VERSION ""

NS_ :

BS_:

BU_: Vector__XXX

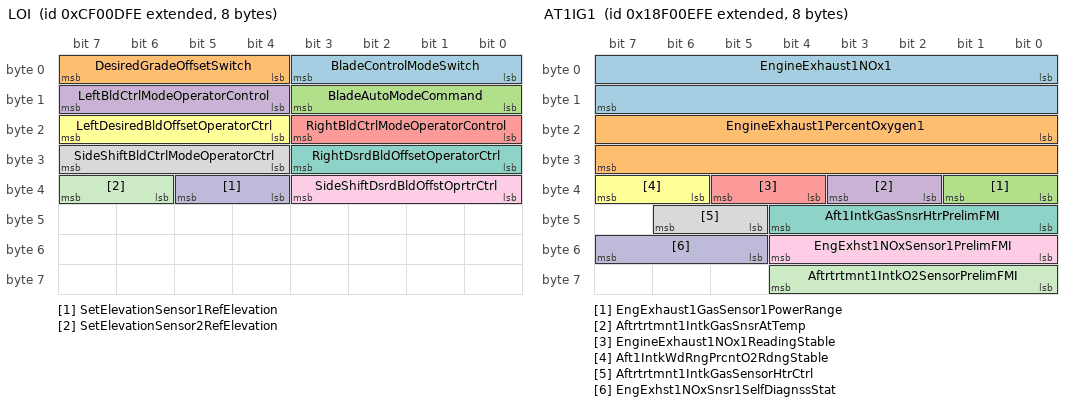
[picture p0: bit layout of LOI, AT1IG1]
BO_ 2364542462 LOI: 8 Vector__XXX
SG_ BladeControlModeSwitch : 0|4@1+ (1,0) [0|15] "" Vector__XXX
SG_ DesiredGradeOffsetSwitch : 4|4@1+ (1,0) [0|15] "" Vector__XXX
SG_ BladeAutoModeCommand : 8|4@1+ (1,0) [0|15] "" Vector__XXX
SG_ LeftBldCtrlModeOperatorControl : 12|4@1+ (1,0) [0|15] "" Vector__XXX
SG_ RightBldCtrlModeOperatorControl : 16|4@1+ (1,0) [0|15] "" Vector__XXX
SG_ LeftDesiredBldOffsetOperatorCtrl : 20|4@1+ (1,0) [0|15] "" Vector__XXX
SG_ RightDsrdBldOffsetOperatorCtrl : 24|4@1+ (1,0) [0|15] "" Vector__XXX
SG_ SideShiftBldCtrlModeOperatorCtrl : 28|4@1+ (1,0) [0|15] "" Vector__XXX
SG_ SideShiftDsrdBldOffstOprtrCtrl : 32|4@1+ (1,0) [0|15] "" Vector__XXX
SG_ SetElevationSensor1RefElevation : 36|2@1+ (1,0) [0|3] "" Vector__XXX
SG_ SetElevationSensor2RefElevation : 38|2@1+ (1,0) [0|3] "" Vector__XXX

BO_ 2565869310 AT1IG1: 8 Vector__XXX
SG_ EngineExhaust1NOx1 : 0|16@1+ (0.05,-200) [-200|3012.75] "ppm" Vector__XXX
SG_ EngineExhaust1PercentOxygen1 : 16|16@1+ (0.000514,-12) [-12|21.02707] "%" Vector__XXX
SG_ EngExhaust1GasSensor1PowerRange : 32|2@1+ (1,0) [0|3] "" Vector__XXX
SG_ Aftrtrtmnt1IntkGasSnsrAtTemp : 34|2@1+ (1,0) [0|3] "" Vector__XXX
SG_ EngineExhaust1NOx1ReadingStable : 36|2@1+ (1,0) [0|3] "" Vector__XXX
SG_ Aft1IntkWdRngPrcntO2RdngStable : 38|2@1+ (1,0) [0|3] "" Vector__XXX
SG_ Aft1IntkGasSnsrHtrPrelimFMI : 40|5@1+ (1,0) [0|31] "" Vector__XXX
SG_ Aftrtrtmnt1IntkGasSensorHtrCtrl : 45|2@1+ (1,0) [0|3] "" Vector__XXX
SG_ EngExhst1NOxSensor1PrelimFMI : 48|5@1+ (1,0) [0|31] "" Vector__XXX
SG_ EngExhst1NOxSnsr1SelfDiagnssStat : 53|3@1+ (1,0) [0|7] "" Vector__XXX
SG_ Aftrtrtmnt1IntkO2SensorPrelimFMI : 56|5@1+ (1,0) [0|31] "" Vector__XXX

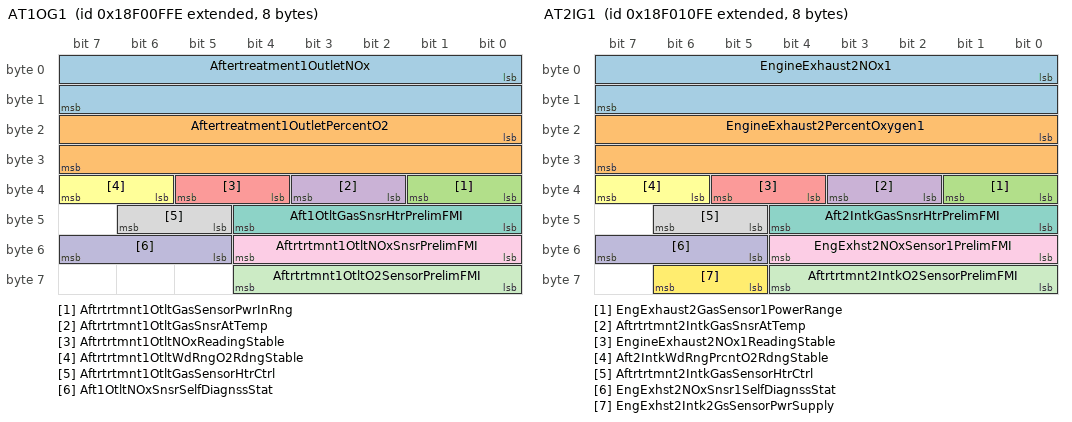
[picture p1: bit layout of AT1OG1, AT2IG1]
BO_ 2565869566 AT1OG1: 8 Vector__XXX
SG_ Aftertreatment1OutletNOx : 0|16@1+ (0.05,-200) [-200|3012.75] "ppm" Vector__XXX
SG_ Aftertreatment1OutletPercentO2 : 16|16@1+ (0.000514,-12) [-12|21.02707] "%" Vector__XXX
SG_ Aftrtrtmnt1OtltGasSensorPwrInRng : 32|2@1+ (1,0) [0|3] "" Vector__XXX
SG_ Aftrtrtmnt1OtltGasSnsrAtTemp : 34|2@1+ (1,0) [0|3] "" Vector__XXX
SG_ Aftrtrtmnt1OtltNOxReadingStable : 36|2@1+ (1,0) [0|3] "" Vector__XXX
SG_ Aftrtrtmnt1OtltWdRngO2RdngStable : 38|2@1+ (1,0) [0|3] "" Vector__XXX
SG_ Aft1OtltGasSnsrHtrPrelimFMI : 40|5@1+ (1,0) [0|31] "" Vector__XXX
SG_ Aftrtrtmnt1OtltGasSensorHtrCtrl : 45|2@1+ (1,0) [0|3] "" Vector__XXX
SG_ Aftrtrtmnt1OtltNOxSnsrPrelimFMI : 48|5@1+ (1,0) [0|31] "" Vector__XXX
SG_ Aft1OtltNOxSnsrSelfDiagnssStat : 53|3@1+ (1,0) [0|7] "" Vector__XXX
SG_ Aftrtrtmnt1OtltO2SensorPrelimFMI : 56|5@1+ (1,0) [0|31] "" Vector__XXX

BO_ 2565869822 AT2IG1: 8 Vector__XXX
SG_ EngineExhaust2NOx1 : 0|16@1+ (0.05,-200) [-200|3012.75] "ppm" Vector__XXX
SG_ EngineExhaust2PercentOxygen1 : 16|16@1+ (0.000514,-12) [-12|21.02707] "%" Vector__XXX
SG_ EngExhaust2GasSensor1PowerRange : 32|2@1+ (1,0) [0|3] "" Vector__XXX
SG_ Aftrtrtmnt2IntkGasSnsrAtTemp : 34|2@1+ (1,0) [0|3] "" Vector__XXX
SG_ EngineExhaust2NOx1ReadingStable : 36|2@1+ (1,0) [0|3] "" Vector__XXX
SG_ Aft2IntkWdRngPrcntO2RdngStable : 38|2@1+ (1,0) [0|3] "" Vector__XXX
SG_ Aft2IntkGasSnsrHtrPrelimFMI : 40|5@1+ (1,0) [0|31] "" Vector__XXX
SG_ Aftrtrtmnt2IntkGasSensorHtrCtrl : 45|2@1+ (1,0) [0|3] "" Vector__XXX
SG_ EngExhst2NOxSensor1PrelimFMI : 48|5@1+ (1,0) [0|31] "" Vector__XXX
SG_ EngExhst2NOxSnsr1SelfDiagnssStat : 53|3@1+ (1,0) [0|7] "" Vector__XXX
SG_ Aftrtrtmnt2IntkO2SensorPrelimFMI : 56|5@1+ (1,0) [0|31] "" Vector__XXX
SG_ EngExhst2Intk2GsSensorPwrSupply : 61|2@1+ (1,0) [0|3] "" Vector__XXX

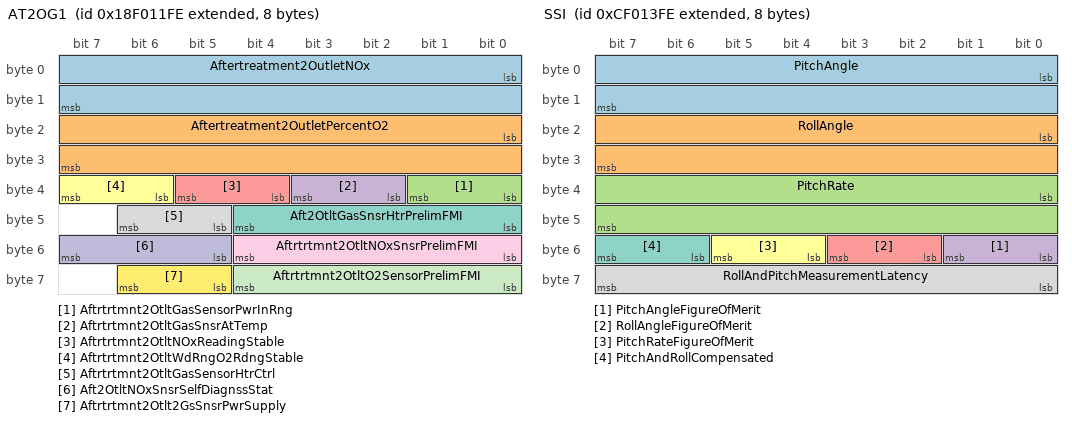
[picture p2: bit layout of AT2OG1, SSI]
BO_ 2565870078 AT2OG1: 8 Vector__XXX
SG_ Aftertreatment2OutletNOx : 0|16@1+ (0.05,-200) [-200|3012.75] "ppm" Vector__XXX
SG_ Aftertreatment2OutletPercentO2 : 16|16@1+ (0.000514,-12) [-12|21.02707] "%" Vector__XXX
SG_ Aftrtrtmnt2OtltGasSensorPwrInRng : 32|2@1+ (1,0) [0|3] "" Vector__XXX
SG_ Aftrtrtmnt2OtltGasSnsrAtTemp : 34|2@1+ (1,0) [0|3] "" Vector__XXX
SG_ Aftrtrtmnt2OtltNOxReadingStable : 36|2@1+ (1,0) [0|3] "" Vector__XXX
SG_ Aftrtrtmnt2OtltWdRngO2RdngStable : 38|2@1+ (1,0) [0|3] "" Vector__XXX
SG_ Aft2OtltGasSnsrHtrPrelimFMI : 40|5@1+ (1,0) [0|31] "" Vector__XXX
SG_ Aftrtrtmnt2OtltGasSensorHtrCtrl : 45|2@1+ (1,0) [0|3] "" Vector__XXX
SG_ Aftrtrtmnt2OtltNOxSnsrPrelimFMI : 48|5@1+ (1,0) [0|31] "" Vector__XXX
SG_ Aft2OtltNOxSnsrSelfDiagnssStat : 53|3@1+ (1,0) [0|7] "" Vector__XXX
SG_ Aftrtrtmnt2OtltO2SensorPrelimFMI : 56|5@1+ (1,0) [0|31] "" Vector__XXX
SG_ Aftrtrtmnt2Otlt2GsSnsrPwrSupply : 61|2@1+ (1,0) [0|3] "" Vector__XXX

BO_ 2565870334 FWSS1: 8 Vector__XXX
SG_ FifthWheelVerticalForce : 0|16@1+ (5,0) [0|321275] "N" Vector__XXX
SG_ FifthWheelDrawbarForce : 16|16@1+ (10,-320000) [-320000|322550] "N" Vector__XXX
SG_ FifthWheelRollMoment : 32|16@1+ (10,-320000) [-320000|322550] "N" Vector__XXX
SG_ FifthWheelRollWarningIndicator : 48|2@1+ (1,0) [0|3] "" Vector__XXX

BO_ 2364543998 SSI: 8 Vector__XXX
SG_ PitchAngle : 0|16@1+ (0.002,-64) [-64|64.51] "deg" Vector__XXX
SG_ RollAngle : 16|16@1+ (0.002,-64) [-64|64.51] "deg" Vector__XXX
SG_ PitchRate : 32|16@1+ (0.002,-64) [-64|64.51] "deg/s" Vector__XXX
SG_ PitchAngleFigureOfMerit : 48|2@1+ (1,0) [0|3] "" Vector__XXX
SG_ RollAngleFigureOfMerit : 50|2@1+ (1,0) [0|3] "" Vector__XXX
SG_ PitchRateFigureOfMerit : 52|2@1+ (1,0) [0|3] "" Vector__XXX
SG_ PitchAndRollCompensated : 54|2@1+ (1,0) [0|3] "" Vector__XXX
SG_ RollAndPitchMeasurementLatency : 56|8@1+ (0.5,0) [0|125] "ms" Vector__XXX

BO_ 2364544254 BI: 8 Vector__XXX
SG_ RelativeBladeHeight : 0|16@1+ (0.1,-3200) [-3200|3225.5] "mm" Vector__XXX
SG_ BladeRotationAngle : 16|16@1+ (0.0078125,-200) [-200|301.99] "deg" Vector__XXX
SG_ RelBldHghtAndBldRotAglMeasureLat : 32|8@1+ (0.5,0) [0|125] "ms" Vector__XXX
SG_ RelativeBladeHeightFigureOfMerit : 40|2@1+ (1,0) [0|3] "" Vector__XXX
SG_ BladeRotationAngleFigureOfMerit : 42|2@1+ (1,0) [0|3] "" Vector__XXX

BO_ 2364544510 RGTACRP: 8 Vector__XXX
SG_ RequestedGenTotalACReActvPower : 0|32@1+ (1,-2000000000) [-2000000000|2211081215] "VA" Vector__XXX
SG_ RequestedGenOverallPowerFactor : 32|16@1+ (6.103515625E-005,-1) [-1|2.921814] "" Vector__XXX
SG_ RqedGenOverallPwrFactorLagging : 48|2@1+ (1,0) [0|3] "" Vector__XXX

BO_ 2364544766 CCS: 8 Vector__XXX
SG_ EngineCylinder1CombustionStatus : 0|2@1+ (1,0) [0|3] "" Vector__XXX
SG_ EngineCylinder2CombustionStatus : 2|2@1+ (1,0) [0|3] "" Vector__XXX
SG_ EngineCylinder3CombustionStatus : 4|2@1+ (1,0) [0|3] "" Vector__XXX
SG_ EngineCylinder4CombustionStatus : 6|2@1+ (1,0) [0|3] "" Vector__XXX
SG_ EngineCylinder5CombustionStatus : 8|2@1+ (1,0) [0|3] "" Vector__XXX
SG_ EngineCylinder6CombustionStatus : 10|2@1+ (1,0) [0|3] "" Vector__XXX
SG_ EngineCylinder7CombustionStatus : 12|2@1+ (1,0) [0|3] "" Vector__XXX
SG_ EngineCylinder8CombustionStatus : 14|2@1+ (1,0) [0|3] "" Vector__XXX
SG_ EngineCylinder9CombustionStatus : 16|2@1+ (1,0) [0|3] "" Vector__XXX
SG_ EngineCylinder10CombustionStatus : 18|2@1+ (1,0) [0|3] "" Vector__XXX
SG_ EngineCylinder11CombustionStatus : 20|2@1+ (1,0) [0|3] "" Vector__XXX
SG_ EngineCylinder12CombustionStatus : 22|2@1+ (1,0) [0|3] "" Vector__XXX
SG_ EngineCylinder13CombustionStatus : 24|2@1+ (1,0) [0|3] "" Vector__XXX
SG_ EngineCylinder14CombustionStatus : 26|2@1+ (1,0) [0|3] "" Vector__XXX
SG_ EngineCylinder15CombustionStatus : 28|2@1+ (1,0) [0|3] "" Vector__XXX
SG_ EngineCylinder16CombustionStatus : 30|2@1+ (1,0) [0|3] "" Vector__XXX
SG_ EngineCylinder17CombustionStatus : 32|2@1+ (1,0) [0|3] "" Vector__XXX
SG_ EngineCylinder18CombustionStatus : 34|2@1+ (1,0) [0|3] "" Vector__XXX
SG_ EngineCylinder19CombustionStatus : 36|2@1+ (1,0) [0|3] "" Vector__XXX
SG_ EngineCylinder20CombustionStatus : 38|2@1+ (1,0) [0|3] "" Vector__XXX
SG_ EngineCylinder21CombustionStatus : 40|2@1+ (1,0) [0|3] "" Vector__XXX
SG_ EngineCylinder22CombustionStatus : 42|2@1+ (1,0) [0|3] "" Vector__XXX
SG_ EngineCylinder23CombustionStatus : 44|2@1+ (1,0) [0|3] "" Vector__XXX
SG_ EngineCylinder24CombustionStatus : 46|2@1+ (1,0) [0|3] "" Vector__XXX

BO_ 2364545022 KL1: 8 Vector__XXX
SG_ EngineCylinder1KnockLevel : 0|8@1+ (1,0) [0|250] "%" Vector__XXX
SG_ EngineCylinder2KnockLevel : 8|8@1+ (1,0) [0|250] "%" Vector__XXX
SG_ EngineCylinder3KnockLevel : 16|8@1+ (1,0) [0|250] "%" Vector__XXX
SG_ EngineCylinder4KnockLevel : 24|8@1+ (1,0) [0|250] "%" Vector__XXX
SG_ EngineCylinder5KnockLevel : 32|8@1+ (1,0) [0|250] "%" Vector__XXX
SG_ EngineCylinder6KnockLevel : 40|8@1+ (1,0) [0|250] "%" Vector__XXX
SG_ EngineCylinder7KnockLevel : 48|8@1+ (1,0) [0|250] "%" Vector__XXX
SG_ EngineCylinder8KnockLevel : 56|8@1+ (1,0) [0|250] "%" Vector__XXX

BO_ 2364545278 KL2: 8 Vector__XXX
SG_ EngineCylinder9KnockLevel : 0|8@1+ (1,0) [0|250] "%" Vector__XXX
SG_ EngineCylinder10KnockLevel : 8|8@1+ (1,0) [0|250] "%" Vector__XXX
SG_ EngineCylinder11KnockLevel : 16|8@1+ (1,0) [0|250] "%" Vector__XXX
SG_ EngineCylinder12KnockLevel : 24|8@1+ (1,0) [0|250] "%" Vector__XXX
SG_ EngineCylinder13KnockLevel : 32|8@1+ (1,0) [0|250] "%" Vector__XXX
SG_ EngineCylinder14KnockLevel : 40|8@1+ (1,0) [0|250] "%" Vector__XXX
SG_ EngineCylinder15KnockLevel : 48|8@1+ (1,0) [0|250] "%" Vector__XXX
SG_ EngineCylinder16KnockLevel : 56|8@1+ (1,0) [0|250] "%" Vector__XXX

BO_ 2364545534 KL3: 8 Vector__XXX
SG_ EngineCylinder17KnockLevel : 0|8@1+ (1,0) [0|250] "%" Vector__XXX
SG_ EngineCylinder18KnockLevel : 8|8@1+ (1,0) [0|250] "%" Vector__XXX
SG_ EngineCylinder19KnockLevel : 16|8@1+ (1,0) [0|250] "%" Vector__XXX
SG_ EngineCylinder20KnockLevel : 24|8@1+ (1,0) [0|250] "%" Vector__XXX
SG_ EngineCylinder21KnockLevel : 32|8@1+ (1,0) [0|250] "%" Vector__XXX
SG_ EngineCylinder22KnockLevel : 40|8@1+ (1,0) [0|250] "%" Vector__XXX
SG_ EngineCylinder23KnockLevel : 48|8@1+ (1,0) [0|250] "%" Vector__XXX
SG_ EngineCylinder24KnockLevel : 56|8@1+ (1,0) [0|250] "%" Vector__XXX

BO_ 2431654654 TFAC: 8 Vector__XXX
SG_ EngineThrottleActr1ControlCmd : 0|16@1+ (0.0025,0) [0|160.6375] "%" Vector__XXX
SG_ EngineThrottleActr2ControlCmd : 16|16@1+ (0.0025,0) [0|160.6375] "%" Vector__XXX
SG_ EngineFuelActr1ControlCommand : 32|16@1+ (0.0025,0) [0|160.6375] "%" Vector__XXX
SG_ EngineFuelActr2ControlCommand : 48|16@1+ (0.0025,0) [0|160.6375] "%" Vector__XXX

BO_ 2364546302 RGAAC: 8 Vector__XXX
SG_ RqedGenAvrgLineLineACRMSVoltage : 0|32@1+ (0.0078125,0) [0|32899071] "V" Vector__XXX

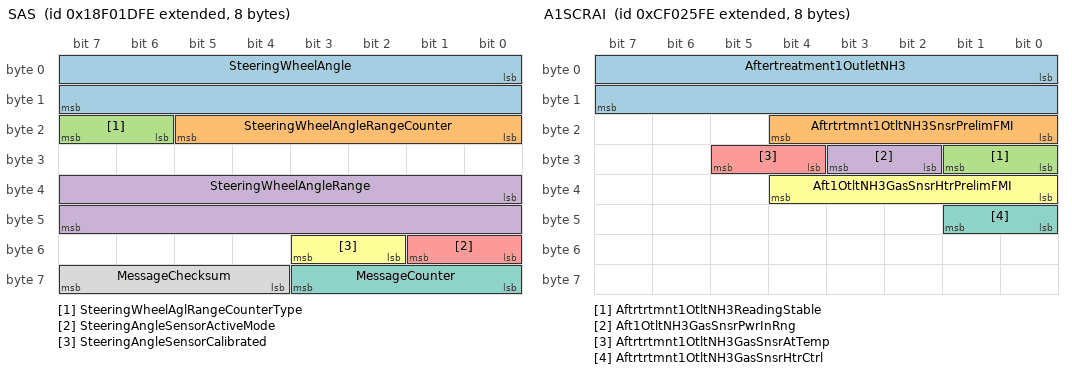
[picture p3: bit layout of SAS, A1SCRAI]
BO_ 2565873150 SAS: 8 Vector__XXX
SG_ SteeringWheelAngle : 0|16@1+ (0.0009765625,-31.374) [-31.374|31.374] "rad" Vector__XXX
SG_ SteeringWheelAngleRangeCounter : 16|6@1+ (1,-32) [-32|29] "" Vector__XXX
SG_ SteeringWheelAglRangeCounterType : 22|2@1+ (1,0) [0|3] "" Vector__XXX
SG_ SteeringWheelAngleRange : 32|16@1+ (0.0009765625,-31.374) [-31.374|31.374] "rad" Vector__XXX
SG_ SteeringAngleSensorActiveMode : 48|2@1+ (1,0) [0|3] "" Vector__XXX
SG_ SteeringAngleSensorCalibrated : 50|2@1+ (1,0) [0|3] "" Vector__XXX
SG_ MessageCounter : 56|4@1+ (1,0) [0|15] "" Vector__XXX
SG_ MessageChecksum : 60|4@1+ (1,0) [0|15] "" Vector__XXX

BO_ 2364546814 GC2: 8 Vector__XXX
SG_ GeneratorGoverningBias : 0|16@1+ (0.004,-125) [-125|132.02] "%" Vector__XXX
SG_ EngineSelfInducedDerateInhibit : 16|2@1+ (1,0) [0|3] "" Vector__XXX
SG_ EngineLoadSetpointRequest : 24|16@1+ (0.5,0) [0|32127.5] "kW" Vector__XXX

BO_ 2565874174 ESSI1: 8 Vector__XXX
SG_ EngineSpeed1 : 0|16@1+ (0.5,0) [0|32127.5] "rpm" Vector__XXX
SG_ EngineSpeed2 : 16|16@1+ (0.5,0) [0|32127.5] "rpm" Vector__XXX
SG_ EngineSpeed3 : 32|16@1+ (0.5,0) [0|32127.5] "rpm" Vector__XXX
SG_ EngSpeedSnsr3TimingPatternStatus : 50|2@1+ (1,0) [0|3] "" Vector__XXX
SG_ EngSpeedSnsr2TimingPatternStatus : 52|2@1+ (1,0) [0|3] "" Vector__XXX
SG_ EngSpeedSnsr1TimingPatternStatus : 54|2@1+ (1,0) [0|3] "" Vector__XXX

BO_ 2565874430 MSS: 8 Vector__XXX
SG_ MachineSelectedSpeed : 0|16@1+ (0.001,0) [0|64.255] "m/s" Vector__XXX
SG_ MachineSelectedDistance : 16|32@1+ (0.001,0) [0|4211081.215] "m" Vector__XXX
SG_ MachineSelectedDirection : 56|2@1+ (1,0) [0|3] "" Vector__XXX
SG_ MachineSelectedSpeedSource : 58|3@1+ (1,0) [0|7] "" Vector__XXX
SG_ PersistentLimitStatus : 61|3@1+ (1,0) [0|7] "" Vector__XXX

BO_ 2364548094 A1SCRDSI1: 8 Vector__XXX
SG_ Aft1DslExhstFldActlDsngQty : 0|16@1+ (0.3,0) [0|19276.5] "g/h" Vector__XXX
SG_ Aftertreatment1SCRSystemState : 16|4@1+ (1,0) [0|15] "" Vector__XXX
SG_ Aftertreatment1SCRSystem2State : 20|4@1+ (1,0) [0|15] "" Vector__XXX
SG_ Aft1DslExhstFldActlQtyOfIntgrtr : 24|16@1+ (0.1,0) [0|6425.5] "g" Vector__XXX
SG_ Aft1DslExhstFldDoserAbsPress : 40|8@1+ (8,0) [0|2000] "kPa" Vector__XXX
SG_ Aft1DslExhstFldActlDsngQtyHiRng : 48|16@1+ (0.05,0) [0|3212.75] "g/m" Vector__XXX

BO_ 2364548350 A1SCRDSR1: 8 Vector__XXX
SG_ Aft1DslExhstFldDsngRqedQty : 0|16@1+ (0.3,0) [0|19276.5] "g/h" Vector__XXX
SG_ Aftrtrtmnt1SCRSystemRqedState : 16|4@1+ (1,0) [0|15] "" Vector__XXX
SG_ Aft1DslExhstFldHydrStffnssCkPmSt : 20|2@1+ (1,0) [0|3] "" Vector__XXX
SG_ Aft1DslExhstFldDsngTtInjectPmSt : 22|2@1+ (1,0) [0|3] "" Vector__XXX
SG_ Aft1DslExhstFldRqedQtyOfIntgrtr : 24|16@1+ (0.1,0) [0|6425.5] "g" Vector__XXX
SG_ Aft1DslExhstFldDsngRqedQtyHiRng : 40|16@1+ (0.05,0) [0|3212.75] "g/m" Vector__XXX

BO_ 2364548606 A1SCRAI: 8 Vector__XXX
SG_ Aftertreatment1OutletNH3 : 0|16@1+ (0.05,-200) [-200|3012.75] "ppm" Vector__XXX
SG_ Aftrtrtmnt1OtltNH3SnsrPrelimFMI : 16|5@1+ (1,0) [0|31] "" Vector__XXX
SG_ Aftrtrtmnt1OtltNH3ReadingStable : 24|2@1+ (1,0) [0|3] "" Vector__XXX
SG_ Aft1OtltNH3GasSnsrPwrInRng : 26|2@1+ (1,0) [0|3] "" Vector__XXX
SG_ Aftrtrtmnt1OtltNH3GasSnsrAtTemp : 28|2@1+ (1,0) [0|3] "" Vector__XXX
SG_ Aft1OtltNH3GasSnsrHtrPrelimFMI : 32|5@1+ (1,0) [0|31] "" Vector__XXX
SG_ Aftrtrtmnt1OtltNH3GasSnsrHtrCtrl : 40|2@1+ (1,0) [0|3] "" Vector__XXX

BO_ 2364548862 A2SCRDSI1: 8 Vector__XXX
SG_ Aft2DslExhstFldActlDsngQty : 0|16@1+ (0.3,0) [0|19276.5] "g/h" Vector__XXX
SG_ Aftertreatment2SCRSystemState : 16|4@1+ (1,0) [0|15] "" Vector__XXX
SG_ Aftertreatment2SCRSystem2State : 20|4@1+ (1,0) [0|15] "" Vector__XXX
SG_ Aft2DslExhstFldActlQtyOfIntgrtr : 24|16@1+ (0.1,0) [0|6425.5] "g" Vector__XXX
SG_ Aft2DslExhstFldDsngAbsPress : 40|8@1+ (8,0) [0|2000] "kPa" Vector__XXX
SG_ Aft2DslExhstFldActlDsngQtyHiRng : 48|16@1+ (0.05,0) [0|3212.75] "g/m" Vector__XXX

BO_ 2364549118 A2SCRDSR1: 8 Vector__XXX
SG_ Aft2DslExhstFldDsngRqedQty : 0|16@1+ (0.3,0) [0|19276.5] "g/h" Vector__XXX
SG_ Aftrtrtmnt2SCRSystemRqedState : 16|4@1+ (1,0) [0|15] "" Vector__XXX
SG_ Aft2DslExhstFldHydrStffnssCkPmSt : 20|2@1+ (1,0) [0|3] "" Vector__XXX
SG_ Aft2DslExhstFldDsngTtInjectPmSt : 22|2@1+ (1,0) [0|3] "" Vector__XXX
SG_ Aft2DslExhstFldRqedQtyOfIntgrtr : 24|16@1+ (0.1,0) [0|6425.5] "g" Vector__XXX
SG_ Aft2DslExhstFldDsngRqedQtyHiRng : 40|16@1+ (0.05,0) [0|3212.75] "g/m" Vector__XXX
SG_ Aftrtrtmnt2DslExhstFldPumpHtrCmd : 56|8@1+ (0.4,0) [0|100] "%" Vector__XXX

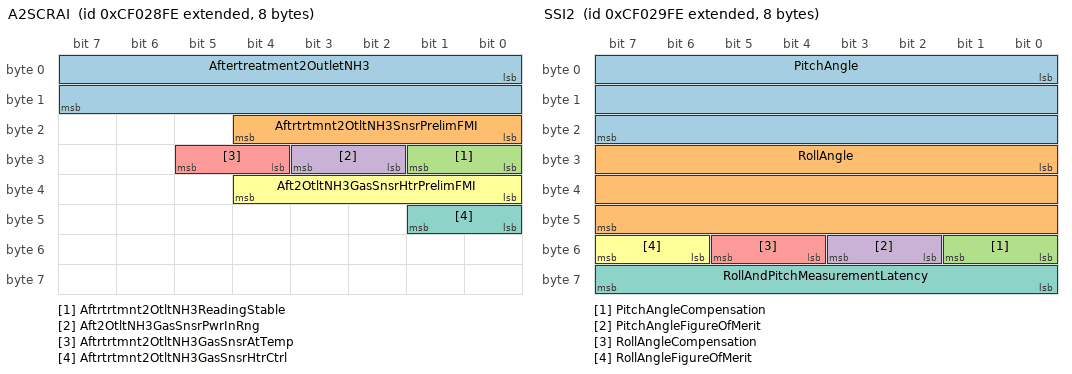
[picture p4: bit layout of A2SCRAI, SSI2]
BO_ 2364549374 A2SCRAI: 8 Vector__XXX
SG_ Aftertreatment2OutletNH3 : 0|16@1+ (0.05,-200) [-200|3012.75] "ppm" Vector__XXX
SG_ Aftrtrtmnt2OtltNH3SnsrPrelimFMI : 16|5@1+ (1,0) [0|31] "" Vector__XXX
SG_ Aftrtrtmnt2OtltNH3ReadingStable : 24|2@1+ (1,0) [0|3] "" Vector__XXX
SG_ Aft2OtltNH3GasSnsrPwrInRng : 26|2@1+ (1,0) [0|3] "" Vector__XXX
SG_ Aftrtrtmnt2OtltNH3GasSnsrAtTemp : 28|2@1+ (1,0) [0|3] "" Vector__XXX
SG_ Aft2OtltNH3GasSnsrHtrPrelimFMI : 32|5@1+ (1,0) [0|31] "" Vector__XXX
SG_ Aftrtrtmnt2OtltNH3GasSnsrHtrCtrl : 40|2@1+ (1,0) [0|3] "" Vector__XXX

BO_ 2364549630 SSI2: 8 Vector__XXX
SG_ PitchAngle : 0|24@1+ (3.0517578125E-005,-250) [-250|252] "deg" Vector__XXX
SG_ RollAngle : 24|24@1+ (3.0517578125E-005,-250) [-250|252] "deg" Vector__XXX
SG_ PitchAngleCompensation : 48|2@1+ (1,0) [0|3] "" Vector__XXX
SG_ PitchAngleFigureOfMerit : 50|2@1+ (1,0) [0|3] "" Vector__XXX
SG_ RollAngleCompensation : 52|2@1+ (1,0) [0|3] "" Vector__XXX
SG_ RollAngleFigureOfMerit : 54|2@1+ (1,0) [0|3] "" Vector__XXX
SG_ RollAndPitchMeasurementLatency : 56|8@1+ (0.5,0) [0|125] "ms" Vector__XXX

BO_ 2364549886 ARI: 8 Vector__XXX
SG_ PitchRate : 0|16@1+ (0.0078125,-250) [-250|250.992] "deg/s" Vector__XXX
SG_ RollRate : 16|16@1+ (0.0078125,-250) [-250|250.992] "deg/s" Vector__XXX
SG_ YawRate : 32|16@1+ (0.0078125,-250) [-250|250.992] "deg/s" Vector__XXX
SG_ PitchRateFigureOfMerit : 48|2@1+ (1,0) [0|3] "" Vector__XXX
SG_ RollRateFigureOfMerit : 50|2@1+ (1,0) [0|3] "" Vector__XXX
SG_ YawRateFigureOfMerit : 52|2@1+ (1,0) [0|3] "" Vector__XXX
SG_ AngularRateMeasurementLatency : 56|8@1+ (0.5,0) [0|125] "ms" Vector__XXX

BO_ 2163223550 CN: 8 Vector__XXX
SG_ CrashType : 0|5@1+ (1,0) [0|31] "" Vector__XXX
SG_ CrashCounter : 56|4@1+ (1,0) [0|15] "" Vector__XXX
SG_ CrashChecksum : 60|4@1+ (1,0) [0|15] "" Vector__XXX

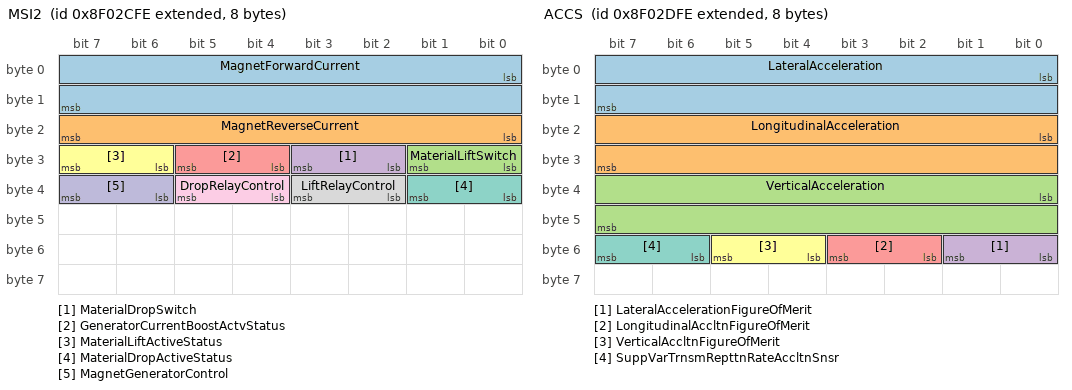
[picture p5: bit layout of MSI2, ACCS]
BO_ 2297441534 MSI2: 8 Vector__XXX
SG_ MagnetForwardCurrent : 0|16@1+ (1,0) [0|64255] "A" Vector__XXX
SG_ MagnetReverseCurrent : 16|8@1+ (1,0) [0|250] "A" Vector__XXX
SG_ MaterialLiftSwitch : 24|2@1+ (1,0) [0|3] "" Vector__XXX
SG_ MaterialDropSwitch : 26|2@1+ (1,0) [0|3] "" Vector__XXX
SG_ GeneratorCurrentBoostActvStatus : 28|2@1+ (1,0) [0|3] "" Vector__XXX
SG_ MaterialLiftActiveStatus : 30|2@1+ (1,0) [0|3] "" Vector__XXX
SG_ MaterialDropActiveStatus : 32|2@1+ (1,0) [0|3] "" Vector__XXX
SG_ LiftRelayControl : 34|2@1+ (1,0) [0|3] "" Vector__XXX
SG_ DropRelayControl : 36|2@1+ (1,0) [0|3] "" Vector__XXX
SG_ MagnetGeneratorControl : 38|2@1+ (1,0) [0|3] "" Vector__XXX

BO_ 2297441790 ACCS: 8 Vector__XXX
SG_ LateralAcceleration : 0|16@1+ (0.01,-320) [-320|322.55] "m/s^2" Vector__XXX
SG_ LongitudinalAcceleration : 16|16@1+ (0.01,-320) [-320|322.55] "m/s^2" Vector__XXX
SG_ VerticalAcceleration : 32|16@1+ (0.01,-320) [-320|322.55] "m/s^2" Vector__XXX
SG_ LateralAccelerationFigureOfMerit : 48|2@1+ (1,0) [0|3] "" Vector__XXX
SG_ LongitudinalAccltnFigureOfMerit : 50|2@1+ (1,0) [0|3] "" Vector__XXX
SG_ VerticalAccltnFigureOfMerit : 52|2@1+ (1,0) [0|3] "" Vector__XXX
SG_ SuppVarTrnsmRepttnRateAccltnSnsr : 54|2@1+ (1,0) [0|3] "" Vector__XXX

BO_ 2565877502 ETCC: 8 Vector__XXX
SG_ EngTurbochargerWastegateActr1Cmd : 0|16@1+ (0.0025,0) [0|160.6375] "%" Vector__XXX
SG_ EngTurbochargerWastegateActr2Cmd : 16|16@1+ (0.0025,0) [0|160.6375] "%" Vector__XXX
SG_ EngExhstPressureRegulatorCtrlCmd : 32|16@1+ (0.0025,0) [0|160.6375] "%" Vector__XXX
SG_ EngTurboCmprssorBlowoffActr1Cmd : 48|16@1+ (0.0025,0) [0|160.6375] "%" Vector__XXX

BO_ 2364551166 AEBS1: 8 Vector__XXX
SG_ AdvEmergencyBrakingSystemState : 0|4@1+ (1,0) [0|15] "" Vector__XXX
SG_ CollisionWarningLevel : 4|4@1+ (1,0) [0|15] "" Vector__XXX
SG_ RelvntObjDetctAdvEmrgncyBrkngSys : 8|3@1+ (1,0) [0|7] "" Vector__XXX
SG_ BendOffProbabilityOfRelevantObj : 11|3@1+ (1,0) [0|7] "" Vector__XXX
SG_ TimeToCollsnWithRelevantObject : 16|8@1+ (0.05,0) [0|12.5] "s" Vector__XXX
SG_ RoadDepartrAdvEmrgBrkngSysStat : 24|4@1+ (1,0) [0|15] "" Vector__XXX

BO_ 2364551422 WS: 8 Vector__XXX
SG_ WirelessRollingMessageCounter : 0|16@1+ (1,0) [0|64255] "" Vector__XXX
SG_ TransmitterCommandState : 20|4@1+ (1,0) [0|15] "" Vector__XXX
SG_ TransmitterID1 : 24|24@1+ (1,0) [0|16449635] "" Vector__XXX
SG_ WirelessSignalStrength1 : 48|8@1+ (0.5,-125) [-125|0] "dBm" Vector__XXX

BO_ 2230333950 WAND: 8 Vector__XXX
SG_ WandAngle : 0|16@1+ (0.002,-64) [-64|64.51] "deg" Vector__XXX
SG_ WandSensorFigureOfMerit : 16|2@1+ (1,0) [0|3] "" Vector__XXX

BO_ 2230334206 LDISP: 8 Vector__XXX
SG_ MeasuredLinearDisplacement : 0|16@1+ (0.1,0) [0|6425.5] "mm" Vector__XXX
SG_ LnrDisplacmntSnsrSnsrFigOfMerit : 16|2@1+ (1,0) [0|3] "" Vector__XXX

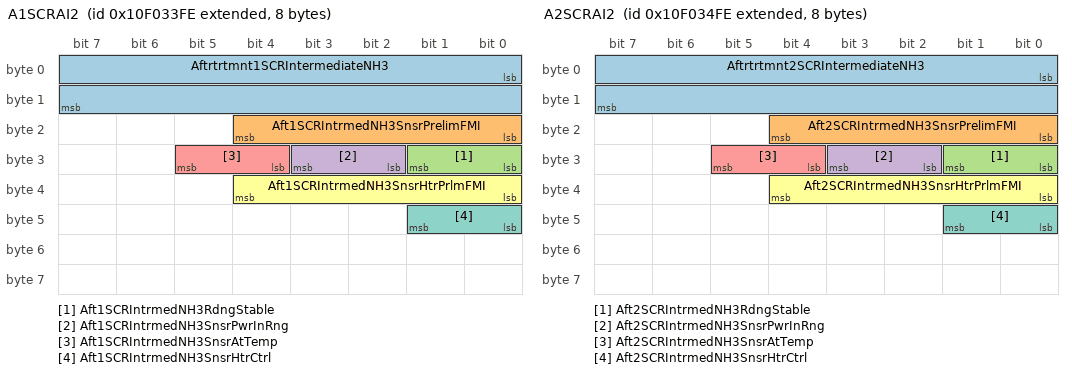
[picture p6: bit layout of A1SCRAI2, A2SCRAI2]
BO_ 2431661054 A1SCRAI2: 8 Vector__XXX
SG_ Aftrtrtmnt1SCRIntermediateNH3 : 0|16@1+ (0.1,-200) [-200|6225.5] "ppm" Vector__XXX
SG_ Aft1SCRIntrmedNH3SnsrPrelimFMI : 16|5@1+ (1,0) [0|31] "" Vector__XXX
SG_ Aft1SCRIntrmedNH3RdngStable : 24|2@1+ (1,0) [0|3] "" Vector__XXX
SG_ Aft1SCRIntrmedNH3SnsrPwrInRng : 26|2@1+ (1,0) [0|3] "" Vector__XXX
SG_ Aft1SCRIntrmedNH3SnsrAtTemp : 28|2@1+ (1,0) [0|3] "" Vector__XXX
SG_ Aft1SCRIntrmedNH3SnsrHtrPrlmFMI : 32|5@1+ (1,0) [0|31] "" Vector__XXX
SG_ Aft1SCRIntrmedNH3SnsrHtrCtrl : 40|2@1+ (1,0) [0|3] "" Vector__XXX

BO_ 2431661310 A2SCRAI2: 8 Vector__XXX
SG_ Aftrtrtmnt2SCRIntermediateNH3 : 0|16@1+ (0.1,-200) [-200|6225.5] "ppm" Vector__XXX
SG_ Aft2SCRIntrmedNH3SnsrPrelimFMI : 16|5@1+ (1,0) [0|31] "" Vector__XXX
SG_ Aft2SCRIntrmedNH3RdngStable : 24|2@1+ (1,0) [0|3] "" Vector__XXX
SG_ Aft2SCRIntrmedNH3SnsrPwrInRng : 26|2@1+ (1,0) [0|3] "" Vector__XXX
SG_ Aft2SCRIntrmedNH3SnsrAtTemp : 28|2@1+ (1,0) [0|3] "" Vector__XXX
SG_ Aft2SCRIntrmedNH3SnsrHtrPrlmFMI : 32|5@1+ (1,0) [0|31] "" Vector__XXX
SG_ Aft2SCRIntrmedNH3SnsrHtrCtrl : 40|2@1+ (1,0) [0|3] "" Vector__XXX

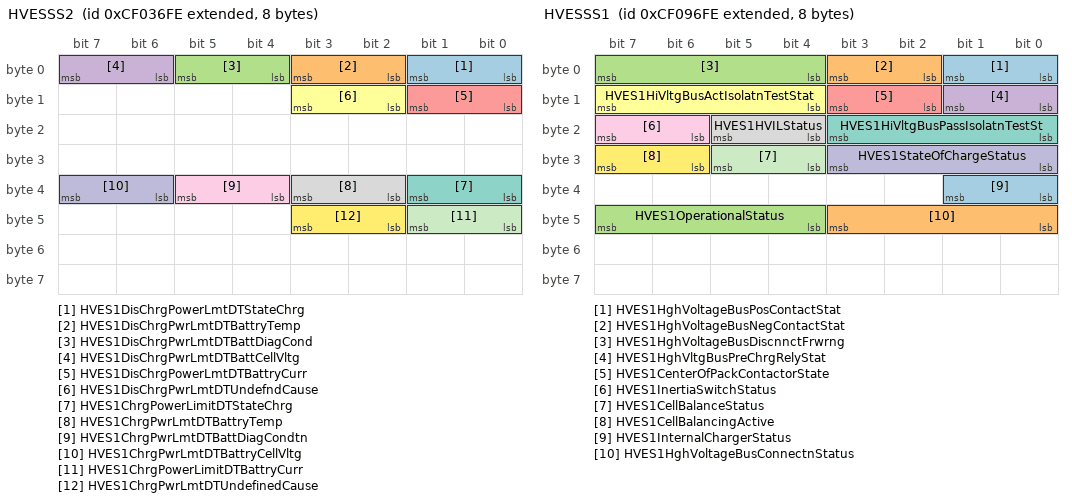
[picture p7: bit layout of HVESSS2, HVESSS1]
BO_ 2364552958 HVESSS2: 8 Vector__XXX
SG_ HVES1DisChrgPowerLmtDTStateChrg : 0|2@1+ (1,0) [0|3] "" Vector__XXX
SG_ HVES1DisChrgPwrLmtDTBattryTemp : 2|2@1+ (1,0) [0|3] "" Vector__XXX
SG_ HVES1DisChrgPwrLmtDTBattDiagCond : 4|2@1+ (1,0) [0|3] "" Vector__XXX
SG_ HVES1DisChrgPwrLmtDTBattCellVltg : 6|2@1+ (1,0) [0|3] "" Vector__XXX
SG_ HVES1DisChrgPowerLmtDTBattryCurr : 8|2@1+ (1,0) [0|3] "" Vector__XXX
SG_ HVES1DisChrgPwrLmtDTUndefndCause : 10|2@1+ (1,0) [0|3] "" Vector__XXX
SG_ HVES1ChrgPowerLimitDTStateChrg : 32|2@1+ (1,0) [0|3] "" Vector__XXX
SG_ HVES1ChrgPwrLmtDTBattryTemp : 34|2@1+ (1,0) [0|3] "" Vector__XXX
SG_ HVES1ChrgPwrLmtDTBattDiagCondtn : 36|2@1+ (1,0) [0|3] "" Vector__XXX
SG_ HVES1ChrgPwrLmtDTBattryCellVltg : 38|2@1+ (1,0) [0|3] "" Vector__XXX
SG_ HVES1ChrgPowerLimitDTBattryCurr : 40|2@1+ (1,0) [0|3] "" Vector__XXX
SG_ HVES1ChrgPwrLmtDTUndefinedCause : 42|2@1+ (1,0) [0|3] "" Vector__XXX

BO_ 2364553214 ETBA1: 8 Vector__XXX
SG_ EngTurboCmprBlowoffActr1PrlmFMI : 0|5@1+ (1,0) [0|31] "" Vector__XXX
SG_ EngTurboCmprBlowoffActr1TempStat : 5|3@1+ (1,0) [0|7] "" Vector__XXX
SG_ EngTurboCmprssorBlowoffActr1Temp : 8|8@1+ (1,-40) [-40|210] "deg C" Vector__XXX
SG_ EngTurboCmprBlowoffActr1DsrdPos : 16|8@1+ (0.4,0) [0|100] "%" Vector__XXX
SG_ EngTurboCmprssorBlowoffActr1Pos : 24|8@1+ (0.4,0) [0|100] "%" Vector__XXX
SG_ EngTurboCmprBlowoffActr1OpStat : 32|4@1+ (1,0) [0|15] "" Vector__XXX

BO_ 2364553470 ETFR: 8 Vector__XXX
SG_ EngGsSubstitutionFuelPrcntageCmd : 0|8@1+ (0.5,0) [0|125] "%" Vector__XXX
SG_ EngineCylinderGasMassFlowRateCmd : 8|16@1+ (6.103515625E-005,0) [0|3.921813965] "kg/s" Vector__XXX
SG_ EngineCylDieselMassFlowRateCmd : 24|16@1+ (6.103515625E-005,0) [0|3.921813965] "kg/s" Vector__XXX
SG_ EngineCylinderTorque : 40|16@1+ (1,0) [0|64255] "Nm" Vector__XXX
SG_ EngineDualFuelModeCommand : 56|2@1+ (1,0) [0|3] "" Vector__XXX

BO_ 2364553726 EASI: 8 Vector__XXX
SG_ EngineDesiredAirFuelRatio : 0|16@1+ (0.001,0) [0|64.255] "" Vector__XXX
SG_ EngineTotalIntakeMassAirFlowRate : 16|16@1+ (0.0009765625,0) [0|62.74902344] "kg/s" Vector__XXX
SG_ EngFuelSys2TtlIntkMassAirFlwRate : 32|16@1+ (0.0009765625,0) [0|62.74902344] "kg/s" Vector__XXX

BO_ 2364553982 ECCI1: 8 Vector__XXX
SG_ EngineCylinder1HeatRelease : 0|16@1+ (0.0001220703125,-1) [-1|6.84362793] "kJ/l" Vector__XXX
SG_ EngineCylinder1PeakPressure : 16|16@1+ (0.0009765625,0) [0|62.74902344] "MPa" Vector__XXX
SG_ EngineCyl1SynchronousKnockLevel : 32|8@1+ (1,0) [0|250] "%" Vector__XXX
SG_ EngCyl1PressureSensorPrelimFMI : 40|5@1+ (1,0) [0|31] "" Vector__XXX
SG_ EngineCyl1LowFrequencyKnockLevel : 48|8@1+ (1,0) [0|250] "%" Vector__XXX
SG_ EngCyl1MaxPressureIncreaseRate : 56|8@1+ (16,0) [0|4000] "kPa/deg crank an" Vector__XXX

BO_ 2364554238 ECCI2: 8 Vector__XXX
SG_ EngineCylinder2HeatRelease : 0|16@1+ (0.0001220703125,-1) [-1|6.84362793] "kJ/l" Vector__XXX
SG_ EngineCylinder2PeakPressure : 16|16@1+ (0.0009765625,0) [0|62.74902344] "MPa" Vector__XXX
SG_ EngineCyl2SynchronousKnockLevel : 32|8@1+ (1,0) [0|250] "%" Vector__XXX
SG_ EngCyl2PressureSensorPrelimFMI : 40|5@1+ (1,0) [0|31] "" Vector__XXX
SG_ EngineCyl2LowFrequencyKnockLevel : 48|8@1+ (1,0) [0|250] "%" Vector__XXX
SG_ EngCyl2MaxPressureIncreaseRate : 56|8@1+ (16,0) [0|4000] "kPa/deg crank an" Vector__XXX

BO_ 2364554494 ECCI3: 8 Vector__XXX
SG_ EngineCylinder3HeatRelease : 0|16@1+ (0.0001220703125,-1) [-1|6.84362793] "kJ/l" Vector__XXX
SG_ EngineCylinder3PeakPressure : 16|16@1+ (0.0009765625,0) [0|62.74902344] "MPa" Vector__XXX
SG_ EngineCyl3SynchronousKnockLevel : 32|8@1+ (1,0) [0|250] "%" Vector__XXX
SG_ EngCyl3PressureSensorPrelimFMI : 40|5@1+ (1,0) [0|31] "" Vector__XXX
SG_ EngineCyl3LowFrequencyKnockLevel : 48|8@1+ (1,0) [0|250] "%" Vector__XXX
SG_ EngCyl3MaxPressureIncreaseRate : 56|8@1+ (16,0) [0|4000] "kPa/deg crank an" Vector__XXX

BO_ 2364554750 ECCI4: 8 Vector__XXX
SG_ EngineCylinder4HeatRelease : 0|16@1+ (0.0001220703125,-1) [-1|6.84362793] "kJ/l" Vector__XXX
SG_ EngineCylinder4PeakPressure : 16|16@1+ (0.0009765625,0) [0|62.74902344] "MPa" Vector__XXX
SG_ EngineCyl4SynchronousKnockLevel : 32|8@1+ (1,0) [0|250] "%" Vector__XXX
SG_ EngCyl4PressureSensorPrelimFMI : 40|5@1+ (1,0) [0|31] "" Vector__XXX
SG_ EngineCyl4LowFrequencyKnockLevel : 48|8@1+ (1,0) [0|250] "%" Vector__XXX
SG_ EngCyl4MaxPressureIncreaseRate : 56|8@1+ (16,0) [0|4000] "kPa/deg crank an" Vector__XXX

BO_ 2364555006 ECCI5: 8 Vector__XXX
SG_ EngineCylinder5HeatRelease : 0|16@1+ (0.0001220703125,-1) [-1|6.84362793] "kJ/l" Vector__XXX
SG_ EngineCylinder5PeakPressure : 16|16@1+ (0.0009765625,0) [0|62.74902344] "MPa" Vector__XXX
SG_ EngineCyl5SynchronousKnockLevel : 32|8@1+ (1,0) [0|250] "%" Vector__XXX
SG_ EngCyl5PressureSensorPrelimFMI : 40|5@1+ (1,0) [0|31] "" Vector__XXX
SG_ EngineCyl5LowFrequencyKnockLevel : 48|8@1+ (1,0) [0|250] "%" Vector__XXX
SG_ EngCyl5MaxPressureIncreaseRate : 56|8@1+ (16,0) [0|4000] "kPa/deg crank an" Vector__XXX

BO_ 2364555262 ECCI6: 8 Vector__XXX
SG_ EngineCylinder6HeatRelease : 0|16@1+ (0.0001220703125,-1) [-1|6.84362793] "kJ/l" Vector__XXX
SG_ EngineCylinder6PeakPressure : 16|16@1+ (0.0009765625,0) [0|62.74902344] "MPa" Vector__XXX
SG_ EngineCyl6SynchronousKnockLevel : 32|8@1+ (1,0) [0|250] "%" Vector__XXX
SG_ EngCyl6PressureSensorPrelimFMI : 40|5@1+ (1,0) [0|31] "" Vector__XXX
SG_ EngineCyl6LowFrequencyKnockLevel : 48|8@1+ (1,0) [0|250] "%" Vector__XXX
SG_ EngCyl6MaxPressureIncreaseRate : 56|8@1+ (16,0) [0|4000] "kPa/deg crank an" Vector__XXX

BO_ 2364555518 ECCI7: 8 Vector__XXX
SG_ EngineCylinder7HeatRelease : 0|16@1+ (0.0001220703125,-1) [-1|6.84362793] "kJ/l" Vector__XXX
SG_ EngineCylinder7PeakPressure : 16|16@1+ (0.0009765625,0) [0|62.74902344] "MPa" Vector__XXX
SG_ EngineCyl7SynchronousKnockLevel : 32|8@1+ (1,0) [0|250] "%" Vector__XXX
SG_ EngCyl7PressureSensorPrelimFMI : 40|5@1+ (1,0) [0|31] "" Vector__XXX
SG_ EngineCyl7LowFrequencyKnockLevel : 48|8@1+ (1,0) [0|250] "%" Vector__XXX
SG_ EngCyl7MaxPressureIncreaseRate : 56|8@1+ (16,0) [0|4000] "kPa/deg crank an" Vector__XXX

BO_ 2364555774 ECCI8: 8 Vector__XXX
SG_ EngineCylinder8HeatRelease : 0|16@1+ (0.0001220703125,-1) [-1|6.84362793] "kJ/l" Vector__XXX
SG_ EngineCylinder8PeakPressure : 16|16@1+ (0.0009765625,0) [0|62.74902344] "MPa" Vector__XXX
SG_ EngineCyl8SynchronousKnockLevel : 32|8@1+ (1,0) [0|250] "%" Vector__XXX
SG_ EngCyl8PressureSensorPrelimFMI : 40|5@1+ (1,0) [0|31] "" Vector__XXX
SG_ EngineCyl8LowFrequencyKnockLevel : 48|8@1+ (1,0) [0|250] "%" Vector__XXX
SG_ EngCyl8MaxPressureIncreaseRate : 56|8@1+ (16,0) [0|4000] "kPa/deg crank an" Vector__XXX

BO_ 2364556030 ECCI9: 8 Vector__XXX
SG_ EngineCylinder9HeatRelease : 0|16@1+ (0.0001220703125,-1) [-1|6.84362793] "kJ/l" Vector__XXX
SG_ EngineCylinder9PeakPressure : 16|16@1+ (0.0009765625,0) [0|62.74902344] "MPa" Vector__XXX
SG_ EngineCyl9SynchronousKnockLevel : 32|8@1+ (1,0) [0|250] "%" Vector__XXX
SG_ EngCyl9PressureSensorPrelimFMI : 40|5@1+ (1,0) [0|31] "" Vector__XXX
SG_ EngineCyl9LowFrequencyKnockLevel : 48|8@1+ (1,0) [0|250] "%" Vector__XXX
SG_ EngCyl9MaxPressureIncreaseRate : 56|8@1+ (16,0) [0|4000] "kPa/deg crank an" Vector__XXX

BO_ 2364556286 ECCI10: 8 Vector__XXX
SG_ EngineCylinder10HeatRelease : 0|16@1+ (0.0001220703125,-1) [-1|6.84362793] "kJ/l" Vector__XXX
SG_ EngineCylinder10PeakPressure : 16|16@1+ (0.0009765625,0) [0|62.74902344] "MPa" Vector__XXX
SG_ EngineCyl10SynchronousKnockLevel : 32|8@1+ (1,0) [0|250] "%" Vector__XXX
SG_ EngCyl10PressureSensorPrelimFMI : 40|5@1+ (1,0) [0|31] "" Vector__XXX
SG_ EngCyl10LowFrequencyKnockLevel : 48|8@1+ (1,0) [0|250] "%" Vector__XXX
SG_ EngCyl10MaxPressureIncreaseRate : 56|8@1+ (16,0) [0|4000] "kPa/deg crank an" Vector__XXX

BO_ 2364556542 ECCI11: 8 Vector__XXX
SG_ EngineCylinder11HeatRelease : 0|16@1+ (0.0001220703125,-1) [-1|6.84362793] "kJ/l" Vector__XXX
SG_ EngineCylinder11PeakPressure : 16|16@1+ (0.0009765625,0) [0|62.74902344] "MPa" Vector__XXX
SG_ EngineCyl11SynchronousKnockLevel : 32|8@1+ (1,0) [0|250] "%" Vector__XXX
SG_ EngCyl11PressureSensorPrelimFMI : 40|5@1+ (1,0) [0|31] "" Vector__XXX
SG_ EngCyl11LowFrequencyKnockLevel : 48|8@1+ (1,0) [0|250] "%" Vector__XXX
SG_ EngCyl11MaxPressureIncreaseRate : 56|8@1+ (16,0) [0|4000] "kPa/deg crank an" Vector__XXX

BO_ 2364556798 ECCI12: 8 Vector__XXX
SG_ EngineCylinder12HeatRelease : 0|16@1+ (0.0001220703125,-1) [-1|6.84362793] "kJ/l" Vector__XXX
SG_ EngineCylinder12PeakPressure : 16|16@1+ (0.0009765625,0) [0|62.74902344] "MPa" Vector__XXX
SG_ EngineCyl12SynchronousKnockLevel : 32|8@1+ (1,0) [0|250] "%" Vector__XXX
SG_ EngCyl12PressureSensorPrelimFMI : 40|5@1+ (1,0) [0|31] "" Vector__XXX
SG_ EngCyl12LowFrequencyKnockLevel : 48|8@1+ (1,0) [0|250] "%" Vector__XXX
SG_ EngCyl12MaxPressureIncreaseRate : 56|8@1+ (16,0) [0|4000] "kPa/deg crank an" Vector__XXX

BO_ 2364557054 ECCI13: 8 Vector__XXX
SG_ EngineCylinder13HeatRelease : 0|16@1+ (0.0001220703125,-1) [-1|6.84362793] "kJ/l" Vector__XXX
SG_ EngineCylinder13PeakPressure : 16|16@1+ (0.0009765625,0) [0|62.74902344] "MPa" Vector__XXX
SG_ EngineCyl13SynchronousKnockLevel : 32|8@1+ (1,0) [0|250] "%" Vector__XXX
SG_ EngCyl13PressureSensorPrelimFMI : 40|5@1+ (1,0) [0|31] "" Vector__XXX
SG_ EngCyl13LowFrequencyKnockLevel : 48|8@1+ (1,0) [0|250] "%" Vector__XXX
SG_ EngCyl13MaxPressureIncreaseRate : 56|8@1+ (16,0) [0|4000] "kPa/deg crank an" Vector__XXX

BO_ 2364557310 ECCI14: 8 Vector__XXX
SG_ EngineCylinder14HeatRelease : 0|16@1+ (0.0001220703125,-1) [-1|6.84362793] "kJ/l" Vector__XXX
SG_ EngineCylinder14PeakPressure : 16|16@1+ (0.0009765625,0) [0|62.74902344] "MPa" Vector__XXX
SG_ EngineCyl14SynchronousKnockLevel : 32|8@1+ (1,0) [0|250] "%" Vector__XXX
SG_ EngCyl14PressureSensorPrelimFMI : 40|5@1+ (1,0) [0|31] "" Vector__XXX
SG_ EngCyl14LowFrequencyKnockLevel : 48|8@1+ (1,0) [0|250] "%" Vector__XXX
SG_ EngCyl14MaxPressureIncreaseRate : 56|8@1+ (16,0) [0|4000] "kPa/deg crank an" Vector__XXX

BO_ 2364557566 ECCI15: 8 Vector__XXX
SG_ EngineCylinder15HeatRelease : 0|16@1+ (0.0001220703125,-1) [-1|6.84362793] "kJ/l" Vector__XXX
SG_ EngineCylinder15PeakPressure : 16|16@1+ (0.0009765625,0) [0|62.74902344] "MPa" Vector__XXX
SG_ EngineCyl15SynchronousKnockLevel : 32|8@1+ (1,0) [0|250] "%" Vector__XXX
SG_ EngCyl15PressureSensorPrelimFMI : 40|5@1+ (1,0) [0|31] "" Vector__XXX
SG_ EngCyl15LowFrequencyKnockLevel : 48|8@1+ (1,0) [0|250] "%" Vector__XXX
SG_ EngCyl15MaxPressureIncreaseRate : 56|8@1+ (16,0) [0|4000] "kPa/deg crank an" Vector__XXX

BO_ 2364557822 ECCI16: 8 Vector__XXX
SG_ EngineCylinder16HeatRelease : 0|16@1+ (0.0001220703125,-1) [-1|6.84362793] "kJ/l" Vector__XXX
SG_ EngineCylinder16PeakPressure : 16|16@1+ (0.0009765625,0) [0|62.74902344] "MPa" Vector__XXX
SG_ EngineCyl16SynchronousKnockLevel : 32|8@1+ (1,0) [0|250] "%" Vector__XXX
SG_ EngCyl16PressureSensorPrelimFMI : 40|5@1+ (1,0) [0|31] "" Vector__XXX
SG_ EngCyl16LowFrequencyKnockLevel : 48|8@1+ (1,0) [0|250] "%" Vector__XXX
SG_ EngCyl16MaxPressureIncreaseRate : 56|8@1+ (16,0) [0|4000] "kPa/deg crank an" Vector__XXX

BO_ 2364558078 ECCI17: 8 Vector__XXX
SG_ EngineCylinder17HeatRelease : 0|16@1+ (0.0001220703125,-1) [-1|6.84362793] "kJ/l" Vector__XXX
SG_ EngineCylinder17PeakPressure : 16|16@1+ (0.0009765625,0) [0|62.74902344] "MPa" Vector__XXX
SG_ EngineCyl17SynchronousKnockLevel : 32|8@1+ (1,0) [0|250] "%" Vector__XXX
SG_ EngCyl17PressureSensorPrelimFMI : 40|5@1+ (1,0) [0|31] "" Vector__XXX
SG_ EngCyl17LowFrequencyKnockLevel : 48|8@1+ (1,0) [0|250] "%" Vector__XXX
SG_ EngCyl17MaxPressureIncreaseRate : 56|8@1+ (16,0) [0|4000] "kPa/deg crank an" Vector__XXX

BO_ 2364558334 ECCI18: 8 Vector__XXX
SG_ EngineCylinder18HeatRelease : 0|16@1+ (0.0001220703125,-1) [-1|6.84362793] "kJ/l" Vector__XXX
SG_ EngineCylinder18PeakPressure : 16|16@1+ (0.0009765625,0) [0|62.74902344] "MPa" Vector__XXX
SG_ EngineCyl18SynchronousKnockLevel : 32|8@1+ (1,0) [0|250] "%" Vector__XXX
SG_ EngCyl18PressureSensorPrelimFMI : 40|5@1+ (1,0) [0|31] "" Vector__XXX
SG_ EngCyl18LowFrequencyKnockLevel : 48|8@1+ (1,0) [0|250] "%" Vector__XXX
SG_ EngCyl18MaxPressureIncreaseRate : 56|8@1+ (16,0) [0|4000] "kPa/deg crank an" Vector__XXX

BO_ 2364558590 ECCI19: 8 Vector__XXX
SG_ EngineCylinder19HeatRelease : 0|16@1+ (0.0001220703125,-1) [-1|6.84362793] "kJ/l" Vector__XXX
SG_ EngineCylinder19PeakPressure : 16|16@1+ (0.0009765625,0) [0|62.74902344] "MPa" Vector__XXX
SG_ EngineCyl19SynchronousKnockLevel : 32|8@1+ (1,0) [0|250] "%" Vector__XXX
SG_ EngCyl19PressureSensorPrelimFMI : 40|5@1+ (1,0) [0|31] "" Vector__XXX
SG_ EngCyl19LowFrequencyKnockLevel : 48|8@1+ (1,0) [0|250] "%" Vector__XXX
SG_ EngCyl19MaxPressureIncreaseRate : 56|8@1+ (16,0) [0|4000] "kPa/deg crank an" Vector__XXX

BO_ 2364558846 ECCI20: 8 Vector__XXX
SG_ EngineCylinder20HeatRelease : 0|16@1+ (0.0001220703125,-1) [-1|6.84362793] "kJ/l" Vector__XXX
SG_ EngineCylinder20PeakPressure : 16|16@1+ (0.0009765625,0) [0|62.74902344] "MPa" Vector__XXX
SG_ EngineCyl20SynchronousKnockLevel : 32|8@1+ (1,0) [0|250] "%" Vector__XXX
SG_ EngCyl20PressureSensorPrelimFMI : 40|5@1+ (1,0) [0|31] "" Vector__XXX
SG_ EngCyl20LowFrequencyKnockLevel : 48|8@1+ (1,0) [0|250] "%" Vector__XXX
SG_ EngCyl20MaxPressureIncreaseRate : 56|8@1+ (16,0) [0|4000] "kPa/deg crank an" Vector__XXX

BO_ 2498776830 ECCAI1: 8 Vector__XXX
SG_ EngCyl1IndicatedMeanEffectivePrs : 0|16@1+ (0.0001220703125,-1) [-1|6.84362793] "MPa" Vector__XXX
SG_ EngCyl1AvrgStartCombustionTiming : 16|16@1+ (0.0078125,-250) [-250|250.992] "deg" Vector__XXX
SG_ EngCyl1AvrgCntrCombustionTiming : 32|16@1+ (0.0078125,-250) [-250|250.992] "deg" Vector__XXX
SG_ EngineCyl1AvrgCombustionDuration : 48|16@1+ (0.0078125,0) [0|501.99] "deg" Vector__XXX

BO_ 2498777086 ECCAI2: 8 Vector__XXX
SG_ EngCyl2IndicatedMeanEffectivePrs : 0|16@1+ (0.0001220703125,-1) [-1|6.84362793] "MPa" Vector__XXX
SG_ EngCyl2AvrgStartCombustionTiming : 16|16@1+ (0.0078125,-250) [-250|250.992] "deg" Vector__XXX
SG_ EngCyl2AvrgCntrCombustionTiming : 32|16@1+ (0.0078125,-250) [-250|250.992] "deg" Vector__XXX
SG_ EngineCyl2AvrgCombustionDuration : 48|16@1+ (0.0078125,0) [0|501.99] "deg" Vector__XXX

BO_ 2498777342 ECCAI3: 8 Vector__XXX
SG_ EngCyl3IndicatedMeanEffectivePrs : 0|16@1+ (0.0001220703125,-1) [-1|6.84362793] "MPa" Vector__XXX
SG_ EngCyl3AvrgStartCombustionTiming : 16|16@1+ (0.0078125,-250) [-250|250.992] "deg" Vector__XXX
SG_ EngCyl3AvrgCntrCombustionTiming : 32|16@1+ (0.0078125,-250) [-250|250.992] "deg" Vector__XXX
SG_ EngineCyl3AvrgCombustionDuration : 48|16@1+ (0.0078125,0) [0|501.99] "deg" Vector__XXX

BO_ 2498777598 ECCAI4: 8 Vector__XXX
SG_ EngCyl4IndicatedMeanEffectivePrs : 0|16@1+ (0.0001220703125,-1) [-1|6.84362793] "MPa" Vector__XXX
SG_ EngCyl4AvrgStartCombustionTiming : 16|16@1+ (0.0078125,-250) [-250|250.992] "deg" Vector__XXX
SG_ EngCyl4AvrgCntrCombustionTiming : 32|16@1+ (0.0078125,-250) [-250|250.992] "deg" Vector__XXX
SG_ EngineCyl4AvrgCombustionDuration : 48|16@1+ (0.0078125,0) [0|501.99] "deg" Vector__XXX

BO_ 2498777854 ECCAI5: 8 Vector__XXX
SG_ EngCyl5IndicatedMeanEffectivePrs : 0|16@1+ (0.0001220703125,-1) [-1|6.84362793] "MPa" Vector__XXX
SG_ EngCyl5AvrgStartCombustionTiming : 16|16@1+ (0.0078125,-250) [-250|250.992] "deg" Vector__XXX
SG_ EngCyl5AvrgCntrCombustionTiming : 32|16@1+ (0.0078125,-250) [-250|250.992] "deg" Vector__XXX
SG_ EngineCyl5AvrgCombustionDuration : 48|16@1+ (0.0078125,0) [0|501.99] "deg" Vector__XXX

BO_ 2498778110 ECCAI6: 8 Vector__XXX
SG_ EngCyl6IndicatedMeanEffectivePrs : 0|16@1+ (0.0001220703125,-1) [-1|6.84362793] "MPa" Vector__XXX
SG_ EngCyl6AvrgStartCombustionTiming : 16|16@1+ (0.0078125,-250) [-250|250.992] "deg" Vector__XXX
SG_ EngCyl6AvrgCntrCombustionTiming : 32|16@1+ (0.0078125,-250) [-250|250.992] "deg" Vector__XXX
SG_ EngineCyl6AvrgCombustionDuration : 48|16@1+ (0.0078125,0) [0|501.99] "deg" Vector__XXX

BO_ 2498778366 ECCAI7: 8 Vector__XXX
SG_ EngCyl7IndicatedMeanEffectivePrs : 0|16@1+ (0.0001220703125,-1) [-1|6.84362793] "MPa" Vector__XXX
SG_ EngCyl7AvrgStartCombustionTiming : 16|16@1+ (0.0078125,-250) [-250|250.992] "deg" Vector__XXX
SG_ EngCyl7AvrgCntrCombustionTiming : 32|16@1+ (0.0078125,-250) [-250|250.992] "deg" Vector__XXX
SG_ EngineCyl7AvrgCombustionDuration : 48|16@1+ (0.0078125,0) [0|501.99] "deg" Vector__XXX

BO_ 2498778622 ECCAI8: 8 Vector__XXX
SG_ EngCyl8IndicatedMeanEffectivePrs : 0|16@1+ (0.0001220703125,-1) [-1|6.84362793] "MPa" Vector__XXX
SG_ EngCyl8AvrgStartCombustionTiming : 16|16@1+ (0.0078125,-250) [-250|250.992] "deg" Vector__XXX
SG_ EngCyl8AvrgCntrCombustionTiming : 32|16@1+ (0.0078125,-250) [-250|250.992] "deg" Vector__XXX
SG_ EngineCyl8AvrgCombustionDuration : 48|16@1+ (0.0078125,0) [0|501.99] "deg" Vector__XXX

BO_ 2498778878 ECCAI9: 8 Vector__XXX
SG_ EngCyl9IndicatedMeanEffectivePrs : 0|16@1+ (0.0001220703125,-1) [-1|6.84362793] "MPa" Vector__XXX
SG_ EngCyl9AvrgStartCombustionTiming : 16|16@1+ (0.0078125,-250) [-250|250.992] "deg" Vector__XXX
SG_ EngCyl9AvrgCntrCombustionTiming : 32|16@1+ (0.0078125,-250) [-250|250.992] "deg" Vector__XXX
SG_ EngineCyl9AvrgCombustionDuration : 48|16@1+ (0.0078125,0) [0|501.99] "deg" Vector__XXX

BO_ 2498779134 ECCAI10: 8 Vector__XXX
SG_ EngCyl10IndicatedMeanEffectPrs : 0|16@1+ (0.0001220703125,-1) [-1|6.84362793] "MPa" Vector__XXX
SG_ EngCyl10AvrgStrtOfCombustionTmng : 16|16@1+ (0.0078125,-250) [-250|250.992] "deg" Vector__XXX
SG_ EngCyl10AvrgCntrOfCombustionTmng : 32|16@1+ (0.0078125,-250) [-250|250.992] "deg" Vector__XXX
SG_ EngCyl10AvrgCombustionDuration : 48|16@1+ (0.0078125,0) [0|501.99] "deg" Vector__XXX

BO_ 2498779390 ECCAI11: 8 Vector__XXX
SG_ EngCyl11IndicatedMeanEffectPrs : 0|16@1+ (0.0001220703125,-1) [-1|6.84362793] "MPa" Vector__XXX
SG_ EngCyl11AvrgStrtOfCombustionTmng : 16|16@1+ (0.0078125,-250) [-250|250.992] "deg" Vector__XXX
SG_ EngCyl11AvrgCntrOfCombustionTmng : 32|16@1+ (0.0078125,-250) [-250|250.992] "deg" Vector__XXX
SG_ EngCyl11AvrgCombustionDuration : 48|16@1+ (0.0078125,0) [0|501.99] "deg" Vector__XXX

BO_ 2498779646 ECCAI12: 8 Vector__XXX
SG_ EngCyl12IndicatedMeanEffectPrs : 0|16@1+ (0.0001220703125,-1) [-1|6.84362793] "MPa" Vector__XXX
SG_ EngCyl12AvrgStrtOfCombustionTmng : 16|16@1+ (0.0078125,-250) [-250|250.992] "deg" Vector__XXX
SG_ EngCyl12AvrgCntrOfCombustionTmng : 32|16@1+ (0.0078125,-250) [-250|250.992] "deg" Vector__XXX
SG_ EngCyl12AvrgCombustionDuration : 48|16@1+ (0.0078125,0) [0|501.99] "deg" Vector__XXX

BO_ 2498779902 ECCAI13: 8 Vector__XXX
SG_ EngCyl13IndicatedMeanEffectPrs : 0|16@1+ (0.0001220703125,-1) [-1|6.84362793] "MPa" Vector__XXX
SG_ EngCyl13AvrgStrtOfCombustionTmng : 16|16@1+ (0.0078125,-250) [-250|250.992] "deg" Vector__XXX
SG_ EngCyl13AvrgCntrOfCombustionTmng : 32|16@1+ (0.0078125,-250) [-250|250.992] "deg" Vector__XXX
SG_ EngCyl13AvrgCombustionDuration : 48|16@1+ (0.0078125,0) [0|501.99] "deg" Vector__XXX

BO_ 2498780158 ECCAI14: 8 Vector__XXX
SG_ EngCyl14IndicatedMeanEffectPrs : 0|16@1+ (0.0001220703125,-1) [-1|6.84362793] "MPa" Vector__XXX
SG_ EngCyl14AvrgStrtOfCombustionTmng : 16|16@1+ (0.0078125,-250) [-250|250.992] "deg" Vector__XXX
SG_ EngCyl14AvrgCntrOfCombustionTmng : 32|16@1+ (0.0078125,-250) [-250|250.992] "deg" Vector__XXX
SG_ EngCyl14AvrgCombustionDuration : 48|16@1+ (0.0078125,0) [0|501.99] "deg" Vector__XXX

BO_ 2498780414 ECCAI15: 8 Vector__XXX
SG_ EngCyl15IndicatedMeanEffectPrs : 0|16@1+ (0.0001220703125,-1) [-1|6.84362793] "MPa" Vector__XXX
SG_ EngCyl15AvrgStrtOfCombustionTmng : 16|16@1+ (0.0078125,-250) [-250|250.992] "deg" Vector__XXX
SG_ EngCyl15AvrgCntrOfCombustionTmng : 32|16@1+ (0.0078125,-250) [-250|250.992] "deg" Vector__XXX
SG_ EngCyl15AvrgCombustionDuration : 48|16@1+ (0.0078125,0) [0|501.99] "deg" Vector__XXX

BO_ 2498780670 ECCAI16: 8 Vector__XXX
SG_ EngCyl16IndicatedMeanEffectPrs : 0|16@1+ (0.0001220703125,-1) [-1|6.84362793] "MPa" Vector__XXX
SG_ EngCyl16AvrgStrtOfCombustionTmng : 16|16@1+ (0.0078125,-250) [-250|250.992] "deg" Vector__XXX
SG_ EngCyl16AvrgCntrOfCombustionTmng : 32|16@1+ (0.0078125,-250) [-250|250.992] "deg" Vector__XXX
SG_ EngCyl16AvrgCombustionDuration : 48|16@1+ (0.0078125,0) [0|501.99] "deg" Vector__XXX

BO_ 2498780926 ECCAI17: 8 Vector__XXX
SG_ EngCyl17IndicatedMeanEffectPrs : 0|16@1+ (0.0001220703125,-1) [-1|6.84362793] "MPa" Vector__XXX
SG_ EngCyl17AvrgStrtOfCombustionTmng : 16|16@1+ (0.0078125,-250) [-250|250.992] "deg" Vector__XXX
SG_ EngCyl17AvrgCntrOfCombustionTmng : 32|16@1+ (0.0078125,-250) [-250|250.992] "deg" Vector__XXX
SG_ EngCyl17AvrgCombustionDuration : 48|16@1+ (0.0078125,0) [0|501.99] "deg" Vector__XXX

BO_ 2498781182 ECCAI18: 8 Vector__XXX
SG_ EngCyl18IndicatedMeanEffectPrs : 0|16@1+ (0.0001220703125,-1) [-1|6.84362793] "MPa" Vector__XXX
SG_ EngCyl18AvrgStrtOfCombustionTmng : 16|16@1+ (0.0078125,-250) [-250|250.992] "deg" Vector__XXX
SG_ EngCyl18AvrgCntrOfCombustionTmng : 32|16@1+ (0.0078125,-250) [-250|250.992] "deg" Vector__XXX
SG_ EngCyl18AvrgCombustionDuration : 48|16@1+ (0.0078125,0) [0|501.99] "deg" Vector__XXX

BO_ 2498781438 ECCAI19: 8 Vector__XXX
SG_ EngCyl19IndicatedMeanEffectPrs : 0|16@1+ (0.0001220703125,-1) [-1|6.84362793] "MPa" Vector__XXX
SG_ EngCyl19AvrgStrtOfCombustionTmng : 16|16@1+ (0.0078125,-250) [-250|250.992] "deg" Vector__XXX
SG_ EngCyl19AvrgCntrOfCombustionTmng : 32|16@1+ (0.0078125,-250) [-250|250.992] "deg" Vector__XXX
SG_ EngCyl19AvrgCombustionDuration : 48|16@1+ (0.0078125,0) [0|501.99] "deg" Vector__XXX

BO_ 2498781694 ECCAI20: 8 Vector__XXX
SG_ EngCyl20IndicatedMeanEffectPrs : 0|16@1+ (0.0001220703125,-1) [-1|6.84362793] "MPa" Vector__XXX
SG_ EngCyl20AvrgStrtOfCombustionTmng : 16|16@1+ (0.0078125,-250) [-250|250.992] "deg" Vector__XXX
SG_ EngCyl20AvrgCntrOfCombustionTmng : 32|16@1+ (0.0078125,-250) [-250|250.992] "deg" Vector__XXX
SG_ EngCyl20AvrgCombustionDuration : 48|16@1+ (0.0078125,0) [0|501.99] "deg" Vector__XXX

BO_ 2297455358 ETC12: 8 Vector__XXX
SG_ TransmissionHydrostaticLp1Press : 0|16@1+ (1,0) [0|64255] "kPa" Vector__XXX
SG_ TransmissionHydrostaticLp2Press : 16|16@1+ (1,0) [0|64255] "kPa" Vector__XXX
SG_ TrnsmDirectionalOutptShftSpd : 32|16@1+ (1,-32127) [-32127|32128] "rpm" Vector__XXX
SG_ TransmissionIntrmedShaftSpeed : 48|16@1+ (0.125,0) [0|8031.875] "rpm" Vector__XXX

BO_ 2364564478 GFI5: 8 Vector__XXX
SG_ EngGseousFuelVlvNomDurationCmd : 0|16@1+ (2,0) [0|128510] "us" Vector__XXX
SG_ EngGseousFuelVlvNomStrtOfActCmd : 16|16@1+ (0.0078125,-400) [-400|101.99] "deg" Vector__XXX
SG_ EngPreChamberFuelVlvNomDuratnCmd : 32|16@1+ (2,0) [0|128510] "us" Vector__XXX
SG_ EngPreChmbrFuelVlvNomStrtActCmd : 48|16@1+ (0.0078125,-400) [-400|101.99] "deg" Vector__XXX

BO_ 2364564734 EGFVDC1: 8 Vector__XXX
SG_ EngGaseousFuelValve1DurationCmd : 0|16@1+ (2,0) [0|128510] "us" Vector__XXX
SG_ EngGaseousFuelValve2DurationCmd : 16|16@1+ (2,0) [0|128510] "us" Vector__XXX
SG_ EngGaseousFuelValve3DurationCmd : 32|16@1+ (2,0) [0|128510] "us" Vector__XXX
SG_ EngGaseousFuelValve4DurationCmd : 48|16@1+ (2,0) [0|128510] "us" Vector__XXX

BO_ 2364564990 EGFVDC2: 8 Vector__XXX
SG_ EngGaseousFuelValve5DurationCmd : 0|16@1+ (2,0) [0|128510] "us" Vector__XXX
SG_ EngGaseousFuelValve6DurationCmd : 16|16@1+ (2,0) [0|128510] "us" Vector__XXX
SG_ EngGaseousFuelValve7DurationCmd : 32|16@1+ (2,0) [0|128510] "us" Vector__XXX
SG_ EngGaseousFuelValve8DurationCmd : 48|16@1+ (2,0) [0|128510] "us" Vector__XXX

BO_ 2364565246 EGFVDC3: 8 Vector__XXX
SG_ EngGaseousFuelValve9DurationCmd : 0|16@1+ (2,0) [0|128510] "us" Vector__XXX
SG_ EngGaseousFuelValve10DurationCmd : 16|16@1+ (2,0) [0|128510] "us" Vector__XXX
SG_ EngGaseousFuelValve11DurationCmd : 32|16@1+ (2,0) [0|128510] "us" Vector__XXX
SG_ EngGaseousFuelValve12DurationCmd : 48|16@1+ (2,0) [0|128510] "us" Vector__XXX

BO_ 2364565502 EGFVDC4: 8 Vector__XXX
SG_ EngGaseousFuelValve13DurationCmd : 0|16@1+ (2,0) [0|128510] "us" Vector__XXX
SG_ EngGaseousFuelValve14DurationCmd : 16|16@1+ (2,0) [0|128510] "us" Vector__XXX
SG_ EngGaseousFuelValve15DurationCmd : 32|16@1+ (2,0) [0|128510] "us" Vector__XXX
SG_ EngGaseousFuelValve16DurationCmd : 48|16@1+ (2,0) [0|128510] "us" Vector__XXX

BO_ 2364565758 EGFVDC5: 8 Vector__XXX
SG_ EngGaseousFuelValve17DurationCmd : 0|16@1+ (2,0) [0|128510] "us" Vector__XXX
SG_ EngGaseousFuelValve18DurationCmd : 16|16@1+ (2,0) [0|128510] "us" Vector__XXX
SG_ EngGaseousFuelValve19DurationCmd : 32|16@1+ (2,0) [0|128510] "us" Vector__XXX
SG_ EngGaseousFuelValve20DurationCmd : 48|16@1+ (2,0) [0|128510] "us" Vector__XXX

BO_ 2364566014 EGFVSOAC1: 8 Vector__XXX
SG_ EngGaseousFuelVlv1StartOfActCmd : 0|16@1+ (0.0078125,-400) [-400|101.99] "deg" Vector__XXX
SG_ EngGaseousFuelVlv2StartOfActCmd : 16|16@1+ (0.0078125,-400) [-400|101.99] "deg" Vector__XXX
SG_ EngGaseousFuelVlv3StartOfActCmd : 32|16@1+ (0.0078125,-400) [-400|101.99] "deg" Vector__XXX
SG_ EngGaseousFuelVlv4StartOfActCmd : 48|16@1+ (0.0078125,-400) [-400|101.99] "deg" Vector__XXX

BO_ 2364566270 EGFVSOAC2: 8 Vector__XXX
SG_ EngGaseousFuelVlv5StartOfActCmd : 0|16@1+ (0.0078125,-400) [-400|101.99] "deg" Vector__XXX
SG_ EngGaseousFuelVlv6StartOfActCmd : 16|16@1+ (0.0078125,-400) [-400|101.99] "deg" Vector__XXX
SG_ EngGaseousFuelVlv7StartOfActCmd : 32|16@1+ (0.0078125,-400) [-400|101.99] "deg" Vector__XXX
SG_ EngGaseousFuelVlv8StartOfActCmd : 48|16@1+ (0.0078125,-400) [-400|101.99] "deg" Vector__XXX

BO_ 2364566526 EGFVSOAC3: 8 Vector__XXX
SG_ EngGaseousFuelVlv9StartOfActCmd : 0|16@1+ (0.0078125,-400) [-400|101.99] "deg" Vector__XXX
SG_ EngGaseousFuelVlv10StartOfActCmd : 16|16@1+ (0.0078125,-400) [-400|101.99] "deg" Vector__XXX
SG_ EngGaseousFuelVlv11StartOfActCmd : 32|16@1+ (0.0078125,-400) [-400|101.99] "deg" Vector__XXX
SG_ EngGaseousFuelVlv12StartOfActCmd : 48|16@1+ (0.0078125,-400) [-400|101.99] "deg" Vector__XXX

BO_ 2364566782 EGFVSOAC4: 8 Vector__XXX
SG_ EngGaseousFuelVlv13StartOfActCmd : 0|16@1+ (0.0078125,-400) [-400|101.99] "deg" Vector__XXX
SG_ EngGaseousFuelVlv14StartOfActCmd : 16|16@1+ (0.0078125,-400) [-400|101.99] "deg" Vector__XXX
SG_ EngGaseousFuelVlv15StartOfActCmd : 32|16@1+ (0.0078125,-400) [-400|101.99] "deg" Vector__XXX
SG_ EngGaseousFuelVlv16StartOfActCmd : 48|16@1+ (0.0078125,-400) [-400|101.99] "deg" Vector__XXX

BO_ 2364567038 EGFVSOAC5: 8 Vector__XXX
SG_ EngGaseousFuelVlv17StartOfActCmd : 0|16@1+ (0.0078125,-400) [-400|101.99] "deg" Vector__XXX
SG_ EngGaseousFuelVlv18StartOfActCmd : 16|16@1+ (0.0078125,-400) [-400|101.99] "deg" Vector__XXX
SG_ EngGaseousFuelVlv19StartOfActCmd : 32|16@1+ (0.0078125,-400) [-400|101.99] "deg" Vector__XXX
SG_ EngGaseousFuelVlv20StartOfActCmd : 48|16@1+ (0.0078125,-400) [-400|101.99] "deg" Vector__XXX

BO_ 2364567294 FPAC: 8 Vector__XXX
SG_ EngFuelInjectPmp1FuelCtrlVlvCmd : 0|16@1+ (0.0025,0) [0|160.6375] "%" Vector__XXX
SG_ EngFuelInjectPmp2FuelCtrlVlvCmd : 16|16@1+ (0.0025,0) [0|160.6375] "%" Vector__XXX

BO_ 2364575998 HVESSD1: 8 Vector__XXX
SG_ HVES1AvailableDischargePower : 0|16@1+ (0.05,0) [0|3212.75] "kW" Vector__XXX
SG_ HVES1AvailableChargePower : 16|16@1+ (0.05,0) [0|3212.75] "kW" Vector__XXX
SG_ HVES1VoltageLevel : 32|16@1+ (0.05,0) [0|3212.75] "V" Vector__XXX
SG_ HVES1Current : 48|16@1+ (0.05,-1600) [-1600|1612.75] "A" Vector__XXX

BO_ 2364576254 HVESSD2: 8 Vector__XXX
SG_ HVES1FastUpdateStateOfCharge : 0|16@1+ (0.0015625,0) [0|100.3984375] "%" Vector__XXX
SG_ HVES1HighestCellVoltage : 16|16@1+ (0.001,0) [0|64.255] "V" Vector__XXX
SG_ HVES1LowestCellVoltage : 32|16@1+ (0.001,0) [0|64.255] "V" Vector__XXX
SG_ HVES1CellVoltageDiffStatus : 48|4@1+ (1,0) [0|15] "" Vector__XXX

BO_ 2364576510 HVESSD3: 8 Vector__XXX
SG_ HVES1HighestCellTemperature : 0|16@1+ (0.03125,-273) [-273|1734.96875] "deg C" Vector__XXX
SG_ HVES1LowestCellTemperature : 16|16@1+ (0.03125,-273) [-273|1734.96875] "deg C" Vector__XXX
SG_ HVES1AverageCellTemperature : 32|16@1+ (0.03125,-273) [-273|1734.96875] "deg C" Vector__XXX
SG_ HVES1CellTemperatureDiffStatus : 48|2@1+ (1,0) [0|3] "" Vector__XXX

BO_ 2364576766 HVESSD4: 8 Vector__XXX
SG_ HVES1DischargeCapacity : 0|16@1+ (0.01,0) [0|642.55] "Ah" Vector__XXX
SG_ HVES1ChargeCapacity : 16|16@1+ (0.01,0) [0|642.55] "Ah" Vector__XXX
SG_ HVES1CellBalancingCount : 32|16@1+ (1,0) [0|64255] "" Vector__XXX

BO_ 2364577022 HVESSD5: 8 Vector__XXX
SG_ HVES1DischargeCurrentLimit : 0|16@1+ (0.05,-1600) [-1600|1612.75] "A" Vector__XXX
SG_ HVES1ChargeCurrentLimit : 16|16@1+ (0.05,-1600) [-1600|1612.75] "A" Vector__XXX
SG_ HVES1MinimumCellStateOfCharge : 32|16@1+ (0.0015625,0) [0|100.3984375] "%" Vector__XXX
SG_ HVES1MaximumCellStateOfCharge : 48|16@1+ (0.0015625,0) [0|100.3984375] "%" Vector__XXX

BO_ 2364577278 HVESSD6: 8 Vector__XXX
SG_ HVES1BusVoltage : 0|16@1+ (0.05,0) [0|3212.75] "V" Vector__XXX
SG_ HVES1IgnitionVoltage : 16|16@1+ (0.01,0) [0|642.55] "V" Vector__XXX
SG_ HVES1InletCoolantTemperature : 32|8@1+ (1,-40) [-40|210] "deg C" Vector__XXX
SG_ HVES1OutletCoolantTemperature : 40|8@1+ (1,-40) [-40|210] "deg C" Vector__XXX
SG_ HVES1ElectronicsTemperature : 48|8@1+ (1,-40) [-40|210] "deg C" Vector__XXX
SG_ HVES1Temperature : 56|8@1+ (1,-40) [-40|210] "deg C" Vector__XXX

BO_ 2364577534 HVESSS1: 8 Vector__XXX
SG_ HVES1HghVoltageBusPosContactStat : 0|2@1+ (1,0) [0|3] "" Vector__XXX
SG_ HVES1HghVoltageBusNegContactStat : 2|2@1+ (1,0) [0|3] "" Vector__XXX
SG_ HVES1HghVoltageBusDiscnnctFrwrng : 4|4@1+ (1,0) [0|15] "" Vector__XXX
SG_ HVES1HghVltgBusPreChrgRelyStat : 8|2@1+ (1,0) [0|3] "" Vector__XXX
SG_ HVES1CenterOfPackContactorState : 10|2@1+ (1,0) [0|3] "" Vector__XXX
SG_ HVES1HiVltgBusActIsolatnTestStat : 12|4@1+ (1,0) [0|15] "" Vector__XXX
SG_ HVES1HiVltgBusPassIsolatnTestSt : 16|4@1+ (1,0) [0|15] "" Vector__XXX
SG_ HVES1HVILStatus : 20|2@1+ (1,0) [0|3] "" Vector__XXX
SG_ HVES1InertiaSwitchStatus : 22|2@1+ (1,0) [0|3] "" Vector__XXX
SG_ HVES1StateOfChargeStatus : 24|4@1+ (1,0) [0|15] "" Vector__XXX
SG_ HVES1CellBalanceStatus : 28|2@1+ (1,0) [0|3] "" Vector__XXX
SG_ HVES1CellBalancingActive : 30|2@1+ (1,0) [0|3] "" Vector__XXX
SG_ HVES1InternalChargerStatus : 32|2@1+ (1,0) [0|3] "" Vector__XXX
SG_ HVES1HghVoltageBusConnectnStatus : 40|4@1+ (1,0) [0|15] "" Vector__XXX
SG_ HVES1OperationalStatus : 44|4@1+ (1,0) [0|15] "" Vector__XXX

BO_ 2364580094 HVESSD7: 8 Vector__XXX
SG_ HVES1DischargeEnergyCapacity : 0|24@1+ (0.001,0) [0|16449.535] "kWh" Vector__XXX
SG_ HVES1ChargeEnergyCapacity : 24|24@1+ (0.001,0) [0|16449.535] "kWh" Vector__XXX
SG_ HVES1MaximumChargeVoltageLimit : 48|16@1+ (0.05,0) [0|3212.75] "V" Vector__XXX

BO_ 2364590334 DCAC_AI1_S2: 8 Vector__XXX
SG_ DCACAccssryInverter1DCSidePower : 0|16@1+ (0.0625,0) [0|4015.9375] "kW" Vector__XXX
SG_ DCACAccssryInvert1DCSideVoltage : 16|16@1+ (0.05,0) [0|3212.75] "V" Vector__XXX
SG_ DCACAccssryInverter1DCSideCurr : 32|16@1+ (0.0625,0) [0|4015.9375] "A" Vector__XXX
SG_ DCACAccssryInv1DCSdeNgToChGrVltg : 48|16@1+ (0.05,0) [0|3212.75] "V" Vector__XXX

BO_ 2364590590 DCAC_AI1_V: 8 Vector__XXX
SG_ DCACAccssryInvert1IgnitionVltg : 0|16@1+ (0.05,0) [0|3212.75] "V" Vector__XXX
SG_ DCACAccessoryInverter1SLIVoltage : 16|16@1+ (0.05,0) [0|3212.75] "V" Vector__XXX

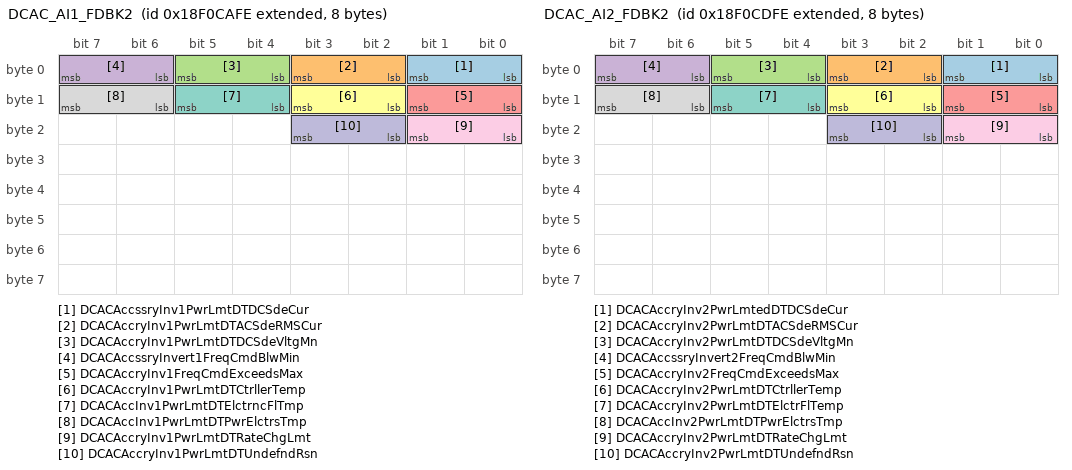
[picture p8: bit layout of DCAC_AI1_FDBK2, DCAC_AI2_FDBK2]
BO_ 2565917438 DCAC_AI1_FDBK2: 8 Vector__XXX
SG_ DCACAccssryInv1PwrLmtDTDCSdeCur : 0|2@1+ (1,0) [0|3] "" Vector__XXX
SG_ DCACAccryInv1PwrLmtDTACSdeRMSCur : 2|2@1+ (1,0) [0|3] "" Vector__XXX
SG_ DCACAccryInv1PwrLmtDTDCSdeVltgMn : 4|2@1+ (1,0) [0|3] "" Vector__XXX
SG_ DCACAccssryInvert1FreqCmdBlwMin : 6|2@1+ (1,0) [0|3] "" Vector__XXX
SG_ DCACAccryInv1FreqCmdExceedsMax : 8|2@1+ (1,0) [0|3] "" Vector__XXX
SG_ DCACAccryInv1PwrLmtDTCtrllerTemp : 10|2@1+ (1,0) [0|3] "" Vector__XXX
SG_ DCACAccInv1PwrLmtDTElctrncFlTmp : 12|2@1+ (1,0) [0|3] "" Vector__XXX
SG_ DCACAccInv1PwrLmtDTPwrElctrsTmp : 14|2@1+ (1,0) [0|3] "" Vector__XXX
SG_ DCACAccryInv1PwrLmtDTRateChgLmt : 16|2@1+ (1,0) [0|3] "" Vector__XXX
SG_ DCACAccryInv1PwrLmtDTUndefndRsn : 18|2@1+ (1,0) [0|3] "" Vector__XXX

BO_ 2364591102 DCAC_AI2_S2: 8 Vector__XXX
SG_ DCACAccssryInverter2DCSidePower : 0|16@1+ (0.0625,0) [0|4015.9375] "kW" Vector__XXX
SG_ DCACAccssryInvert2DCSideVoltage : 16|16@1+ (0.05,0) [0|3212.75] "V" Vector__XXX
SG_ DCACAccssryInverter2DCSideCurr : 32|16@1+ (0.0625,0) [0|4015.9375] "A" Vector__XXX
SG_ DCACAccryInv2DCSdeNegToChGrdVltg : 48|16@1+ (0.05,0) [0|3212.75] "V" Vector__XXX

BO_ 2364591358 DCAC_AI2_V: 8 Vector__XXX
SG_ DCACAccssryInvert2IgnitionVltg : 0|16@1+ (0.05,0) [0|3212.75] "V" Vector__XXX
SG_ DCACAccessoryInverter2SLIVoltage : 16|16@1+ (0.05,0) [0|3212.75] "V" Vector__XXX

BO_ 2565918206 DCAC_AI2_FDBK2: 8 Vector__XXX
SG_ DCACAccryInv2PwrLmtedDTDCSdeCur : 0|2@1+ (1,0) [0|3] "" Vector__XXX
SG_ DCACAccryInv2PwrLmtDTACSdeRMSCur : 2|2@1+ (1,0) [0|3] "" Vector__XXX
SG_ DCACAccryInv2PwrLmtDTDCSdeVltgMn : 4|2@1+ (1,0) [0|3] "" Vector__XXX
SG_ DCACAccssryInvert2FreqCmdBlwMin : 6|2@1+ (1,0) [0|3] "" Vector__XXX
SG_ DCACAccryInv2FreqCmdExceedsMax : 8|2@1+ (1,0) [0|3] "" Vector__XXX
SG_ DCACAccryInv2PwrLmtDTCtrllerTemp : 10|2@1+ (1,0) [0|3] "" Vector__XXX
SG_ DCACAccryInv2PwrLmtDTElctrFlTemp : 12|2@1+ (1,0) [0|3] "" Vector__XXX
SG_ DCACAccInv2PwrLmtDTPwrElctrsTmp : 14|2@1+ (1,0) [0|3] "" Vector__XXX
SG_ DCACAccryInv2PwrLmtDTRateChgLmt : 16|2@1+ (1,0) [0|3] "" Vector__XXX
SG_ DCACAccryInv2PwrLmtDTUndefndRsn : 18|2@1+ (1,0) [0|3] "" Vector__XXX

BO_ 2364592382 ECCR: 8 Vector__XXX
SG_ NoEngCylsToExcludeFrmCombustion : 0|8@1+ (1,0) [0|250] "" Vector__XXX
SG_ EngCyl1ExcludeFrmCombustionRq : 8|2@1+ (1,0) [0|3] "" Vector__XXX
SG_ EngCyl2ExcludeFrmCombustionRq : 10|2@1+ (1,0) [0|3] "" Vector__XXX
SG_ EngCyl3ExcludeFrmCombustionRq : 12|2@1+ (1,0) [0|3] "" Vector__XXX
SG_ EngCyl4ExcludeFrmCombustionRq : 14|2@1+ (1,0) [0|3] "" Vector__XXX
SG_ EngCyl5ExcludeFrmCombustionRq : 16|2@1+ (1,0) [0|3] "" Vector__XXX
SG_ EngCyl6ExcludeFrmCombustionRq : 18|2@1+ (1,0) [0|3] "" Vector__XXX
SG_ EngCyl7ExcludeFrmCombustionRq : 20|2@1+ (1,0) [0|3] "" Vector__XXX
SG_ EngCyl8ExcludeFrmCombustionRq : 22|2@1+ (1,0) [0|3] "" Vector__XXX
SG_ EngCyl9ExcludeFrmCombustionRq : 24|2@1+ (1,0) [0|3] "" Vector__XXX
SG_ EngCyl10ExcludeFrmCombustionRq : 26|2@1+ (1,0) [0|3] "" Vector__XXX
SG_ EngCyl11ExcludeFrmCombustionRq : 28|2@1+ (1,0) [0|3] "" Vector__XXX
SG_ EngCyl12ExcludeFrmCombustionRq : 30|2@1+ (1,0) [0|3] "" Vector__XXX
SG_ EngCyl13ExcludeFrmCombustionRq : 32|2@1+ (1,0) [0|3] "" Vector__XXX
SG_ EngCyl14ExcludeFrmCombustionRq : 34|2@1+ (1,0) [0|3] "" Vector__XXX
SG_ EngCyl15ExcludeFrmCombustionRq : 36|2@1+ (1,0) [0|3] "" Vector__XXX
SG_ EngCyl16ExcludeFrmCombustionRq : 38|2@1+ (1,0) [0|3] "" Vector__XXX
SG_ EngCyl17ExcludeFrmCombustionRq : 40|2@1+ (1,0) [0|3] "" Vector__XXX
SG_ EngCyl18ExcludeFrmCombustionRq : 42|2@1+ (1,0) [0|3] "" Vector__XXX
SG_ EngCyl19ExcludeFrmCombustionRq : 44|2@1+ (1,0) [0|3] "" Vector__XXX
SG_ EngCyl20ExcludeFrmCombustionRq : 46|2@1+ (1,0) [0|3] "" Vector__XXX
SG_ EngCyl21ExcludeFrmCombustionRq : 48|2@1+ (1,0) [0|3] "" Vector__XXX
SG_ EngCyl22ExcludeFrmCombustionRq : 50|2@1+ (1,0) [0|3] "" Vector__XXX
SG_ EngCyl23ExcludeFrmCombustionRq : 52|2@1+ (1,0) [0|3] "" Vector__XXX
SG_ EngCyl24ExcludeFrmCombustionRq : 54|2@1+ (1,0) [0|3] "" Vector__XXX

BO_ 2364592638 ECBA1: 8 Vector__XXX
SG_ EngCylHeadBypssActr1PrelimFMI : 0|5@1+ (1,0) [0|31] "" Vector__XXX
SG_ EngCylHeadBypssActr1TempStat : 5|3@1+ (1,0) [0|7] "" Vector__XXX
SG_ EngCylHeadBypssActr1Temperature : 8|8@1+ (1,-40) [-40|210] "deg C" Vector__XXX
SG_ EngCylHeadBypssActr1DsrdPosition : 16|8@1+ (0.4,0) [0|100] "%" Vector__XXX
SG_ EngineCylHeadBypssActr1Position : 24|8@1+ (0.4,0) [0|100] "%" Vector__XXX
SG_ EngCylHeadBypssActr1OpStatus : 32|4@1+ (1,0) [0|15] "" Vector__XXX

BO_ 2364592894 EEC18: 8 Vector__XXX
SG_ EngineCylinderHeadBypssActr1Cmd : 0|16@1+ (0.0025,0) [0|160.6375] "%" Vector__XXX
SG_ EngineIntakeAirSourceValve : 16|2@1+ (1,0) [0|3] "" Vector__XXX
SG_ EngExhstGsRestrictionValvePos : 32|16@1+ (0.0025,0) [0|160.6375] "%" Vector__XXX

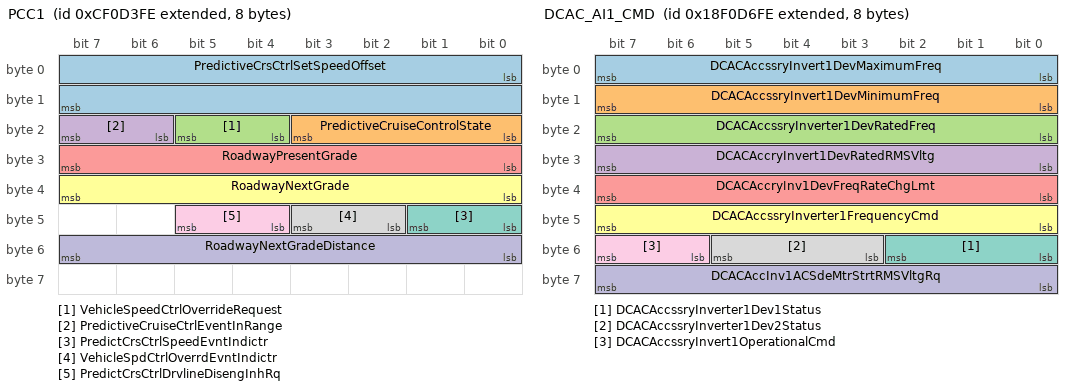
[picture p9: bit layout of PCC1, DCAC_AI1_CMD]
BO_ 2364593150 PCC1: 8 Vector__XXX
SG_ PredictiveCrsCtrlSetSpeedOffset : 0|16@1+ (0.00390625,-125) [-125|125.996] "km/h" Vector__XXX
SG_ PredictiveCruiseControlState : 16|4@1+ (1,0) [0|15] "" Vector__XXX
SG_ VehicleSpeedCtrlOverrideRequest : 20|2@1+ (1,0) [0|3] "" Vector__XXX
SG_ PredictiveCruiseCtrlEventInRange : 22|2@1+ (1,0) [0|3] "" Vector__XXX
SG_ RoadwayPresentGrade : 24|8@1+ (0.125,-16) [-16|15.25] "%" Vector__XXX
SG_ RoadwayNextGrade : 32|8@1+ (0.125,-16) [-16|15.25] "%" Vector__XXX
SG_ PredictCrsCtrlSpeedEvntIndictr : 40|2@1+ (1,0) [0|3] "" Vector__XXX
SG_ VehicleSpdCtrlOverrdEvntIndictr : 42|2@1+ (1,0) [0|3] "" Vector__XXX
SG_ PredictCrsCtrlDrvlineDisengInhRq : 44|2@1+ (1,0) [0|3] "" Vector__XXX
SG_ RoadwayNextGradeDistance : 48|8@1+ (25,0) [0|6250] "m" Vector__XXX

BO_ 2565920510 DCAC_AI1_CMD: 8 Vector__XXX
SG_ DCACAccssryInvert1DevMaximumFreq : 0|8@1+ (1,0) [0|250] "Hz" Vector__XXX
SG_ DCACAccssryInvert1DevMinimumFreq : 8|8@1+ (1,0) [0|250] "Hz" Vector__XXX
SG_ DCACAccssryInverter1DevRatedFreq : 16|8@1+ (1,0) [0|250] "Hz" Vector__XXX
SG_ DCACAccryInvert1DevRatedRMSVltg : 24|8@1+ (2,0) [0|500] "Vrms" Vector__XXX
SG_ DCACAccryInv1DevFreqRateChgLmt : 32|8@1+ (2,0) [0|500] "Hz/s" Vector__XXX
SG_ DCACAccssryInverter1FrequencyCmd : 40|8@1+ (1,0) [0|250] "Hz" Vector__XXX
SG_ DCACAccssryInverter1Dev1Status : 48|3@1+ (1,0) [0|7] "" Vector__XXX
SG_ DCACAccssryInverter1Dev2Status : 51|3@1+ (1,0) [0|7] "" Vector__XXX
SG_ DCACAccssryInvert1OperationalCmd : 54|2@1+ (1,0) [0|3] "" Vector__XXX
SG_ DCACAccInv1ACSdeMtrStrtRMSVltgRq : 56|8@1+ (2,0) [0|500] "Vrms" Vector__XXX

BO_ 2565920766 DCAC_AI1_FDBK: 8 Vector__XXX
SG_ DCACAccessoryInverter1Frequency : 0|8@1+ (1,0) [0|250] "Hz" Vector__XXX
SG_ DCACAccssryInvert1ACSdeRMSVltg : 8|8@1+ (2,0) [0|500] "Vrms" Vector__XXX
SG_ DCACAccssryInverter1ACSidePower : 16|8@1+ (0.1,0) [0|25] "kW" Vector__XXX
SG_ DCACAccssryInvert1ACSideRMSCurr : 24|16@1+ (0.03125,0) [0|2007.96875] "Arms" Vector__XXX
SG_ DCACAccssryInvert1OpalStatus : 48|3@1+ (1,0) [0|7] "" Vector__XXX
SG_ DCACAccssryInvert1LoadshedRq : 51|2@1+ (1,0) [0|3] "" Vector__XXX
SG_ DCACAccessoryInverter1HVILStatus : 53|2@1+ (1,0) [0|3] "" Vector__XXX

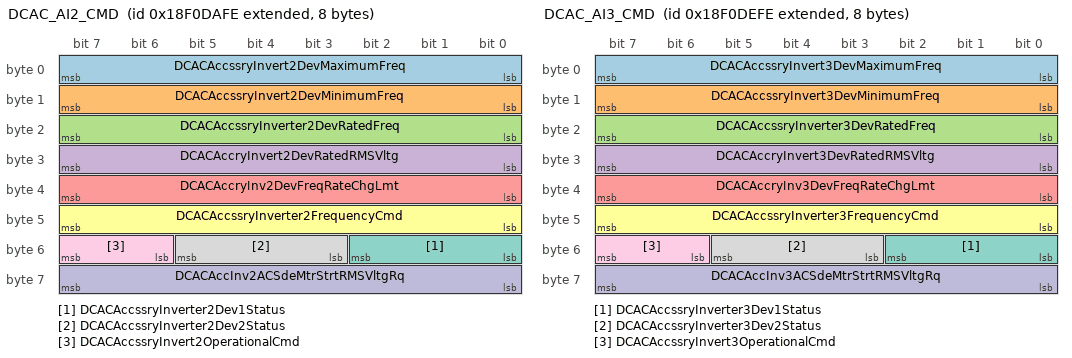
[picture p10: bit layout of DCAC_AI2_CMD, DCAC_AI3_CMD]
BO_ 2565921534 DCAC_AI2_CMD: 8 Vector__XXX
SG_ DCACAccssryInvert2DevMaximumFreq : 0|8@1+ (1,0) [0|250] "Hz" Vector__XXX
SG_ DCACAccssryInvert2DevMinimumFreq : 8|8@1+ (1,0) [0|250] "Hz" Vector__XXX
SG_ DCACAccssryInverter2DevRatedFreq : 16|8@1+ (1,0) [0|250] "Hz" Vector__XXX
SG_ DCACAccryInvert2DevRatedRMSVltg : 24|8@1+ (2,0) [0|500] "Vrms" Vector__XXX
SG_ DCACAccryInv2DevFreqRateChgLmt : 32|8@1+ (2,0) [0|500] "Hz/s" Vector__XXX
SG_ DCACAccssryInverter2FrequencyCmd : 40|8@1+ (1,0) [0|250] "Hz" Vector__XXX
SG_ DCACAccssryInverter2Dev1Status : 48|3@1+ (1,0) [0|7] "" Vector__XXX
SG_ DCACAccssryInverter2Dev2Status : 51|3@1+ (1,0) [0|7] "" Vector__XXX
SG_ DCACAccssryInvert2OperationalCmd : 54|2@1+ (1,0) [0|3] "" Vector__XXX
SG_ DCACAccInv2ACSdeMtrStrtRMSVltgRq : 56|8@1+ (2,0) [0|500] "Vrms" Vector__XXX

BO_ 2565921790 DCAC_AI2_FDBK: 8 Vector__XXX
SG_ DCACAccessoryInverter2Frequency : 0|8@1+ (1,0) [0|250] "Hz" Vector__XXX
SG_ DCACAccssryInvert2ACSdeRMSVltg : 8|8@1+ (2,0) [0|500] "Vrms" Vector__XXX
SG_ DCACAccssryInverter2ACSidePower : 16|8@1+ (0.1,0) [0|25] "kW" Vector__XXX
SG_ DCACAccssryInvert2ACSideRMSCurr : 24|16@1+ (0.03125,0) [0|2007.96875] "Arms" Vector__XXX
SG_ DCACAccssryInvert2OpalStatus : 48|3@1+ (1,0) [0|7] "" Vector__XXX
SG_ DCACAccssryInvert2LoadshedRq : 51|2@1+ (1,0) [0|3] "" Vector__XXX
SG_ DCACAccessoryInverter2HVILStatus : 53|2@1+ (1,0) [0|3] "" Vector__XXX

BO_ 2565922558 DCAC_AI3_CMD: 8 Vector__XXX
SG_ DCACAccssryInvert3DevMaximumFreq : 0|8@1+ (1,0) [0|250] "Hz" Vector__XXX
SG_ DCACAccssryInvert3DevMinimumFreq : 8|8@1+ (1,0) [0|250] "Hz" Vector__XXX
SG_ DCACAccssryInverter3DevRatedFreq : 16|8@1+ (1,0) [0|250] "Hz" Vector__XXX
SG_ DCACAccryInvert3DevRatedRMSVltg : 24|8@1+ (2,0) [0|500] "Vrms" Vector__XXX
SG_ DCACAccryInv3DevFreqRateChgLmt : 32|8@1+ (2,0) [0|500] "Hz/s" Vector__XXX
SG_ DCACAccssryInverter3FrequencyCmd : 40|8@1+ (1,0) [0|250] "Hz" Vector__XXX
SG_ DCACAccssryInverter3Dev1Status : 48|3@1+ (1,0) [0|7] "" Vector__XXX
SG_ DCACAccssryInverter3Dev2Status : 51|3@1+ (1,0) [0|7] "" Vector__XXX
SG_ DCACAccssryInvert3OperationalCmd : 54|2@1+ (1,0) [0|3] "" Vector__XXX
SG_ DCACAccInv3ACSdeMtrStrtRMSVltgRq : 56|8@1+ (2,0) [0|500] "Vrms" Vector__XXX

BO_ 2565922814 DCAC_AI3_FDBK: 8 Vector__XXX
SG_ DCACAccessoryInverter3Frequency : 0|8@1+ (1,0) [0|250] "Hz" Vector__XXX
SG_ DCACAccssryInvert3ACSdeRMSVltg : 8|8@1+ (2,0) [0|500] "Vrms" Vector__XXX
SG_ DCACAccssryInverter3ACSidePower : 16|8@1+ (0.1,0) [0|25] "kW" Vector__XXX
SG_ DCACAccssryInvert3ACSideRMSCurr : 24|16@1+ (0.03125,0) [0|2007.96875] "Arms" Vector__XXX
SG_ DCACAccssryInvert3OpalStatus : 48|3@1+ (1,0) [0|7] "" Vector__XXX
SG_ DCACAccssryInvert3LoadshedRq : 51|2@1+ (1,0) [0|3] "" Vector__XXX
SG_ DCACAccessoryInverter3HVILStatus : 53|2@1+ (1,0) [0|3] "" Vector__XXX

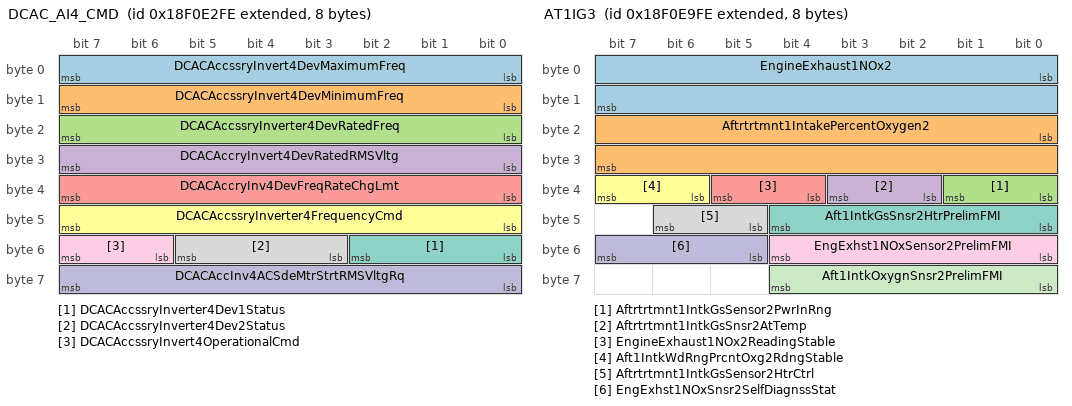
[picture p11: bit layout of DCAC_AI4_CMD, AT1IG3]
BO_ 2565923582 DCAC_AI4_CMD: 8 Vector__XXX
SG_ DCACAccssryInvert4DevMaximumFreq : 0|8@1+ (1,0) [0|250] "Hz" Vector__XXX
SG_ DCACAccssryInvert4DevMinimumFreq : 8|8@1+ (1,0) [0|250] "Hz" Vector__XXX
SG_ DCACAccssryInverter4DevRatedFreq : 16|8@1+ (1,0) [0|250] "Hz" Vector__XXX
SG_ DCACAccryInvert4DevRatedRMSVltg : 24|8@1+ (2,0) [0|500] "Vrms" Vector__XXX
SG_ DCACAccryInv4DevFreqRateChgLmt : 32|8@1+ (2,0) [0|500] "Hz/s" Vector__XXX
SG_ DCACAccssryInverter4FrequencyCmd : 40|8@1+ (1,0) [0|250] "Hz" Vector__XXX
SG_ DCACAccssryInverter4Dev1Status : 48|3@1+ (1,0) [0|7] "" Vector__XXX
SG_ DCACAccssryInverter4Dev2Status : 51|3@1+ (1,0) [0|7] "" Vector__XXX
SG_ DCACAccssryInvert4OperationalCmd : 54|2@1+ (1,0) [0|3] "" Vector__XXX
SG_ DCACAccInv4ACSdeMtrStrtRMSVltgRq : 56|8@1+ (2,0) [0|500] "Vrms" Vector__XXX

BO_ 2565923838 DCAC_AI4_FDBK: 8 Vector__XXX
SG_ DCACAccessoryInverter4Frequency : 0|8@1+ (1,0) [0|250] "Hz" Vector__XXX
SG_ DCACAccssryInvert4ACSdeRMSVltg : 8|8@1+ (2,0) [0|500] "Vrms" Vector__XXX
SG_ DCACAccssryInverter4ACSidePower : 16|8@1+ (0.1,0) [0|25] "kW" Vector__XXX
SG_ DCACAccssryInvert4ACSideRMSCurr : 24|16@1+ (0.03125,0) [0|2007.96875] "Arms" Vector__XXX
SG_ DCACAccssryInvert4OpalStatus : 48|3@1+ (1,0) [0|7] "" Vector__XXX
SG_ DCACAccssryInvert4LoadshedRq : 51|2@1+ (1,0) [0|3] "" Vector__XXX
SG_ DCACAccessoryInverter4HVILStatus : 53|2@1+ (1,0) [0|3] "" Vector__XXX

BO_ 2565924094 HRTBTM: 0 Vector__XXX

BO_ 2364597758 ITO1: 8 Vector__XXX
SG_ EngineCyl1IgnitionTimingOffset : 0|8@1+ (0.1,-12.5) [-12.5|12.5] "deg" Vector__XXX
SG_ EngineCyl2IgnitionTimingOffset : 8|8@1+ (0.1,-12.5) [-12.5|12.5] "deg" Vector__XXX
SG_ EngineCyl3IgnitionTimingOffset : 16|8@1+ (0.1,-12.5) [-12.5|12.5] "deg" Vector__XXX
SG_ EngineCyl4IgnitionTimingOffset : 24|8@1+ (0.1,-12.5) [-12.5|12.5] "deg" Vector__XXX
SG_ EngineCyl5IgnitionTimingOffset : 32|8@1+ (0.1,-12.5) [-12.5|12.5] "deg" Vector__XXX
SG_ EngineCyl6IgnitionTimingOffset : 40|8@1+ (0.1,-12.5) [-12.5|12.5] "deg" Vector__XXX
SG_ EngineCyl7IgnitionTimingOffset : 48|8@1+ (0.1,-12.5) [-12.5|12.5] "deg" Vector__XXX
SG_ EngineCyl8IgnitionTimingOffset : 56|8@1+ (0.1,-12.5) [-12.5|12.5] "deg" Vector__XXX

BO_ 2364598014 ITO2: 8 Vector__XXX
SG_ EngineCyl9IgnitionTimingOffset : 0|8@1+ (0.1,-12.5) [-12.5|12.5] "deg" Vector__XXX
SG_ EngineCyl10IgnitionTimingOffset : 8|8@1+ (0.1,-12.5) [-12.5|12.5] "deg" Vector__XXX
SG_ EngineCyl11IgnitionTimingOffset : 16|8@1+ (0.1,-12.5) [-12.5|12.5] "deg" Vector__XXX
SG_ EngineCyl12IgnitionTimingOffset : 24|8@1+ (0.1,-12.5) [-12.5|12.5] "deg" Vector__XXX
SG_ EngineCyl13IgnitionTimingOffset : 32|8@1+ (0.1,-12.5) [-12.5|12.5] "deg" Vector__XXX
SG_ EngineCyl14IgnitionTimingOffset : 40|8@1+ (0.1,-12.5) [-12.5|12.5] "deg" Vector__XXX
SG_ EngineCyl15IgnitionTimingOffset : 48|8@1+ (0.1,-12.5) [-12.5|12.5] "deg" Vector__XXX
SG_ EngineCyl16IgnitionTimingOffset : 56|8@1+ (0.1,-12.5) [-12.5|12.5] "deg" Vector__XXX

BO_ 2364598270 ITO3: 8 Vector__XXX
SG_ EngineCyl17IgnitionTimingOffset : 0|8@1+ (0.1,-12.5) [-12.5|12.5] "deg" Vector__XXX
SG_ EngineCyl18IgnitionTimingOffset : 8|8@1+ (0.1,-12.5) [-12.5|12.5] "deg" Vector__XXX
SG_ EngineCyl19IgnitionTimingOffset : 16|8@1+ (0.1,-12.5) [-12.5|12.5] "deg" Vector__XXX
SG_ EngineCyl20IgnitionTimingOffset : 24|8@1+ (0.1,-12.5) [-12.5|12.5] "deg" Vector__XXX
SG_ EngineCyl21IgnitionTimingOffset : 32|8@1+ (0.1,-12.5) [-12.5|12.5] "deg" Vector__XXX
SG_ EngineCyl22IgnitionTimingOffset : 40|8@1+ (0.1,-12.5) [-12.5|12.5] "deg" Vector__XXX
SG_ EngineCyl23IgnitionTimingOffset : 48|8@1+ (0.1,-12.5) [-12.5|12.5] "deg" Vector__XXX
SG_ EngineCyl24IgnitionTimingOffset : 56|8@1+ (0.1,-12.5) [-12.5|12.5] "deg" Vector__XXX

BO_ 2364598526 TFAC2: 8 Vector__XXX
SG_ EngineFuelActr3ControlCommand : 32|16@1+ (0.0025,0) [0|160.6375] "%" Vector__XXX
SG_ EngineFuelActr4ControlCommand : 48|16@1+ (0.0025,0) [0|160.6375] "%" Vector__XXX

BO_ 2565925374 AT1IG3: 8 Vector__XXX
SG_ EngineExhaust1NOx2 : 0|16@1+ (0.05,-200) [-200|3012.75] "ppm" Vector__XXX
SG_ Aftrtrtmnt1IntakePercentOxygen2 : 16|16@1+ (0.000514,-12) [-12|21.02707] "%" Vector__XXX
SG_ Aftrtrtmnt1IntkGsSensor2PwrInRng : 32|2@1+ (1,0) [0|3] "" Vector__XXX
SG_ Aftrtrtmnt1IntkGsSnsr2AtTemp : 34|2@1+ (1,0) [0|3] "" Vector__XXX
SG_ EngineExhaust1NOx2ReadingStable : 36|2@1+ (1,0) [0|3] "" Vector__XXX
SG_ Aft1IntkWdRngPrcntOxg2RdngStable : 38|2@1+ (1,0) [0|3] "" Vector__XXX
SG_ Aft1IntkGsSnsr2HtrPrelimFMI : 40|5@1+ (1,0) [0|31] "" Vector__XXX
SG_ Aftrtrtmnt1IntkGsSensor2HtrCtrl : 45|2@1+ (1,0) [0|3] "" Vector__XXX
SG_ EngExhst1NOxSensor2PrelimFMI : 48|5@1+ (1,0) [0|31] "" Vector__XXX
SG_ EngExhst1NOxSnsr2SelfDiagnssStat : 53|3@1+ (1,0) [0|7] "" Vector__XXX
SG_ Aft1IntkOxygnSnsr2PrelimFMI : 56|5@1+ (1,0) [0|31] "" Vector__XXX

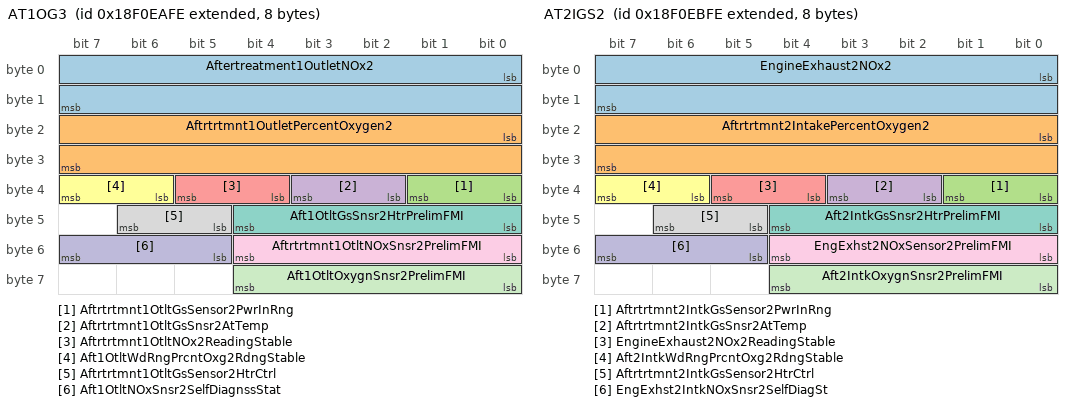
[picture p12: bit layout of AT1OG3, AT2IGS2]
BO_ 2565925630 AT1OG3: 8 Vector__XXX
SG_ Aftertreatment1OutletNOx2 : 0|16@1+ (0.05,-200) [-200|3012.75] "ppm" Vector__XXX
SG_ Aftrtrtmnt1OutletPercentOxygen2 : 16|16@1+ (0.000514,-12) [-12|21.02707] "%" Vector__XXX
SG_ Aftrtrtmnt1OtltGsSensor2PwrInRng : 32|2@1+ (1,0) [0|3] "" Vector__XXX
SG_ Aftrtrtmnt1OtltGsSnsr2AtTemp : 34|2@1+ (1,0) [0|3] "" Vector__XXX
SG_ Aftrtrtmnt1OtltNOx2ReadingStable : 36|2@1+ (1,0) [0|3] "" Vector__XXX
SG_ Aft1OtltWdRngPrcntOxg2RdngStable : 38|2@1+ (1,0) [0|3] "" Vector__XXX
SG_ Aft1OtltGsSnsr2HtrPrelimFMI : 40|5@1+ (1,0) [0|31] "" Vector__XXX
SG_ Aftrtrtmnt1OtltGsSensor2HtrCtrl : 45|2@1+ (1,0) [0|3] "" Vector__XXX
SG_ Aftrtrtmnt1OtltNOxSnsr2PrelimFMI : 48|5@1+ (1,0) [0|31] "" Vector__XXX
SG_ Aft1OtltNOxSnsr2SelfDiagnssStat : 53|3@1+ (1,0) [0|7] "" Vector__XXX
SG_ Aft1OtltOxygnSnsr2PrelimFMI : 56|5@1+ (1,0) [0|31] "" Vector__XXX

BO_ 2565925886 AT2IGS2: 8 Vector__XXX
SG_ EngineExhaust2NOx2 : 0|16@1+ (0.05,-200) [-200|3012.75] "ppm" Vector__XXX
SG_ Aftrtrtmnt2IntakePercentOxygen2 : 16|16@1+ (0.000514,-12) [-12|21.02707] "%" Vector__XXX
SG_ Aftrtrtmnt2IntkGsSensor2PwrInRng : 32|2@1+ (1,0) [0|3] "" Vector__XXX
SG_ Aftrtrtmnt2IntkGsSnsr2AtTemp : 34|2@1+ (1,0) [0|3] "" Vector__XXX
SG_ EngineExhaust2NOx2ReadingStable : 36|2@1+ (1,0) [0|3] "" Vector__XXX
SG_ Aft2IntkWdRngPrcntOxg2RdngStable : 38|2@1+ (1,0) [0|3] "" Vector__XXX
SG_ Aft2IntkGsSnsr2HtrPrelimFMI : 40|5@1+ (1,0) [0|31] "" Vector__XXX
SG_ Aftrtrtmnt2IntkGsSensor2HtrCtrl : 45|2@1+ (1,0) [0|3] "" Vector__XXX
SG_ EngExhst2NOxSensor2PrelimFMI : 48|5@1+ (1,0) [0|31] "" Vector__XXX
SG_ EngExhst2IntkNOxSnsr2SelfDiagSt : 53|3@1+ (1,0) [0|7] "" Vector__XXX
SG_ Aft2IntkOxygnSnsr2PrelimFMI : 56|5@1+ (1,0) [0|31] "" Vector__XXX

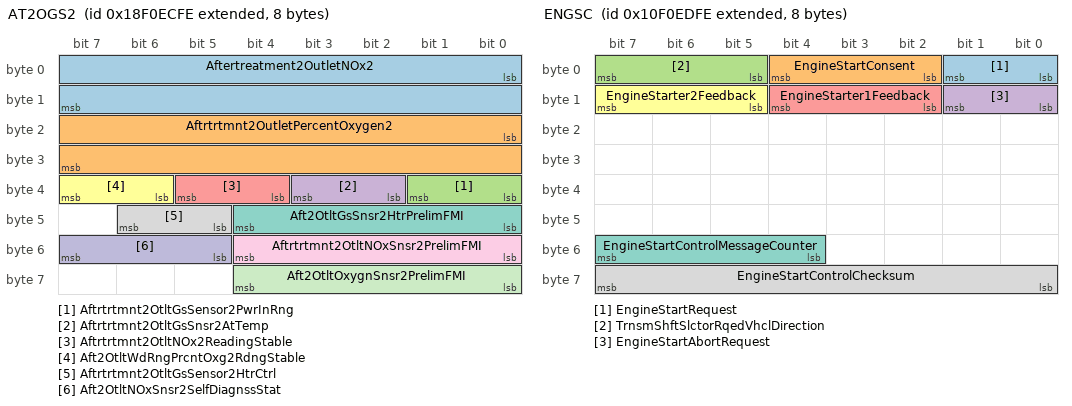
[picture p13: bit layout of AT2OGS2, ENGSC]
BO_ 2565926142 AT2OGS2: 8 Vector__XXX
SG_ Aftertreatment2OutletNOx2 : 0|16@1+ (0.05,-200) [-200|3012.75] "ppm" Vector__XXX
SG_ Aftrtrtmnt2OutletPercentOxygen2 : 16|16@1+ (0.000514,-12) [-12|21.02707] "%" Vector__XXX
SG_ Aftrtrtmnt2OtltGsSensor2PwrInRng : 32|2@1+ (1,0) [0|3] "" Vector__XXX
SG_ Aftrtrtmnt2OtltGsSnsr2AtTemp : 34|2@1+ (1,0) [0|3] "" Vector__XXX
SG_ Aftrtrtmnt2OtltNOx2ReadingStable : 36|2@1+ (1,0) [0|3] "" Vector__XXX
SG_ Aft2OtltWdRngPrcntOxg2RdngStable : 38|2@1+ (1,0) [0|3] "" Vector__XXX
SG_ Aft2OtltGsSnsr2HtrPrelimFMI : 40|5@1+ (1,0) [0|31] "" Vector__XXX
SG_ Aftrtrtmnt2OtltGsSensor2HtrCtrl : 45|2@1+ (1,0) [0|3] "" Vector__XXX
SG_ Aftrtrtmnt2OtltNOxSnsr2PrelimFMI : 48|5@1+ (1,0) [0|31] "" Vector__XXX
SG_ Aft2OtltNOxSnsr2SelfDiagnssStat : 53|3@1+ (1,0) [0|7] "" Vector__XXX
SG_ Aft2OtltOxygnSnsr2PrelimFMI : 56|5@1+ (1,0) [0|31] "" Vector__XXX

BO_ 2431708670 ENGSC: 8 Vector__XXX
SG_ EngineStartRequest : 0|2@1+ (1,0) [0|3] "" Vector__XXX
SG_ EngineStartConsent : 2|3@1+ (1,0) [0|7] "" Vector__XXX
SG_ TrnsmShftSlctorRqedVhclDirection : 5|3@1+ (1,0) [0|7] "" Vector__XXX
SG_ EngineStartAbortRequest : 8|2@1+ (1,0) [0|3] "" Vector__XXX
SG_ EngineStarter1Feedback : 10|3@1+ (1,0) [0|7] "" Vector__XXX
SG_ EngineStarter2Feedback : 13|3@1+ (1,0) [0|7] "" Vector__XXX
SG_ EngineStartControlMessageCounter : 52|4@1+ (1,0) [0|15] "" Vector__XXX
SG_ EngineStartControlChecksum : 56|8@1+ (1,0) [0|255] "" Vector__XXX

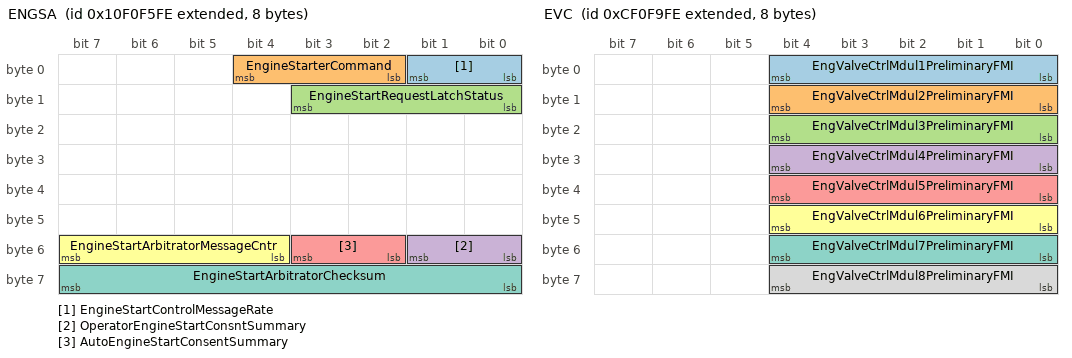
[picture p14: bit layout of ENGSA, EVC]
BO_ 2431710718 ENGSA: 8 Vector__XXX
SG_ EngineStartControlMessageRate : 0|2@1+ (1,0) [0|3] "" Vector__XXX
SG_ EngineStarterCommand : 2|3@1+ (1,0) [0|7] "" Vector__XXX
SG_ EngineStartRequestLatchStatus : 8|4@1+ (1,0) [0|15] "" Vector__XXX
SG_ OperatorEngineStartConsntSummary : 48|2@1+ (1,0) [0|3] "" Vector__XXX
SG_ AutoEngineStartConsentSummary : 50|2@1+ (1,0) [0|3] "" Vector__XXX
SG_ EngineStartArbitratorMessageCntr : 52|4@1+ (1,0) [0|15] "" Vector__XXX
SG_ EngineStartArbitratorChecksum : 56|8@1+ (1,0) [0|255] "" Vector__XXX

BO_ 2364602878 EVC: 8 Vector__XXX
SG_ EngValveCtrlMdul1PreliminaryFMI : 0|5@1+ (1,0) [0|31] "" Vector__XXX
SG_ EngValveCtrlMdul2PreliminaryFMI : 8|5@1+ (1,0) [0|31] "" Vector__XXX
SG_ EngValveCtrlMdul3PreliminaryFMI : 16|5@1+ (1,0) [0|31] "" Vector__XXX
SG_ EngValveCtrlMdul4PreliminaryFMI : 24|5@1+ (1,0) [0|31] "" Vector__XXX
SG_ EngValveCtrlMdul5PreliminaryFMI : 32|5@1+ (1,0) [0|31] "" Vector__XXX
SG_ EngValveCtrlMdul6PreliminaryFMI : 40|5@1+ (1,0) [0|31] "" Vector__XXX
SG_ EngValveCtrlMdul7PreliminaryFMI : 48|5@1+ (1,0) [0|31] "" Vector__XXX
SG_ EngValveCtrlMdul8PreliminaryFMI : 56|5@1+ (1,0) [0|31] "" Vector__XXX

BO_ 2364603134 ETC13: 8 Vector__XXX
SG_ MaxFrwdTransmissionOutptShftSpd : 0|16@1+ (0.125,0) [0|8031.875] "rpm" Vector__XXX
SG_ MaxReverseTrnsmOutptShftSpd : 16|16@1+ (0.125,0) [0|8031.875] "rpm" Vector__XXX
SG_ SrcAddrActvPendingTrnsmRqedGear : 32|8@1+ (1,0) [0|255] "" Vector__XXX

BO_ 2364603390 A1SCRDSR3: 8 Vector__XXX
SG_ Aft1DslExhstFldRqedQtyIntgrtr : 0|16@1+ (0.001,0) [0|64.255] "g" Vector__XXX
SG_ Aft1DslExhstFldDoserVlv1Cmd : 16|16@1+ (0.0025,0) [0|160.6375] "%" Vector__XXX

BO_ 2364603646 A2SCRDSR3: 8 Vector__XXX
SG_ Aft2DslExhstFldRqedQtyIntgrtr : 0|16@1+ (0.001,0) [0|64.255] "g" Vector__XXX

BO_ 2364603902 A1SCRDSI4: 8 Vector__XXX
SG_ Aft1DslExhstFldActlQtyIntgrtr : 0|16@1+ (0.001,0) [0|64.255] "g" Vector__XXX

BO_ 2364604158 A2SCRDSI4: 8 Vector__XXX
SG_ Aft2DslExhstFldActlQtyIntgrtr : 0|16@1+ (0.001,0) [0|64.255] "g" Vector__XXX

BO_ 2364604414 SHRP: 8 Vector__XXX
SG_ FrontHitchRollAngle : 0|16@1+ (0.002,-64) [-64|64.51] "deg" Vector__XXX
SG_ FrontHitchRollLimitState : 21|3@1+ (1,0) [0|7] "" Vector__XXX
SG_ FrontHitchRollExitReasonCode : 24|6@1+ (1,0) [0|63] "" Vector__XXX
SG_ FrontHitchPitchAngle : 32|16@1+ (0.002,-64) [-64|64.51] "deg" Vector__XXX
SG_ FrontHitchPitchLimitState : 53|3@1+ (1,0) [0|7] "" Vector__XXX
SG_ FrontHitchPitchExitReasonCode : 56|6@1+ (1,0) [0|63] "" Vector__XXX

BO_ 2364604670 SHRPC: 8 Vector__XXX
SG_ FrontHitchRollCommand : 0|16@1+ (0.002,-64) [-64|64.51] "deg" Vector__XXX
SG_ FrontHitchRollSensitivityCommand : 16|8@1+ (0.4,0) [0|100] "%" Vector__XXX
SG_ FrontHitchPitchCommand : 24|16@1+ (0.002,-64) [-64|64.51] "deg" Vector__XXX
SG_ FrontHitchPitchSensitivityCmd : 40|8@1+ (0.4,0) [0|100] "%" Vector__XXX

BO_ 2364604926 PHRP: 8 Vector__XXX
SG_ RearHitchRollAngle : 0|16@1+ (0.002,-64) [-64|64.51] "deg" Vector__XXX
SG_ RearHitchRollLimitState : 21|3@1+ (1,0) [0|7] "" Vector__XXX
SG_ RearHitchRollExitReasonCode : 24|6@1+ (1,0) [0|63] "" Vector__XXX
SG_ RearHitchPitchAngle : 32|16@1+ (0.002,-64) [-64|64.51] "deg" Vector__XXX
SG_ RearHitchPitchLimitState : 53|3@1+ (1,0) [0|7] "" Vector__XXX
SG_ RearHitchPitchExitReasonCode : 56|6@1+ (1,0) [0|63] "" Vector__XXX

BO_ 2364605182 PHRPC: 8 Vector__XXX
SG_ RearHitchRollCommand : 0|16@1+ (0.002,-64) [-64|64.51] "deg" Vector__XXX
SG_ RearHitchRollSensitivityCommand : 16|8@1+ (0.4,0) [0|100] "%" Vector__XXX
SG_ RearHitchPitchCommand : 24|16@1+ (0.002,-64) [-64|64.51] "deg" Vector__XXX
SG_ RearHitchPitchSensitivityCommand : 40|8@1+ (0.4,0) [0|100] "%" Vector__XXX

BO_ 2364605438 GTRACE: 8 Vector__XXX
SG_ GeneratorTripKWHoursExport : 0|32@1+ (1,0) [0|4211081215] "kWh" Vector__XXX
SG_ GeneratorTripKVArHoursExport : 32|32@1+ (1,0) [0|4211081215] "kVArh" Vector__XXX

BO_ 2565932286 ESSI2: 8 Vector__XXX
SG_ EngineSpeed4 : 0|16@1+ (0.5,0) [0|32127.5] "rpm" Vector__XXX

BO_ 2364605950 HPD: 8 Vector__XXX
SG_ HydraulicLinePressure : 0|16@1+ (1,0) [0|64255] "kPa" Vector__XXX
SG_ MechanicalMovementAngle : 16|16@1+ (0.0078125,0) [0|501.99] "deg" Vector__XXX

BO_ 2565932798 WSP1: 8 Vector__XXX
SG_ WellStimulationPumpSuctionPress : 0|16@1+ (0.1,-3212.7) [-3212.7|3212.8] "kPa" Vector__XXX
SG_ WellStimulationPumpDisChrgPress : 16|16@1+ (5,0) [0|321275] "kPa" Vector__XXX

BO_ 2565933054 WSP2: 8 Vector__XXX
SG_ WellStimulationPmpGearBoxOilPrs : 0|16@1+ (0.1,0) [0|6425.5] "kPa" Vector__XXX
SG_ WellStimulationPmpGearBoxOilTemp : 16|8@1+ (1,-40) [-40|210] "deg C" Vector__XXX
SG_ WellStimulationPumpSpeed : 24|16@1+ (0.125,0) [0|8031.875] "rpm" Vector__XXX
SG_ WellStimultnPmpGerBxOtltOilTemp : 40|8@1+ (1,-40) [-40|210] "deg C" Vector__XXX

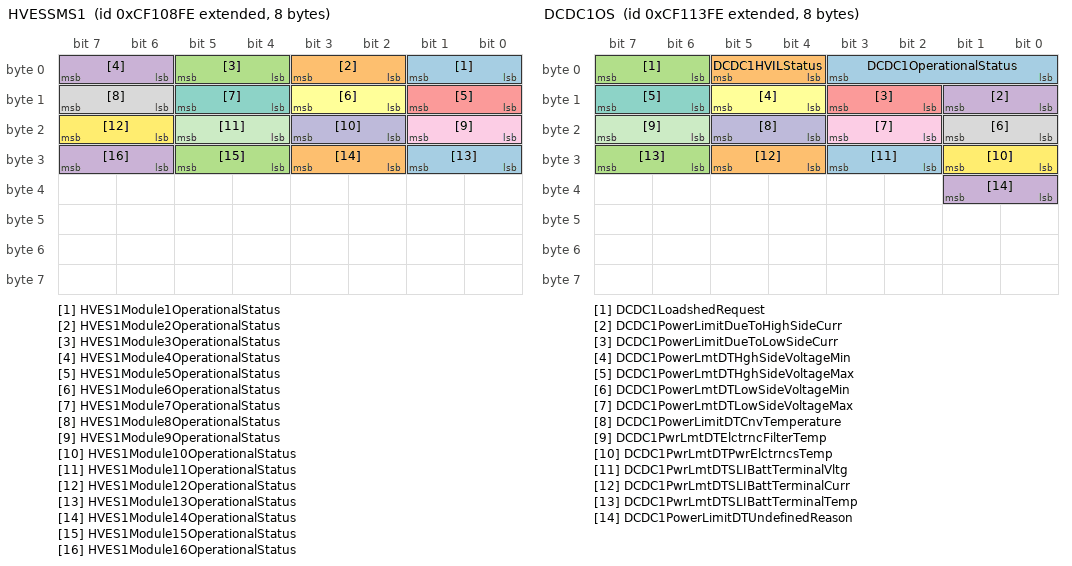
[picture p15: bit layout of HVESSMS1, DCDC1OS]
BO_ 2364606718 HVESSMS1: 8 Vector__XXX
SG_ HVES1Module1OperationalStatus : 0|2@1+ (1,0) [0|3] "" Vector__XXX
SG_ HVES1Module2OperationalStatus : 2|2@1+ (1,0) [0|3] "" Vector__XXX
SG_ HVES1Module3OperationalStatus : 4|2@1+ (1,0) [0|3] "" Vector__XXX
SG_ HVES1Module4OperationalStatus : 6|2@1+ (1,0) [0|3] "" Vector__XXX
SG_ HVES1Module5OperationalStatus : 8|2@1+ (1,0) [0|3] "" Vector__XXX
SG_ HVES1Module6OperationalStatus : 10|2@1+ (1,0) [0|3] "" Vector__XXX
SG_ HVES1Module7OperationalStatus : 12|2@1+ (1,0) [0|3] "" Vector__XXX
SG_ HVES1Module8OperationalStatus : 14|2@1+ (1,0) [0|3] "" Vector__XXX
SG_ HVES1Module9OperationalStatus : 16|2@1+ (1,0) [0|3] "" Vector__XXX
SG_ HVES1Module10OperationalStatus : 18|2@1+ (1,0) [0|3] "" Vector__XXX
SG_ HVES1Module11OperationalStatus : 20|2@1+ (1,0) [0|3] "" Vector__XXX
SG_ HVES1Module12OperationalStatus : 22|2@1+ (1,0) [0|3] "" Vector__XXX
SG_ HVES1Module13OperationalStatus : 24|2@1+ (1,0) [0|3] "" Vector__XXX
SG_ HVES1Module14OperationalStatus : 26|2@1+ (1,0) [0|3] "" Vector__XXX
SG_ HVES1Module15OperationalStatus : 28|2@1+ (1,0) [0|3] "" Vector__XXX
SG_ HVES1Module16OperationalStatus : 30|2@1+ (1,0) [0|3] "" Vector__XXX

BO_ 2364606974 HVESSTS1: 8 Vector__XXX
SG_ HVES1ThermalMangmntSysSLIInptPwr : 0|16@1+ (0.5,0) [0|32127.5] "W" Vector__XXX
SG_ HVES1ThrmlMngmtSysHiVltgInptPwr : 16|16@1+ (0.5,0) [0|32127.5] "W" Vector__XXX
SG_ HVES1ThrmlMangmntSysCmprssorSpd : 32|8@1+ (32,0) [0|8000] "rpm" Vector__XXX
SG_ HVES1ThermalMangmntSysRelHumidty : 40|8@1+ (0.4,0) [0|100] "%" Vector__XXX
SG_ HVES1ThermalMangmntSystemHtrStat : 48|2@1+ (1,0) [0|3] "" Vector__XXX
SG_ HVESSThermalMangmntSysHVILStat : 50|2@1+ (1,0) [0|3] "" Vector__XXX
SG_ HVES1ThermalManagementSystemMode : 52|4@1+ (1,0) [0|15] "" Vector__XXX

BO_ 2364607230 HVESSD8: 8 Vector__XXX
SG_ HVES1HghestCellVoltageMdulNumber : 0|8@1+ (1,0) [0|250] "" Vector__XXX
SG_ HVES1HghestCellVoltageCellNumber : 8|8@1+ (1,0) [0|250] "" Vector__XXX
SG_ HVES1LowestCellVoltageMdulNumber : 16|8@1+ (1,0) [0|250] "" Vector__XXX
SG_ HVES1LowestCellVoltageCellNumber : 24|8@1+ (1,0) [0|250] "" Vector__XXX
SG_ HVES1AverageCellVoltage : 32|16@1+ (0.001,0) [0|64.255] "V" Vector__XXX

BO_ 2364607486 HVESSD9: 8 Vector__XXX
SG_ HVES1HghestCellTemperatureMdulNo : 0|8@1+ (1,0) [0|250] "" Vector__XXX
SG_ HVES1HghestCellTemperatureCellNo : 8|8@1+ (1,0) [0|250] "" Vector__XXX
SG_ HVES1LowestCellTemperatureMdulNo : 16|8@1+ (1,0) [0|250] "" Vector__XXX
SG_ HVES1LowestCellTemperatureCellNo : 24|8@1+ (1,0) [0|250] "" Vector__XXX

BO_ 2364607742 HVESSD10: 8 Vector__XXX
SG_ HVES1HghestCellStateChrgMdulNo : 0|8@1+ (1,0) [0|250] "" Vector__XXX
SG_ HVES1HghestCellStateChrgCellNo : 8|8@1+ (1,0) [0|250] "" Vector__XXX
SG_ HVES1LowestCellStateChrgMdulNo : 16|8@1+ (1,0) [0|250] "" Vector__XXX
SG_ HVES1LowestCellStateChrgCellNo : 24|8@1+ (1,0) [0|250] "" Vector__XXX
SG_ HVES1HiVltgBusActIsolatnTestRess : 32|16@1+ (0.1,0) [0|6425.5] "ohm/V" Vector__XXX
SG_ HVES1HiVltgBusPassIsolatnTtRess : 48|16@1+ (0.1,0) [0|6425.5] "ohm/V" Vector__XXX

BO_ 2565934590 GFI6: 8 Vector__XXX
SG_ EngineFuelValve2DiffPressure : 0|16@1+ (0.1,0) [0|6425.5] "kPa" Vector__XXX

BO_ 2498825982 DTBI1: 8 Vector__XXX
SG_ DumpBodyRollAngle : 0|16@1+ (0.0078125,-200) [-200|301.99] "deg" Vector__XXX
SG_ DumpBodyRaiseAngle : 16|16@1+ (0.0078125,-200) [-200|301.99] "deg" Vector__XXX
SG_ DumpBodyRaisePsRelToRecmmndedMax : 32|16@1+ (0.005,-150) [-150|171.275] "%" Vector__XXX
SG_ DumpBodyEjectorBladePosition : 48|8@1+ (0.4,0) [0|100] "%" Vector__XXX

BO_ 2364608510 EOI2: 8 Vector__XXX
SG_ EngineSelfInducedDerateLoad : 0|16@1+ (0.5,0) [0|32127.5] "kW" Vector__XXX
SG_ EnginePowerDerateRequest : 16|16@1+ (0.5,0) [0|32127.5] "kW" Vector__XXX

BO_ 2297499902 B2: 8 Vector__XXX
SG_ DemandedBrakeApplicationPressure : 0|16@1+ (0.1,0) [0|6425.5] "kPa" Vector__XXX
SG_ BrakePedalSwitch2 : 16|2@1+ (1,0) [0|3] "" Vector__XXX

BO_ 2431717886 GFP3: 8 Vector__XXX
SG_ EngineFuelValve1DiffPressure : 0|16@1+ (0.0078125,-100) [-100|401.99] "kPa" Vector__XXX
SG_ EngGasFuelSupplyFltrDiffPressure : 16|16@1+ (0.0078125,-100) [-100|401.99] "kPa" Vector__XXX
SG_ EngGsFuelSupplyFltrIntkPressure : 32|16@1+ (0.5,0) [0|32127.5] "kPa" Vector__XXX

BO_ 2364609278 DCDC1C: 8 Vector__XXX
SG_ DCDC1OperationalCommand : 0|4@1+ (1,0) [0|15] "" Vector__XXX
SG_ DCDC1LowSideVoltageBuckSetpoint : 8|16@1+ (0.01,0) [0|642.55] "V" Vector__XXX
SG_ DCDC1HghSideVoltageBoostSetpoint : 24|16@1+ (0.05,0) [0|3212.75] "V" Vector__XXX
SG_ DCDC1LowSdeVltgBuckDefltSetpnt : 40|16@1+ (0.01,0) [0|642.55] "V" Vector__XXX

BO_ 2364609534 DCDC1OS: 8 Vector__XXX
SG_ DCDC1OperationalStatus : 0|4@1+ (1,0) [0|15] "" Vector__XXX
SG_ DCDC1HVILStatus : 4|2@1+ (1,0) [0|3] "" Vector__XXX
SG_ DCDC1LoadshedRequest : 6|2@1+ (1,0) [0|3] "" Vector__XXX
SG_ DCDC1PowerLimitDueToHighSideCurr : 8|2@1+ (1,0) [0|3] "" Vector__XXX
SG_ DCDC1PowerLimitDueToLowSideCurr : 10|2@1+ (1,0) [0|3] "" Vector__XXX
SG_ DCDC1PowerLmtDTHghSideVoltageMin : 12|2@1+ (1,0) [0|3] "" Vector__XXX
SG_ DCDC1PowerLmtDTHghSideVoltageMax : 14|2@1+ (1,0) [0|3] "" Vector__XXX
SG_ DCDC1PowerLmtDTLowSideVoltageMin : 16|2@1+ (1,0) [0|3] "" Vector__XXX
SG_ DCDC1PowerLmtDTLowSideVoltageMax : 18|2@1+ (1,0) [0|3] "" Vector__XXX
SG_ DCDC1PowerLimitDTCnvTemperature : 20|2@1+ (1,0) [0|3] "" Vector__XXX
SG_ DCDC1PwrLmtDTElctrncFilterTemp : 22|2@1+ (1,0) [0|3] "" Vector__XXX
SG_ DCDC1PwrLmtDTPwrElctrncsTemp : 24|2@1+ (1,0) [0|3] "" Vector__XXX
SG_ DCDC1PwrLmtDTSLIBattTerminalVltg : 26|2@1+ (1,0) [0|3] "" Vector__XXX
SG_ DCDC1PwrLmtDTSLIBattTerminalCurr : 28|2@1+ (1,0) [0|3] "" Vector__XXX
SG_ DCDC1PwrLmtDTSLIBattTerminalTemp : 30|2@1+ (1,0) [0|3] "" Vector__XXX
SG_ DCDC1PowerLimitDTUndefinedReason : 32|2@1+ (1,0) [0|3] "" Vector__XXX

BO_ 2364609790 DCDC1VC: 8 Vector__XXX
SG_ DCDC1LowSideVoltage : 0|16@1+ (0.01,0) [0|642.55] "V" Vector__XXX
SG_ DCDC1LowSideCurrent : 16|16@1+ (0.1,-3212.7) [-3212.7|3212.8] "A" Vector__XXX
SG_ DCDC1HighSideVoltage : 32|16@1+ (0.05,0) [0|3212.75] "V" Vector__XXX
SG_ DCDC1HighSideCurrent : 48|16@1+ (0.1,-3212.7) [-3212.7|3212.8] "A" Vector__XXX

BO_ 2364610046 DCDC1SBS: 8 Vector__XXX
SG_ DCDC1SLIBatteryTerminalVoltage : 0|16@1+ (0.01,0) [0|642.55] "V" Vector__XXX
SG_ DCDC1SLIBatteryTerminalCurrent : 16|16@1+ (0.1,-3212.7) [-3212.7|3212.8] "A" Vector__XXX
SG_ DCDC1SLIBattryTerminalTemp : 32|8@1+ (1,-40) [-40|210] "deg C" Vector__XXX

BO_ 2431719166 WSP3: 8 Vector__XXX
SG_ WellStimulationPumpRodLoad : 0|16@1+ (5,0) [0|321275] "kN" Vector__XXX
SG_ WellStimulationPmpCavitationStat : 16|3@1+ (1,0) [0|7] "" Vector__XXX
SG_ WellStimultnPmpFldEndValveLeak : 20|2@1+ (1,0) [0|3] "" Vector__XXX
SG_ WellStimulationPumpFlowRate : 24|16@1+ (0.5,0) [0|32127.5] "l/min" Vector__XXX
SG_ WellStimultnPmpRatdRodLoadPrcnt : 40|8@1+ (0.5,0) [0|125] "%" Vector__XXX

BO_ 2364610558 DCDC1S2: 8 Vector__XXX
SG_ DCDC1LowSidePower : 0|16@1+ (0.05,-1600) [-1600|1612.75] "kW" Vector__XXX
SG_ DCDC1HighSidePower : 16|16@1+ (0.05,-1600) [-1600|1612.75] "kW" Vector__XXX
SG_ DCDC1HghSideNegToChssGrndVoltage : 32|16@1+ (0.05,0) [0|3212.75] "V" Vector__XXX

BO_ 2364610814 DCDC2C: 8 Vector__XXX
SG_ DCDC2OperationalCommand : 0|4@1+ (1,0) [0|15] "" Vector__XXX
SG_ DCDC2LowSideVoltageBuckSetpoint : 8|16@1+ (0.01,0) [0|642.55] "V" Vector__XXX
SG_ DCDC2HghSideVoltageBoostSetpoint : 24|16@1+ (0.05,0) [0|3212.75] "V" Vector__XXX
SG_ DCDC2LowSdeVltgBuckDefltSetpnt : 40|16@1+ (0.01,0) [0|642.55] "V" Vector__XXX

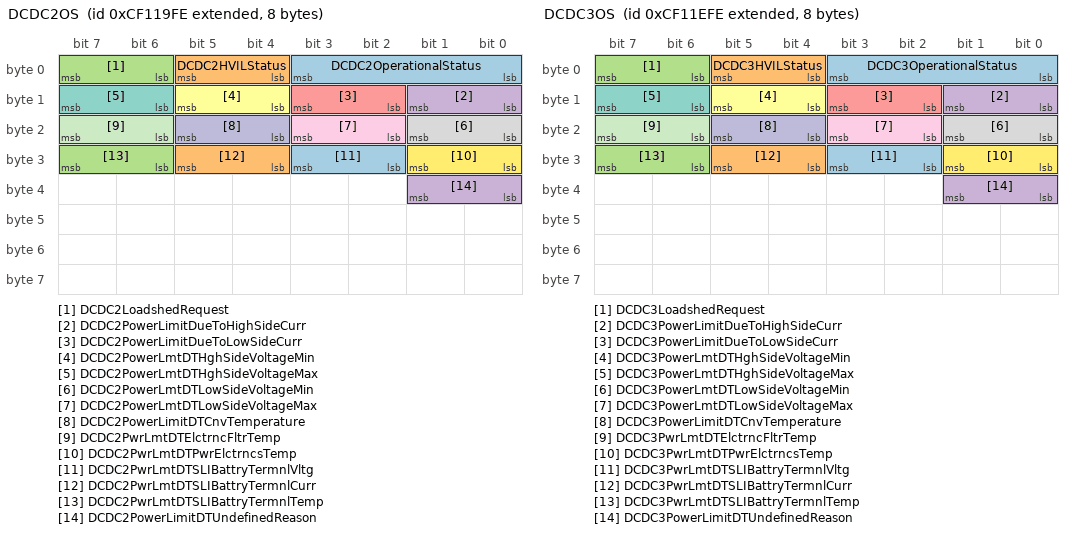
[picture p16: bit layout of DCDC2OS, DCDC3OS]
BO_ 2364611070 DCDC2OS: 8 Vector__XXX
SG_ DCDC2OperationalStatus : 0|4@1+ (1,0) [0|15] "" Vector__XXX
SG_ DCDC2HVILStatus : 4|2@1+ (1,0) [0|3] "" Vector__XXX
SG_ DCDC2LoadshedRequest : 6|2@1+ (1,0) [0|3] "" Vector__XXX
SG_ DCDC2PowerLimitDueToHighSideCurr : 8|2@1+ (1,0) [0|3] "" Vector__XXX
SG_ DCDC2PowerLimitDueToLowSideCurr : 10|2@1+ (1,0) [0|3] "" Vector__XXX
SG_ DCDC2PowerLmtDTHghSideVoltageMin : 12|2@1+ (1,0) [0|3] "" Vector__XXX
SG_ DCDC2PowerLmtDTHghSideVoltageMax : 14|2@1+ (1,0) [0|3] "" Vector__XXX
SG_ DCDC2PowerLmtDTLowSideVoltageMin : 16|2@1+ (1,0) [0|3] "" Vector__XXX
SG_ DCDC2PowerLmtDTLowSideVoltageMax : 18|2@1+ (1,0) [0|3] "" Vector__XXX
SG_ DCDC2PowerLimitDTCnvTemperature : 20|2@1+ (1,0) [0|3] "" Vector__XXX
SG_ DCDC2PwrLmtDTElctrncFltrTemp : 22|2@1+ (1,0) [0|3] "" Vector__XXX
SG_ DCDC2PwrLmtDTPwrElctrncsTemp : 24|2@1+ (1,0) [0|3] "" Vector__XXX
SG_ DCDC2PwrLmtDTSLIBattryTermnlVltg : 26|2@1+ (1,0) [0|3] "" Vector__XXX
SG_ DCDC2PwrLmtDTSLIBattryTermnlCurr : 28|2@1+ (1,0) [0|3] "" Vector__XXX
SG_ DCDC2PwrLmtDTSLIBattryTermnlTemp : 30|2@1+ (1,0) [0|3] "" Vector__XXX
SG_ DCDC2PowerLimitDTUndefinedReason : 32|2@1+ (1,0) [0|3] "" Vector__XXX

BO_ 2364611326 DCDC2VC: 8 Vector__XXX
SG_ DCDC2LowSideVoltage : 0|16@1+ (0.01,0) [0|642.55] "V" Vector__XXX
SG_ DCDC2LowSideCurrent : 16|16@1+ (0.1,-3212.7) [-3212.7|3212.8] "A" Vector__XXX
SG_ DCDC2HighSideVoltage : 32|16@1+ (0.05,0) [0|3212.75] "V" Vector__XXX
SG_ DCDC2HighSideCurrent : 48|16@1+ (0.1,-3212.7) [-3212.7|3212.8] "A" Vector__XXX

BO_ 2364611582 DCDC2SBS: 8 Vector__XXX
SG_ DCDC2SLIBatteryTerminalVoltage : 0|16@1+ (0.01,0) [0|642.55] "V" Vector__XXX
SG_ DCDC2SLIBatteryTerminalCurrent : 16|16@1+ (0.1,-3212.7) [-3212.7|3212.8] "A" Vector__XXX
SG_ DCDC2SLIBattryTerminalTemp : 32|8@1+ (1,-40) [-40|210] "deg C" Vector__XXX

BO_ 2364611838 DCDC2S2: 8 Vector__XXX
SG_ DCDC2LowSidePower : 0|16@1+ (0.05,-1600) [-1600|1612.75] "kW" Vector__XXX
SG_ DCDC2HighSidePower : 16|16@1+ (0.05,-1600) [-1600|1612.75] "kW" Vector__XXX
SG_ DCDC2HghSideNegToChssGrndVoltage : 32|16@1+ (0.05,0) [0|3212.75] "V" Vector__XXX

BO_ 2364612094 DCDC3C: 8 Vector__XXX
SG_ DCDC3OperationalCommand : 0|4@1+ (1,0) [0|15] "" Vector__XXX
SG_ DCDC3LowSideVoltageBuckSetpoint : 8|16@1+ (0.01,0) [0|642.55] "V" Vector__XXX
SG_ DCDC3HghSideVoltageBoostSetpoint : 24|16@1+ (0.05,0) [0|3212.75] "V" Vector__XXX
SG_ DCDC3LowSdeVltgBuckDefltSetpnt : 40|16@1+ (0.01,0) [0|642.55] "V" Vector__XXX

BO_ 2364612350 DCDC3OS: 8 Vector__XXX
SG_ DCDC3OperationalStatus : 0|4@1+ (1,0) [0|15] "" Vector__XXX
SG_ DCDC3HVILStatus : 4|2@1+ (1,0) [0|3] "" Vector__XXX
SG_ DCDC3LoadshedRequest : 6|2@1+ (1,0) [0|3] "" Vector__XXX
SG_ DCDC3PowerLimitDueToHighSideCurr : 8|2@1+ (1,0) [0|3] "" Vector__XXX
SG_ DCDC3PowerLimitDueToLowSideCurr : 10|2@1+ (1,0) [0|3] "" Vector__XXX
SG_ DCDC3PowerLmtDTHghSideVoltageMin : 12|2@1+ (1,0) [0|3] "" Vector__XXX
SG_ DCDC3PowerLmtDTHghSideVoltageMax : 14|2@1+ (1,0) [0|3] "" Vector__XXX
SG_ DCDC3PowerLmtDTLowSideVoltageMin : 16|2@1+ (1,0) [0|3] "" Vector__XXX
SG_ DCDC3PowerLmtDTLowSideVoltageMax : 18|2@1+ (1,0) [0|3] "" Vector__XXX
SG_ DCDC3PowerLimitDTCnvTemperature : 20|2@1+ (1,0) [0|3] "" Vector__XXX
SG_ DCDC3PwrLmtDTElctrncFltrTemp : 22|2@1+ (1,0) [0|3] "" Vector__XXX
SG_ DCDC3PwrLmtDTPwrElctrncsTemp : 24|2@1+ (1,0) [0|3] "" Vector__XXX
SG_ DCDC3PwrLmtDTSLIBattryTermnlVltg : 26|2@1+ (1,0) [0|3] "" Vector__XXX
SG_ DCDC3PwrLmtDTSLIBattryTermnlCurr : 28|2@1+ (1,0) [0|3] "" Vector__XXX
SG_ DCDC3PwrLmtDTSLIBattryTermnlTemp : 30|2@1+ (1,0) [0|3] "" Vector__XXX
SG_ DCDC3PowerLimitDTUndefinedReason : 32|2@1+ (1,0) [0|3] "" Vector__XXX

BO_ 2364612606 DCDC3VC: 8 Vector__XXX
SG_ DCDC3LowSideVoltage : 0|16@1+ (0.01,0) [0|642.55] "V" Vector__XXX
SG_ DCDC3LowSideCurrent : 16|16@1+ (0.1,-3212.7) [-3212.7|3212.8] "A" Vector__XXX
SG_ DCDC3HighSideVoltage : 32|16@1+ (0.05,0) [0|3212.75] "V" Vector__XXX
SG_ DCDC3HighSideCurrent : 48|16@1+ (0.1,-3212.7) [-3212.7|3212.8] "A" Vector__XXX

BO_ 2364612862 DCDC3SBS: 8 Vector__XXX
SG_ DCDC3SLIBatteryTerminalVoltage : 0|16@1+ (0.01,0) [0|642.55] "V" Vector__XXX
SG_ DCDC3SLIBatteryTerminalCurrent : 16|16@1+ (0.1,-3212.7) [-3212.7|3212.8] "A" Vector__XXX
SG_ DCDC3SLIBattryTerminalTemp : 32|8@1+ (1,-40) [-40|210] "deg C" Vector__XXX

BO_ 2364613118 DCDC3S2: 8 Vector__XXX
SG_ DCDC3LowSidePower : 0|16@1+ (0.05,-1600) [-1600|1612.75] "kW" Vector__XXX
SG_ DCDC3HighSidePower : 16|16@1+ (0.05,-1600) [-1600|1612.75] "kW" Vector__XXX
SG_ DCDC3HghSideNegToChssGrndVoltage : 32|16@1+ (0.05,0) [0|3212.75] "V" Vector__XXX

BO_ 2364613374 DCDC4C: 8 Vector__XXX
SG_ DCDC4OperationalCommand : 0|4@1+ (1,0) [0|15] "" Vector__XXX
SG_ DCDC4LowSideVoltageBuckSetpoint : 8|16@1+ (0.01,0) [0|642.55] "V" Vector__XXX
SG_ DCDC4HghSideVoltageBoostSetpoint : 24|16@1+ (0.05,0) [0|3212.75] "V" Vector__XXX
SG_ DCDC4LowSdeVltgBuckDefltSetpnt : 40|16@1+ (0.01,0) [0|642.55] "V" Vector__XXX

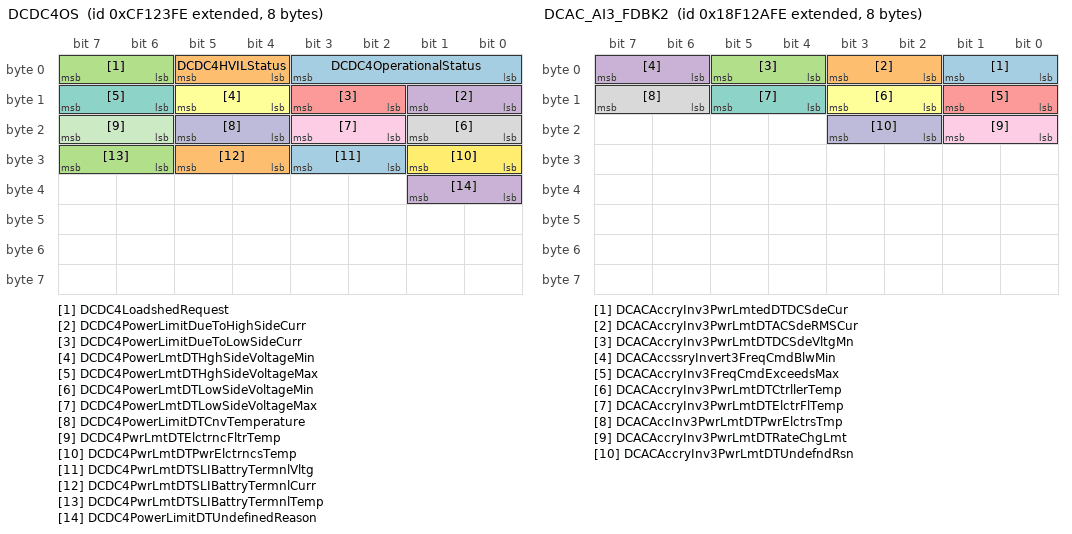
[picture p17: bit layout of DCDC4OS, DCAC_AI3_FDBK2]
BO_ 2364613630 DCDC4OS: 8 Vector__XXX
SG_ DCDC4OperationalStatus : 0|4@1+ (1,0) [0|15] "" Vector__XXX
SG_ DCDC4HVILStatus : 4|2@1+ (1,0) [0|3] "" Vector__XXX
SG_ DCDC4LoadshedRequest : 6|2@1+ (1,0) [0|3] "" Vector__XXX
SG_ DCDC4PowerLimitDueToHighSideCurr : 8|2@1+ (1,0) [0|3] "" Vector__XXX
SG_ DCDC4PowerLimitDueToLowSideCurr : 10|2@1+ (1,0) [0|3] "" Vector__XXX
SG_ DCDC4PowerLmtDTHghSideVoltageMin : 12|2@1+ (1,0) [0|3] "" Vector__XXX
SG_ DCDC4PowerLmtDTHghSideVoltageMax : 14|2@1+ (1,0) [0|3] "" Vector__XXX
SG_ DCDC4PowerLmtDTLowSideVoltageMin : 16|2@1+ (1,0) [0|3] "" Vector__XXX
SG_ DCDC4PowerLmtDTLowSideVoltageMax : 18|2@1+ (1,0) [0|3] "" Vector__XXX
SG_ DCDC4PowerLimitDTCnvTemperature : 20|2@1+ (1,0) [0|3] "" Vector__XXX
SG_ DCDC4PwrLmtDTElctrncFltrTemp : 22|2@1+ (1,0) [0|3] "" Vector__XXX
SG_ DCDC4PwrLmtDTPwrElctrncsTemp : 24|2@1+ (1,0) [0|3] "" Vector__XXX
SG_ DCDC4PwrLmtDTSLIBattryTermnlVltg : 26|2@1+ (1,0) [0|3] "" Vector__XXX
SG_ DCDC4PwrLmtDTSLIBattryTermnlCurr : 28|2@1+ (1,0) [0|3] "" Vector__XXX
SG_ DCDC4PwrLmtDTSLIBattryTermnlTemp : 30|2@1+ (1,0) [0|3] "" Vector__XXX
SG_ DCDC4PowerLimitDTUndefinedReason : 32|2@1+ (1,0) [0|3] "" Vector__XXX

BO_ 2364613886 DCDC4VC: 8 Vector__XXX
SG_ DCDC4LowSideVoltage : 0|16@1+ (0.01,0) [0|642.55] "V" Vector__XXX
SG_ DCDC4LowSideCurrent : 16|16@1+ (0.1,-3212.7) [-3212.7|3212.8] "A" Vector__XXX
SG_ DCDC4HighSideVoltage : 32|16@1+ (0.05,0) [0|3212.75] "V" Vector__XXX
SG_ DCDC4HighSideCurrent : 48|16@1+ (0.1,-3212.7) [-3212.7|3212.8] "A" Vector__XXX

BO_ 2364614142 DCDC4SBS: 8 Vector__XXX
SG_ DCDC4SLIBatteryTerminalVoltage : 0|16@1+ (0.01,0) [0|642.55] "V" Vector__XXX
SG_ DCDC4SLIBatteryTerminalCurrent : 16|16@1+ (0.1,-3212.7) [-3212.7|3212.8] "A" Vector__XXX
SG_ DCDC4SLIBattryTerminalTemp : 32|8@1+ (1,-40) [-40|210] "deg C" Vector__XXX

BO_ 2364614398 DCDC4S2: 8 Vector__XXX
SG_ DCDC4LowSidePower : 0|16@1+ (0.05,-1600) [-1600|1612.75] "kW" Vector__XXX
SG_ DCDC4HighSidePower : 16|16@1+ (0.05,-1600) [-1600|1612.75] "kW" Vector__XXX
SG_ DCDC4HghSideNegToChssGrndVoltage : 32|16@1+ (0.05,0) [0|3212.75] "V" Vector__XXX

BO_ 2364614654 SSI3: 8 Vector__XXX
SG_ GradeThresholdIndicator1 : 0|2@1+ (1,0) [0|3] "" Vector__XXX
SG_ GradeThresholdIndicator2 : 2|2@1+ (1,0) [0|3] "" Vector__XXX
SG_ GradeThresholdIndicator3 : 4|2@1+ (1,0) [0|3] "" Vector__XXX
SG_ GradeThresholdIndicator4 : 6|2@1+ (1,0) [0|3] "" Vector__XXX
SG_ GradeThresholdIndicator5 : 8|2@1+ (1,0) [0|3] "" Vector__XXX
SG_ GradeThresholdIndicator6 : 10|2@1+ (1,0) [0|3] "" Vector__XXX

BO_ 2364614910 DCAC_AI3_S2: 8 Vector__XXX
SG_ DCACAccssryInverter3DCSidePower : 0|16@1+ (0.0625,0) [0|4015.9375] "kW" Vector__XXX
SG_ DCACAccssryInvert3DCSideVoltage : 16|16@1+ (0.05,0) [0|3212.75] "V" Vector__XXX
SG_ DCACAccssryInverter3DCSideCurr : 32|16@1+ (0.0625,0) [0|4015.9375] "A" Vector__XXX
SG_ DCACAccryInv3DCSdeNegToChGrdVltg : 48|16@1+ (0.05,0) [0|3212.75] "V" Vector__XXX

BO_ 2364615166 DCAC_AI3_V: 8 Vector__XXX
SG_ DCACAccssryInvert3IgnitionVltg : 0|16@1+ (0.05,0) [0|3212.75] "V" Vector__XXX
SG_ DCACAccessoryInverter3SLIVoltage : 16|16@1+ (0.05,0) [0|3212.75] "V" Vector__XXX

BO_ 2565942014 DCAC_AI3_FDBK2: 8 Vector__XXX
SG_ DCACAccryInv3PwrLmtedDTDCSdeCur : 0|2@1+ (1,0) [0|3] "" Vector__XXX
SG_ DCACAccryInv3PwrLmtDTACSdeRMSCur : 2|2@1+ (1,0) [0|3] "" Vector__XXX
SG_ DCACAccryInv3PwrLmtDTDCSdeVltgMn : 4|2@1+ (1,0) [0|3] "" Vector__XXX
SG_ DCACAccssryInvert3FreqCmdBlwMin : 6|2@1+ (1,0) [0|3] "" Vector__XXX
SG_ DCACAccryInv3FreqCmdExceedsMax : 8|2@1+ (1,0) [0|3] "" Vector__XXX
SG_ DCACAccryInv3PwrLmtDTCtrllerTemp : 10|2@1+ (1,0) [0|3] "" Vector__XXX
SG_ DCACAccryInv3PwrLmtDTElctrFlTemp : 12|2@1+ (1,0) [0|3] "" Vector__XXX
SG_ DCACAccInv3PwrLmtDTPwrElctrsTmp : 14|2@1+ (1,0) [0|3] "" Vector__XXX
SG_ DCACAccryInv3PwrLmtDTRateChgLmt : 16|2@1+ (1,0) [0|3] "" Vector__XXX
SG_ DCACAccryInv3PwrLmtDTUndefndRsn : 18|2@1+ (1,0) [0|3] "" Vector__XXX

BO_ 2364615678 DCAC_AI4_S2: 8 Vector__XXX
SG_ DCACAccssryInverter4DCSidePower : 0|16@1+ (0.0625,0) [0|4015.9375] "kW" Vector__XXX
SG_ DCACAccssryInvert4DCSideVoltage : 16|16@1+ (0.05,0) [0|3212.75] "V" Vector__XXX
SG_ DCACAccssryInverter4DCSideCurr : 32|16@1+ (0.0625,0) [0|4015.9375] "A" Vector__XXX
SG_ DCACAccryInv4DCSdeNegToChGrdVltg : 48|16@1+ (0.05,0) [0|3212.75] "V" Vector__XXX

BO_ 2364615934 DCAC_AI4_V: 8 Vector__XXX
SG_ DCACAccssryInvert4IgnitionVltg : 0|16@1+ (0.05,0) [0|3212.75] "V" Vector__XXX
SG_ DCACAccessoryInverter4SLIVoltage : 16|16@1+ (0.05,0) [0|3212.75] "V" Vector__XXX

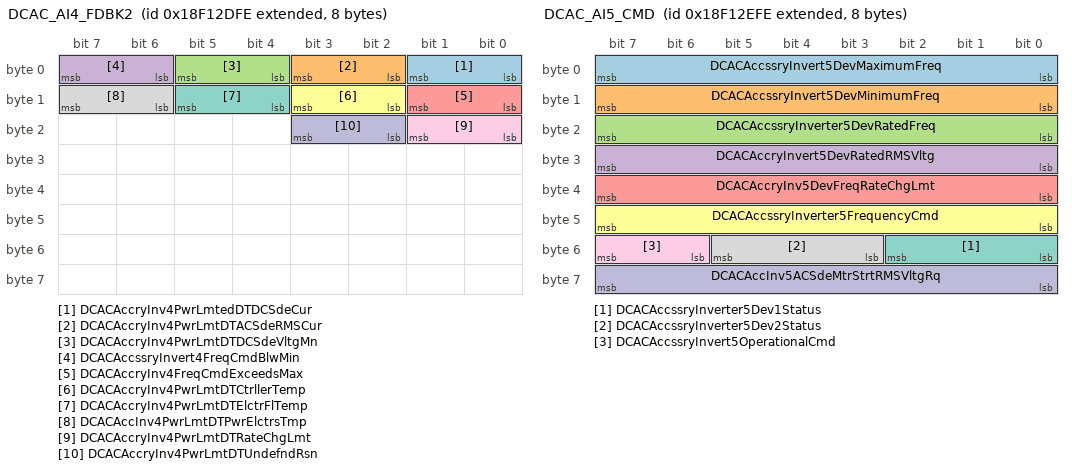
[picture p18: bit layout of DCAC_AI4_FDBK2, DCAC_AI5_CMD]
BO_ 2565942782 DCAC_AI4_FDBK2: 8 Vector__XXX
SG_ DCACAccryInv4PwrLmtedDTDCSdeCur : 0|2@1+ (1,0) [0|3] "" Vector__XXX
SG_ DCACAccryInv4PwrLmtDTACSdeRMSCur : 2|2@1+ (1,0) [0|3] "" Vector__XXX
SG_ DCACAccryInv4PwrLmtDTDCSdeVltgMn : 4|2@1+ (1,0) [0|3] "" Vector__XXX
SG_ DCACAccssryInvert4FreqCmdBlwMin : 6|2@1+ (1,0) [0|3] "" Vector__XXX
SG_ DCACAccryInv4FreqCmdExceedsMax : 8|2@1+ (1,0) [0|3] "" Vector__XXX
SG_ DCACAccryInv4PwrLmtDTCtrllerTemp : 10|2@1+ (1,0) [0|3] "" Vector__XXX
SG_ DCACAccryInv4PwrLmtDTElctrFlTemp : 12|2@1+ (1,0) [0|3] "" Vector__XXX
SG_ DCACAccInv4PwrLmtDTPwrElctrsTmp : 14|2@1+ (1,0) [0|3] "" Vector__XXX
SG_ DCACAccryInv4PwrLmtDTRateChgLmt : 16|2@1+ (1,0) [0|3] "" Vector__XXX
SG_ DCACAccryInv4PwrLmtDTUndefndRsn : 18|2@1+ (1,0) [0|3] "" Vector__XXX

BO_ 2565943038 DCAC_AI5_CMD: 8 Vector__XXX
SG_ DCACAccssryInvert5DevMaximumFreq : 0|8@1+ (1,0) [0|250] "Hz" Vector__XXX
SG_ DCACAccssryInvert5DevMinimumFreq : 8|8@1+ (1,0) [0|250] "Hz" Vector__XXX
SG_ DCACAccssryInverter5DevRatedFreq : 16|8@1+ (1,0) [0|250] "Hz" Vector__XXX
SG_ DCACAccryInvert5DevRatedRMSVltg : 24|8@1+ (2,0) [0|500] "Vrms" Vector__XXX
SG_ DCACAccryInv5DevFreqRateChgLmt : 32|8@1+ (2,0) [0|500] "Hz/s" Vector__XXX
SG_ DCACAccssryInverter5FrequencyCmd : 40|8@1+ (1,0) [0|250] "Hz" Vector__XXX
SG_ DCACAccssryInverter5Dev1Status : 48|3@1+ (1,0) [0|7] "" Vector__XXX
SG_ DCACAccssryInverter5Dev2Status : 51|3@1+ (1,0) [0|7] "" Vector__XXX
SG_ DCACAccssryInvert5OperationalCmd : 54|2@1+ (1,0) [0|3] "" Vector__XXX
SG_ DCACAccInv5ACSdeMtrStrtRMSVltgRq : 56|8@1+ (2,0) [0|500] "Vrms" Vector__XXX

BO_ 2565943294 DCAC_AI5_FDBK: 8 Vector__XXX
SG_ DCACAccessoryInverter5Frequency : 0|8@1+ (1,0) [0|250] "Hz" Vector__XXX
SG_ DCACAccssryInvert5ACSdeRMSVltg : 8|8@1+ (2,0) [0|500] "Vrms" Vector__XXX
SG_ DCACAccssryInverter5ACSidePower : 16|8@1+ (0.1,0) [0|25] "kW" Vector__XXX
SG_ DCACAccssryInvert5ACSideRMSCurr : 24|16@1+ (0.03125,0) [0|2007.96875] "Arms" Vector__XXX
SG_ DCACAccssryInvert5OpalStatus : 48|3@1+ (1,0) [0|7] "" Vector__XXX
SG_ DCACAccssryInvert5LoadshedRq : 51|2@1+ (1,0) [0|3] "" Vector__XXX
SG_ DCACAccessoryInverter5HVILStatus : 53|2@1+ (1,0) [0|3] "" Vector__XXX

BO_ 2364616958 DCAC_AI5_S2: 8 Vector__XXX
SG_ DCACAccssryInverter5DCSidePower : 0|16@1+ (0.0625,0) [0|4015.9375] "kW" Vector__XXX
SG_ DCACAccssryInvert5DCSideVoltage : 16|16@1+ (0.05,0) [0|3212.75] "V" Vector__XXX
SG_ DCACAccssryInverter5DCSideCurr : 32|16@1+ (0.0625,0) [0|4015.9375] "A" Vector__XXX
SG_ DCACAccryInv5DCSdeNegToChGrdVltg : 48|16@1+ (0.05,0) [0|3212.75] "V" Vector__XXX

BO_ 2364617214 DCAC_AI5_V: 8 Vector__XXX
SG_ DCACAccssryInvert5IgnitionVltg : 0|16@1+ (0.05,0) [0|3212.75] "V" Vector__XXX
SG_ DCACAccessoryInverter5SLIVoltage : 16|16@1+ (0.05,0) [0|3212.75] "V" Vector__XXX

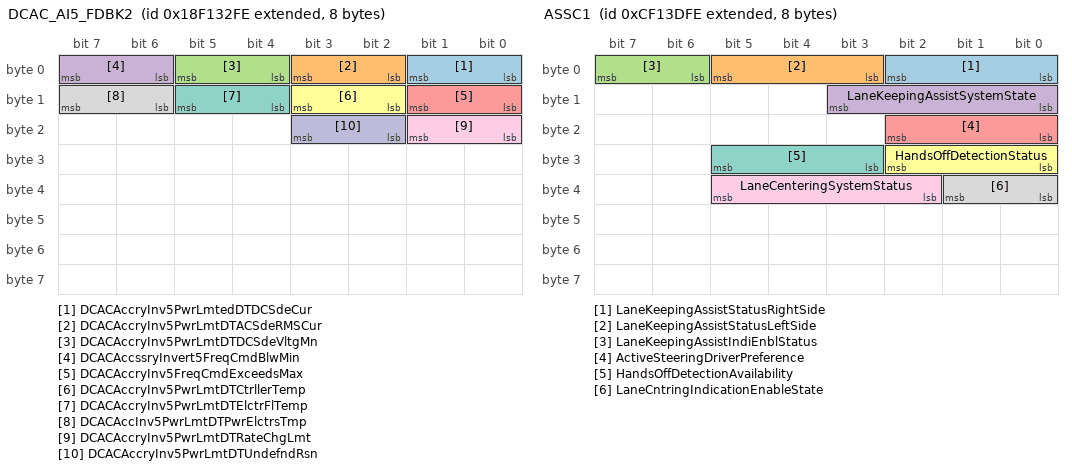
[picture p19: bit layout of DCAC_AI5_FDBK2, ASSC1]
BO_ 2565944062 DCAC_AI5_FDBK2: 8 Vector__XXX
SG_ DCACAccryInv5PwrLmtedDTDCSdeCur : 0|2@1+ (1,0) [0|3] "" Vector__XXX
SG_ DCACAccryInv5PwrLmtDTACSdeRMSCur : 2|2@1+ (1,0) [0|3] "" Vector__XXX
SG_ DCACAccryInv5PwrLmtDTDCSdeVltgMn : 4|2@1+ (1,0) [0|3] "" Vector__XXX
SG_ DCACAccssryInvert5FreqCmdBlwMin : 6|2@1+ (1,0) [0|3] "" Vector__XXX
SG_ DCACAccryInv5FreqCmdExceedsMax : 8|2@1+ (1,0) [0|3] "" Vector__XXX
SG_ DCACAccryInv5PwrLmtDTCtrllerTemp : 10|2@1+ (1,0) [0|3] "" Vector__XXX
SG_ DCACAccryInv5PwrLmtDTElctrFlTemp : 12|2@1+ (1,0) [0|3] "" Vector__XXX
SG_ DCACAccInv5PwrLmtDTPwrElctrsTmp : 14|2@1+ (1,0) [0|3] "" Vector__XXX
SG_ DCACAccryInv5PwrLmtDTRateChgLmt : 16|2@1+ (1,0) [0|3] "" Vector__XXX
SG_ DCACAccryInv5PwrLmtDTUndefndRsn : 18|2@1+ (1,0) [0|3] "" Vector__XXX

BO_ 2364617726 EPCVDC1: 8 Vector__XXX
SG_ EnginePreChmbrFuelValve1Duration : 0|16@1+ (2,0) [0|128510] "us" Vector__XXX
SG_ EnginePreChmbrFuelValve2Duration : 16|16@1+ (2,0) [0|128510] "us" Vector__XXX
SG_ EnginePreChmbrFuelValve3Duration : 32|16@1+ (2,0) [0|128510] "us" Vector__XXX
SG_ EnginePreChmbrFuelValve4Duration : 48|16@1+ (2,0) [0|128510] "us" Vector__XXX

BO_ 2364617982 EPCVDC2: 8 Vector__XXX
SG_ EnginePreChmbrFuelValve5Duration : 0|16@1+ (2,0) [0|128510] "us" Vector__XXX
SG_ EnginePreChmbrFuelValve6Duration : 16|16@1+ (2,0) [0|128510] "us" Vector__XXX
SG_ EnginePreChmbrFuelValve7Duration : 32|16@1+ (2,0) [0|128510] "us" Vector__XXX
SG_ EnginePreChmbrFuelValve8Duration : 48|16@1+ (2,0) [0|128510] "us" Vector__XXX

BO_ 2364618238 EPCVDC3: 8 Vector__XXX
SG_ EnginePreChmbrFuelValve9Duration : 0|16@1+ (2,0) [0|128510] "us" Vector__XXX
SG_ EnginePreChmbrFuelValve10Duratn : 16|16@1+ (2,0) [0|128510] "us" Vector__XXX
SG_ EnginePreChmbrFuelValve11Duratn : 32|16@1+ (2,0) [0|128510] "us" Vector__XXX
SG_ EnginePreChmbrFuelValve12Duratn : 48|16@1+ (2,0) [0|128510] "us" Vector__XXX

BO_ 2364618494 EPCVDC4: 8 Vector__XXX
SG_ EnginePreChmbrFuelValve13Duratn : 0|16@1+ (2,0) [0|128510] "us" Vector__XXX
SG_ EnginePreChmbrFuelValve14Duratn : 16|16@1+ (2,0) [0|128510] "us" Vector__XXX
SG_ EnginePreChmbrFuelValve15Duratn : 32|16@1+ (2,0) [0|128510] "us" Vector__XXX
SG_ EnginePreChmbrFuelValve16Duratn : 48|16@1+ (2,0) [0|128510] "us" Vector__XXX

BO_ 2364618750 EPCVDC5: 8 Vector__XXX
SG_ EnginePreChmbrFuelValve17Duratn : 0|16@1+ (2,0) [0|128510] "us" Vector__XXX
SG_ EnginePreChmbrFuelValve18Duratn : 16|16@1+ (2,0) [0|128510] "us" Vector__XXX
SG_ EnginePreChmbrFuelValve19Duratn : 32|16@1+ (2,0) [0|128510] "us" Vector__XXX
SG_ EnginePreChmbrFuelValve20Duratn : 48|16@1+ (2,0) [0|128510] "us" Vector__XXX

BO_ 2364619006 EPCSOAC1: 8 Vector__XXX
SG_ EngPreChmbrFuelValve1StartActCmd : 0|16@1+ (0.0078125,-400) [-400|101.99] "deg" Vector__XXX
SG_ EngPreChmbrFuelValve2StartActCmd : 16|16@1+ (0.0078125,-400) [-400|101.99] "deg" Vector__XXX
SG_ EngPreChmbrFuelValve3StartActCmd : 32|16@1+ (0.0078125,-400) [-400|101.99] "deg" Vector__XXX
SG_ EngPreChmbrFuelValve4StartActCmd : 48|16@1+ (0.0078125,-400) [-400|101.99] "deg" Vector__XXX

BO_ 2364619262 EPCSOAC2: 8 Vector__XXX
SG_ EngPreChmbrFuelValve5StartActCmd : 0|16@1+ (0.0078125,-400) [-400|101.99] "deg" Vector__XXX
SG_ EngPreChmbrFuelValve6StartActCmd : 16|16@1+ (0.0078125,-400) [-400|101.99] "deg" Vector__XXX
SG_ EngPreChmbrFuelValve7StartActCmd : 32|16@1+ (0.0078125,-400) [-400|101.99] "deg" Vector__XXX
SG_ EngPreChmbrFuelValve8StartActCmd : 48|16@1+ (0.0078125,-400) [-400|101.99] "deg" Vector__XXX

BO_ 2364619518 EPCSOAC3: 8 Vector__XXX
SG_ EngPreChmbrFuelValve9StartActCmd : 0|16@1+ (0.0078125,-400) [-400|101.99] "deg" Vector__XXX
SG_ EngPreChmbrFuelValve10StrtActCmd : 16|16@1+ (0.0078125,-400) [-400|101.99] "deg" Vector__XXX
SG_ EngPreChmbrFuelValve11StrtActCmd : 32|16@1+ (0.0078125,-400) [-400|101.99] "deg" Vector__XXX
SG_ EngPreChmbrFuelValve12StrtActCmd : 48|16@1+ (0.0078125,-400) [-400|101.99] "deg" Vector__XXX

BO_ 2364619774 EPCSOAC4: 8 Vector__XXX
SG_ EngPreChmbrFuelValve13StrtActCmd : 0|16@1+ (0.0078125,-400) [-400|101.99] "deg" Vector__XXX
SG_ EngPreChmbrFuelValve14StrtActCmd : 16|16@1+ (0.0078125,-400) [-400|101.99] "deg" Vector__XXX
SG_ EngPreChmbrFuelValve15StrtActCmd : 32|16@1+ (0.0078125,-400) [-400|101.99] "deg" Vector__XXX
SG_ EngPreChmbrFuelValve16StrtActCmd : 48|16@1+ (0.0078125,-400) [-400|101.99] "deg" Vector__XXX

BO_ 2364620030 EPCSOAC5: 8 Vector__XXX
SG_ EngPreChmbrFuelValve17StrtActCmd : 0|16@1+ (0.0078125,-400) [-400|101.99] "deg" Vector__XXX
SG_ EngPreChmbrFuelValve18StrtActCmd : 16|16@1+ (0.0078125,-400) [-400|101.99] "deg" Vector__XXX
SG_ EngPreChmbrFuelValve19StrtActCmd : 32|16@1+ (0.0078125,-400) [-400|101.99] "deg" Vector__XXX
SG_ EngPreChmbrFuelValve20StrtActCmd : 48|16@1+ (0.0078125,-400) [-400|101.99] "deg" Vector__XXX

BO_ 2364620286 ASSC1: 8 Vector__XXX
SG_ LaneKeepingAssistStatusRightSide : 0|3@1+ (1,0) [0|7] "" Vector__XXX
SG_ LaneKeepingAssistStatusLeftSide : 3|3@1+ (1,0) [0|7] "" Vector__XXX
SG_ LaneKeepingAssistIndiEnblStatus : 6|2@1+ (1,0) [0|3] "" Vector__XXX
SG_ LaneKeepingAssistSystemState : 8|4@1+ (1,0) [0|15] "" Vector__XXX
SG_ ActiveSteeringDriverPreference : 16|3@1+ (1,0) [0|7] "" Vector__XXX
SG_ HandsOffDetectionStatus : 24|3@1+ (1,0) [0|7] "" Vector__XXX
SG_ HandsOffDetectionAvailability : 27|3@1+ (1,0) [0|7] "" Vector__XXX
SG_ LaneCntringIndicationEnableState : 32|2@1+ (1,0) [0|3] "" Vector__XXX
SG_ LaneCenteringSystemStatus : 34|4@1+ (1,0) [0|15] "" Vector__XXX

BO_ 2565947134 SFHYC: 0 Vector__XXX

BO_ 2565947390 PFHYC: 0 Vector__XXX

BO_ 2364621054 SIAAC: 8 Vector__XXX
SG_ StationaryInvertAvrgACRMSVoltage : 0|16@1+ (1,0) [0|64255] "V" Vector__XXX
SG_ StionaryInvAvrgLineNtrlACRMSVltg : 16|16@1+ (1,0) [0|64255] "V" Vector__XXX
SG_ StationaryInverterAvrgACFreq : 32|16@1+ (0.0078125,0) [0|501.9921875] "Hz" Vector__XXX
SG_ StationaryInverterAvrgACRMSCurr : 48|16@1+ (1,0) [0|64255] "A" Vector__XXX

BO_ 2364621310 SITACR: 8 Vector__XXX
SG_ StationaryInvertTotalReactivePwr : 0|32@1+ (1,-2000000000) [-2000000000|2211081215] "VAr" Vector__XXX
SG_ StationaryInvertOverallPwrFactor : 32|16@1+ (6.103515625E-005,-1) [-1|2.921814] "" Vector__XXX
SG_ StationaryInvOverllPwrFctrLaggng : 48|2@1+ (1,0) [0|3] "" Vector__XXX

BO_ 2364621566 SITACP: 8 Vector__XXX
SG_ StationaryInverterTotalRealPower : 0|32@1+ (1,-2000000000) [-2000000000|2211081215] "W" Vector__XXX
SG_ StationaryInvertTotalApparentPwr : 32|32@1+ (1,-2000000000) [-2000000000|2211081215] "VA" Vector__XXX

BO_ 2364621822 SIC: 8 Vector__XXX
SG_ StionaryInvNotRdyToAutoParaStat : 0|2@1+ (1,0) [0|3] "" Vector__XXX
SG_ StationaryInvertAuxShtdwnSwitch : 2|2@1+ (1,0) [0|3] "" Vector__XXX

BO_ 2364622078 SIBSC: 8 Vector__XXX
SG_ StationaryInverterToBusDeadBus : 0|2@1+ (1,0) [0|3] "" Vector__XXX
SG_ StationaryInvertToBusPhaseMatch : 2|2@1+ (1,0) [0|3] "" Vector__XXX
SG_ StationaryInverterToBusFreqMatch : 4|2@1+ (1,0) [0|3] "" Vector__XXX
SG_ StationaryInvertToBusVltgMatch : 6|2@1+ (1,0) [0|3] "" Vector__XXX
SG_ StationaryInverterToBusInSync : 8|2@1+ (1,0) [0|3] "" Vector__XXX
SG_ StationaryInvertToBusACPhaseDiff : 16|16@1+ (0.0078125,-200) [-200|301.99] "deg" Vector__XXX

BO_ 2364622334 ECCP1: 8 Vector__XXX
SG_ EngineCylinder1Timing1Pressure : 0|16@1+ (0.0009765625,0) [0|62.74902344] "MPa" Vector__XXX
SG_ EngineCylinder1Timing2Pressure : 16|16@1+ (0.0009765625,0) [0|62.74902344] "MPa" Vector__XXX
SG_ EngineCylinder1Timing3Pressure : 32|16@1+ (0.0009765625,0) [0|62.74902344] "MPa" Vector__XXX
SG_ EngineCylinder1Timing4Pressure : 48|16@1+ (0.0009765625,0) [0|62.74902344] "MPa" Vector__XXX

BO_ 2364622590 ECCP2: 8 Vector__XXX
SG_ EngineCylinder2Timing1Pressure : 0|16@1+ (0.0009765625,0) [0|62.74902344] "MPa" Vector__XXX
SG_ EngineCylinder2Timing2Pressure : 16|16@1+ (0.0009765625,0) [0|62.74902344] "MPa" Vector__XXX
SG_ EngineCylinder2Timing3Pressure : 32|16@1+ (0.0009765625,0) [0|62.74902344] "MPa" Vector__XXX
SG_ EngineCylinder2Timing4Pressure : 48|16@1+ (0.0009765625,0) [0|62.74902344] "MPa" Vector__XXX

BO_ 2364622846 ECCP3: 8 Vector__XXX
SG_ EngineCylinder3Timing1Pressure : 0|16@1+ (0.0009765625,0) [0|62.74902344] "MPa" Vector__XXX
SG_ EngineCylinder3Timing2Pressure : 16|16@1+ (0.0009765625,0) [0|62.74902344] "MPa" Vector__XXX
SG_ EngineCylinder3Timing3Pressure : 32|16@1+ (0.0009765625,0) [0|62.74902344] "MPa" Vector__XXX
SG_ EngineCylinder3Timing4Pressure : 48|16@1+ (0.0009765625,0) [0|62.74902344] "MPa" Vector__XXX

BO_ 2364623102 ECCP4: 8 Vector__XXX
SG_ EngineCylinder4Timing1Pressure : 0|16@1+ (0.0009765625,0) [0|62.74902344] "MPa" Vector__XXX
SG_ EngineCylinder4Timing2Pressure : 16|16@1+ (0.0009765625,0) [0|62.74902344] "MPa" Vector__XXX
SG_ EngineCylinder4Timing3Pressure : 32|16@1+ (0.0009765625,0) [0|62.74902344] "MPa" Vector__XXX
SG_ EngineCylinder4Timing4Pressure : 48|16@1+ (0.0009765625,0) [0|62.74902344] "MPa" Vector__XXX

BO_ 2364623358 ECCP5: 8 Vector__XXX
SG_ EngineCylinder5Timing1Pressure : 0|16@1+ (0.0009765625,0) [0|62.74902344] "MPa" Vector__XXX
SG_ EngineCylinder5Timing2Pressure : 16|16@1+ (0.0009765625,0) [0|62.74902344] "MPa" Vector__XXX
SG_ EngineCylinder5Timing3Pressure : 32|16@1+ (0.0009765625,0) [0|62.74902344] "MPa" Vector__XXX
SG_ EngineCylinder5Timing4Pressure : 48|16@1+ (0.0009765625,0) [0|62.74902344] "MPa" Vector__XXX

BO_ 2364623614 ECCP6: 8 Vector__XXX
SG_ EngineCylinder6Timing1Pressure : 0|16@1+ (0.0009765625,0) [0|62.74902344] "MPa" Vector__XXX
SG_ EngineCylinder6Timing2Pressure : 16|16@1+ (0.0009765625,0) [0|62.74902344] "MPa" Vector__XXX
SG_ EngineCylinder6Timing3Pressure : 32|16@1+ (0.0009765625,0) [0|62.74902344] "MPa" Vector__XXX
SG_ EngineCylinder6Timing4Pressure : 48|16@1+ (0.0009765625,0) [0|62.74902344] "MPa" Vector__XXX

BO_ 2364623870 ECCP7: 8 Vector__XXX
SG_ EngineCylinder7Timing1Pressure : 0|16@1+ (0.0009765625,0) [0|62.74902344] "MPa" Vector__XXX
SG_ EngineCylinder7Timing2Pressure : 16|16@1+ (0.0009765625,0) [0|62.74902344] "MPa" Vector__XXX
SG_ EngineCylinder7Timing3Pressure : 32|16@1+ (0.0009765625,0) [0|62.74902344] "MPa" Vector__XXX
SG_ EngineCylinder7Timing4Pressure : 48|16@1+ (0.0009765625,0) [0|62.74902344] "MPa" Vector__XXX

BO_ 2364624126 ECCP8: 8 Vector__XXX
SG_ EngineCylinder8Timing1Pressure : 0|16@1+ (0.0009765625,0) [0|62.74902344] "MPa" Vector__XXX
SG_ EngineCylinder8Timing2Pressure : 16|16@1+ (0.0009765625,0) [0|62.74902344] "MPa" Vector__XXX
SG_ EngineCylinder8Timing3Pressure : 32|16@1+ (0.0009765625,0) [0|62.74902344] "MPa" Vector__XXX
SG_ EngineCylinder8Timing4Pressure : 48|16@1+ (0.0009765625,0) [0|62.74902344] "MPa" Vector__XXX

BO_ 2364624382 ECCP9: 8 Vector__XXX
SG_ EngineCylinder9Timing1Pressure : 0|16@1+ (0.0009765625,0) [0|62.74902344] "MPa" Vector__XXX
SG_ EngineCylinder9Timing2Pressure : 16|16@1+ (0.0009765625,0) [0|62.74902344] "MPa" Vector__XXX
SG_ EngineCylinder9Timing3Pressure : 32|16@1+ (0.0009765625,0) [0|62.74902344] "MPa" Vector__XXX
SG_ EngineCylinder9Timing4Pressure : 48|16@1+ (0.0009765625,0) [0|62.74902344] "MPa" Vector__XXX

BO_ 2364624638 ECCP10: 8 Vector__XXX
SG_ EngineCylinder10Timing1Pressure : 0|16@1+ (0.0009765625,0) [0|62.74902344] "MPa" Vector__XXX
SG_ EngineCylinder10Timing2Pressure : 16|16@1+ (0.0009765625,0) [0|62.74902344] "MPa" Vector__XXX
SG_ EngineCylinder10Timing3Pressure : 32|16@1+ (0.0009765625,0) [0|62.74902344] "MPa" Vector__XXX
SG_ EngineCylinder10Timing4Pressure : 48|16@1+ (0.0009765625,0) [0|62.74902344] "MPa" Vector__XXX

CM_ BO_ 2364542462 "Land Leveling System Operational Information";
CM_ BO_ 2565869310 "Aftertreatment 1 Intake Gas 1";
CM_ BO_ 2565869566 "Aftertreatment 1 Outlet Gas 1";
CM_ BO_ 2565869822 "Aftertreatment 2 Intake Gas 1";
CM_ BO_ 2565870078 "Aftertreatment 2 Outlet Gas 1";
CM_ BO_ 2565870334 "Fifth Wheel Smart Systems 1";
CM_ BO_ 2364543998 "Slope Sensor Information";
CM_ BO_ 2364544254 "Blade Information";
CM_ BO_ 2364544510 "Requested Generator Total AC Reactive Power";
CM_ BO_ 2364544766 "Cylinder Combustion Status";
CM_ BO_ 2364545022 "Engine Knock Level #1";
CM_ BO_ 2364545278 "Engine Knock Level #2";
CM_ BO_ 2364545534 "Engine Knock Level #3";
CM_ BO_ 2431654654 "Engine Throttle / Fuel Actuator Control Command";
CM_ BO_ 2364546302 "Requested Generator Average Basic AC Quantities";
CM_ BO_ 2565873150 "Steering Angle Sensor Information";
CM_ BO_ 2364546814 "Generator Control 2";
CM_ BO_ 2565874174 "Engine Speed Sensor Information 1";
CM_ BO_ 2565874430 "ISO 11783-7: Machine Selected Speed";
CM_ BO_ 2364548094 "Aftertreatment 1 SCR Dosing System Information 1";
CM_ BO_ 2364548350 "Aftertreatment 1 SCR Dosing System Requests 1";
CM_ BO_ 2364548606 "Aftertreatment 1 SCR Ammonia Information";
CM_ BO_ 2364548862 "Aftertreatment 2 SCR Dosing System Information 1";
CM_ BO_ 2364549118 "Aftertreatment 2 SCR Dosing System Requests 1";
CM_ BO_ 2364549374 "Aftertreatment 2 SCR Ammonia Information";
CM_ BO_ 2364549630 "Slope Sensor Information 2";
CM_ BO_ 2364549886 "Angular Rate Information";
CM_ BO_ 2163223550 "Crash Notification";
CM_ BO_ 2297441534 "Magnet Status Information 2";
CM_ BO_ 2297441790 "Acceleration Sensor";
CM_ BO_ 2565877502 "Engine Turbocharger Control";
CM_ BO_ 2364551166 "Advanced Emergency Braking System 1";
CM_ BO_ 2364551422 "Wireless Status";
CM_ BO_ 2230333950 "Wand Sensor";
CM_ BO_ 2230334206 "Linear Displacement Sensor";
CM_ BO_ 2431661054 "Aftertreatment 1 SCR Ammonia Information 2";
CM_ BO_ 2431661310 "Aftertreatment 2 SCR Ammonia Information 2";
CM_ BO_ 2364552958 "High Voltage Energy Storage System Status 2";
CM_ BO_ 2364553214 "Engine Turbocharger Blowoff Actuator 1";
CM_ BO_ 2364553470 "Engine Torque / Fuel Request";
CM_ BO_ 2364553726 "Engine Air System Information";
CM_ BO_ 2364553982 "Engine Cylinder 1 Combustion Information";
CM_ BO_ 2364554238 "Engine Cylinder 2 Combustion Information";
CM_ BO_ 2364554494 "Engine Cylinder 3 Combustion Information";
CM_ BO_ 2364554750 "Engine Cylinder 4 Combustion Information";
CM_ BO_ 2364555006 "Engine Cylinder 5 Combustion Information";
CM_ BO_ 2364555262 "Engine Cylinder 6 Combustion Information";
CM_ BO_ 2364555518 "Engine Cylinder 7 Combustion Information";
CM_ BO_ 2364555774 "Engine Cylinder 8 Combustion Information";
CM_ BO_ 2364556030 "Engine Cylinder 9 Combustion Information";
CM_ BO_ 2364556286 "Engine Cylinder 10 Combustion Information";
CM_ BO_ 2364556542 "Engine Cylinder 11 Combustion Information";
CM_ BO_ 2364556798 "Engine Cylinder 12 Combustion Information";
CM_ BO_ 2364557054 "Engine Cylinder 13 Combustion Information";
CM_ BO_ 2364557310 "Engine Cylinder 14 Combustion Information";
CM_ BO_ 2364557566 "Engine Cylinder 15 Combustion Information";
CM_ BO_ 2364557822 "Engine Cylinder 16 Combustion Information";
CM_ BO_ 2364558078 "Engine Cylinder 17 Combustion Information";
CM_ BO_ 2364558334 "Engine Cylinder 18 Combustion Information";
CM_ BO_ 2364558590 "Engine Cylinder 19 Combustion Information";
CM_ BO_ 2364558846 "Engine Cylinder 20 Combustion Information";
CM_ BO_ 2498776830 "Engine Cylinder 1 Combustion Average Information";
CM_ BO_ 2498777086 "Engine Cylinder 2 Combustion Average Information";
CM_ BO_ 2498777342 "Engine Cylinder 3 Combustion Average Information";
CM_ BO_ 2498777598 "Engine Cylinder 4 Combustion Average Information";
CM_ BO_ 2498777854 "Engine Cylinder 5 Combustion Average Information";
CM_ BO_ 2498778110 "Engine Cylinder 6 Combustion Average Information";
CM_ BO_ 2498778366 "Engine Cylinder 7 Combustion Average Information";
CM_ BO_ 2498778622 "Engine Cylinder 8 Combustion Average Information";
CM_ BO_ 2498778878 "Engine Cylinder 9 Combustion Average Information";
CM_ BO_ 2498779134 "Engine Cylinder 10 Combustion Average Information";
CM_ BO_ 2498779390 "Engine Cylinder 11 Combustion Average Information";
CM_ BO_ 2498779646 "Engine Cylinder 12 Combustion Average Information";
CM_ BO_ 2498779902 "Engine Cylinder 13 Combustion Average Information";
CM_ BO_ 2498780158 "Engine Cylinder 14 Combustion Average Information";
CM_ BO_ 2498780414 "Engine Cylinder 15 Combustion Average Information";
CM_ BO_ 2498780670 "Engine Cylinder 16 Combustion Average Information";
CM_ BO_ 2498780926 "Engine Cylinder 17 Combustion Average Information";
CM_ BO_ 2498781182 "Engine Cylinder 18 Combustion Average Information";
CM_ BO_ 2498781438 "Engine Cylinder 19 Combustion Average Information";
CM_ BO_ 2498781694 "Engine Cylinder 20 Combustion Average Information";
CM_ BO_ 2297455358 "Electronic Transmission Controller #12";
CM_ BO_ 2364564478 "Fuel Information 5 (Gaseous)";
CM_ BO_ 2364564734 "Engine Gaseous Fuel Valve Duration Command 1";
CM_ BO_ 2364564990 "Engine Gaseous Fuel Valve Duration Command 2";
CM_ BO_ 2364565246 "Engine Gaseous Fuel Valve Duration Command 3";
CM_ BO_ 2364565502 "Engine Gaseous Fuel Valve Duration Command 4";
CM_ BO_ 2364565758 "Engine Gaseous Fuel Valve Duration Command 5";
CM_ BO_ 2364566014 "Engine Gaseous Fuel Valve Start of Actuation Command 1";
CM_ BO_ 2364566270 "Engine Gaseous Fuel Valve Start of Actuation Command 2";
CM_ BO_ 2364566526 "Engine Gaseous Fuel Valve Start of Actuation Command 3";
CM_ BO_ 2364566782 "Engine Gaseous Fuel Valve Start of Actuation Command 4";
CM_ BO_ 2364567038 "Engine Gaseous Fuel Valve Start of Actuation Command 5";
CM_ BO_ 2364567294 "Fuel Pump Actuator Control Command";
CM_ BO_ 2364575998 "High Voltage Energy Storage System Data 1";
CM_ BO_ 2364576254 "High Voltage Energy Storage System Data 2";
CM_ BO_ 2364576510 "High Voltage Energy Storage System Data 3";
CM_ BO_ 2364576766 "High Voltage Energy Storage System Data 4";
CM_ BO_ 2364577022 "High Voltage Energy Storage System Data 5";
CM_ BO_ 2364577278 "High Voltage Energy Storage System 1 Data 6";
CM_ BO_ 2364577534 "High Voltage Energy Storage System Status 1";
CM_ BO_ 2364580094 "High Voltage Energy Storage System Data 7";
CM_ BO_ 2364590334 "DC/AC Accessory Inverter 1 Status 2";
CM_ BO_ 2364590590 "DC/AC Accessory Inverter 1 Voltage";
CM_ BO_ 2565917438 "DC/AC Accessory Inverter 1 Feedback 2";
CM_ BO_ 2364591102 "DC/AC Accessory Inverter 2 Status 2";
CM_ BO_ 2364591358 "DC/AC Accessory Inverter 2 Voltage";
CM_ BO_ 2565918206 "DC/AC Accessory Inverter 2 Feedback 2";
CM_ BO_ 2364592382 "Engine Cylinder Combustion Request";
CM_ BO_ 2364592638 "Engine Cylinder Head Bypass Actuator 1";
CM_ BO_ 2364592894 "Engine Electronic Controller 18";
CM_ BO_ 2364593150 "Predictive Cruise Control 1";
CM_ BO_ 2565920510 "DC/AC Accessory Inverter 1 Command";
CM_ BO_ 2565920766 "DC/AC Accessory Inverter 1 Feedback";
CM_ BO_ 2565921534 "DC/AC Accessory Inverter 2 Command";
CM_ BO_ 2565921790 "DC/AC Accessory Inverter 2 Feedback";
CM_ BO_ 2565922558 "DC/AC Accessory Inverter 3 Command";
CM_ BO_ 2565922814 "DC/AC Accessory Inverter 3 Feedback";
CM_ BO_ 2565923582 "DC/AC Accessory Inverter 4 Command";
CM_ BO_ 2565923838 "DC/AC Accessory Inverter 4 Feedback";
CM_ BO_ 2565924094 "ISO 11783-7: Heartbeat message";
CM_ BO_ 2364597758 "Engine Ignition Timing Offset 1";
CM_ BO_ 2364598014 "Engine Ignition Timing Offset 2";
CM_ BO_ 2364598270 "Engine Ignition Timing Offset 3";
CM_ BO_ 2364598526 "Engine Throttle / Fuel Actuator Control Command 2";
CM_ BO_ 2565925374 "Aftertreatment 1 Intake Gas 3";
CM_ BO_ 2565925630 "Aftertreatment 1 Outlet Gas 3";
CM_ BO_ 2565925886 "Aftertreatment 2 Intake Gas Sensor 2";
CM_ BO_ 2565926142 "Aftertreatment 2 Outlet Gas Sensor 2";
CM_ BO_ 2431708670 "Engine Start Control";
CM_ BO_ 2431710718 "Engine Start Arbitrator";
CM_ BO_ 2364602878 "Engine Valve Controller";
CM_ BO_ 2364603134 "Electronic Transmission Controller 13";
CM_ BO_ 2364603390 "Aftertreatment 1 SCR Dosing System Requests 3";
CM_ BO_ 2364603646 "Aftertreatment 2 SCR Dosing System Requests 3";
CM_ BO_ 2364603902 "Aftertreatment 1 SCR Dosing System Information 4";
CM_ BO_ 2364604158 "Aftertreatment 2 SCR Dosing System Information 4";
CM_ BO_ 2364604414 "ISO 11783-7: Secondary or Front Hitch Roll and Pitch";
CM_ BO_ 2364604670 "ISO 11783-7: Secondary or Front Hitch Roll and Pitch Command";
CM_ BO_ 2364604926 "ISO 11783-7: Primary or Rear Hitch Roll and Pitch";
CM_ BO_ 2364605182 "ISO 11783-7: Primary or Rear Hitch Roll and Pitch Command";
CM_ BO_ 2364605438 "Generator Trip Energy";
CM_ BO_ 2565932286 "Engine Speed Sensor Information 2";
CM_ BO_ 2364605950 "Hydraulic Pressure Displacement";
CM_ BO_ 2565932798 "Well Stimulation Pump System 1";
CM_ BO_ 2565933054 "Well Stimulation Pump System 2";
CM_ BO_ 2364606718 "High Voltage Energy Storage System Module Status 1";
CM_ BO_ 2364606974 "High Voltage Energy Storage System Thermal Management System Status 1";
CM_ BO_ 2364607230 "High Voltage Energy Storage System Data 8";
CM_ BO_ 2364607486 "High Voltage Energy Storage System Data 9";
CM_ BO_ 2364607742 "High Voltage Energy Storage System Data 10";
CM_ BO_ 2565934590 "Fuel Information 6 (Gaseous)";
CM_ BO_ 2498825982 "Dump Truck Body Information";
CM_ BO_ 2364608510 "Engine Operating Information 2";
CM_ BO_ 2297499902 "Brakes 2";
CM_ BO_ 2431717886 "Gaseous Fuel Pressure 3";
CM_ BO_ 2364609278 "DC/DC Converter 1 Control";
CM_ BO_ 2364609534 "DC/DC Converter 1 Operating Status";
CM_ BO_ 2364609790 "DC/DC Converter 1 Voltage and Current";
CM_ BO_ 2364610046 "DC/DC Converter 1 SLI Battery Status";
CM_ BO_ 2431719166 "Well Stimulation Pump System 3";
CM_ BO_ 2364610558 "DC/DC Converter 1 Status 2";
CM_ BO_ 2364610814 "DC/DC Converter 2 Control";
CM_ BO_ 2364611070 "DC/DC Converter 2 Operating Status";
CM_ BO_ 2364611326 "DC/DC Converter 2 Voltage and Current";
CM_ BO_ 2364611582 "DC/DC Converter 2 SLI Battery Status";
CM_ BO_ 2364611838 "DC/DC Converter 2 Status 2";
CM_ BO_ 2364612094 "DC/DC Converter 3 Control";
CM_ BO_ 2364612350 "DC/DC Converter 3 Operating Status";
CM_ BO_ 2364612606 "DC/DC Converter 3 Voltage and Current";
CM_ BO_ 2364612862 "DC/DC Converter 3 SLI Battery Status";
CM_ BO_ 2364613118 "DC/DC Converter 3 Status 2";
CM_ BO_ 2364613374 "DC/DC Converter 4 Control";
CM_ BO_ 2364613630 "DC/DC Converter 4 Operating Status";
CM_ BO_ 2364613886 "DC/DC Converter 4 Voltage and Current";
CM_ BO_ 2364614142 "DC/DC Converter 4 SLI Battery Status";
CM_ BO_ 2364614398 "DC/DC Converter 4 Status 2";
CM_ BO_ 2364614654 "Slope Sensor Information 3";
CM_ BO_ 2364614910 "DC/AC Accessory Inverter 3 Status 2";
CM_ BO_ 2364615166 "DC/AC Accessory Inverter 3 Voltage";
CM_ BO_ 2565942014 "DC/AC Accessory Inverter 3 Feedback 2";
CM_ BO_ 2364615678 "DC/AC Accessory Inverter 4 Status 2";
CM_ BO_ 2364615934 "DC/AC Accessory Inverter 4 Voltage";
CM_ BO_ 2565942782 "DC/AC Accessory Inverter 4 Feedback 2";
CM_ BO_ 2565943038 "DC/AC Accessory Inverter 5 Command";
CM_ BO_ 2565943294 "DC/AC Accessory Inverter 5 Feedback";
CM_ BO_ 2364616958 "DC/AC Accessory Inverter 5 Status 2";
CM_ BO_ 2364617214 "DC/AC Accessory Inverter 5 Voltage";
CM_ BO_ 2565944062 "DC/AC Accessory Inverter 5 Feedback 2";
CM_ BO_ 2364617726 "Engine Pre-Chamber Fuel Valve Duration Command 1";
CM_ BO_ 2364617982 "Engine Pre-Chamber Fuel Valve Duration Command 2";
CM_ BO_ 2364618238 "Engine Pre-Chamber Fuel Valve Duration Command 3";
CM_ BO_ 2364618494 "Engine Pre-Chamber Fuel Valve Duration Command 4";
CM_ BO_ 2364618750 "Engine Pre-Chamber Fuel Valve Duration Command 5";
CM_ BO_ 2364619006 "Engine Pre-Chamber Fuel Valve Start of Actuation Command 1";
CM_ BO_ 2364619262 "Engine Pre-Chamber Fuel Valve Start of Actuation Command 2";
CM_ BO_ 2364619518 "Engine Pre-Chamber Fuel Valve Start of Actuation Command 3";
CM_ BO_ 2364619774 "Engine Pre-Chamber Fuel Valve Start of Actuation Command 4";
CM_ BO_ 2364620030 "Engine Pre-Chamber Fuel Valve Start of Actuation Command 5";
CM_ BO_ 2364620286 "Active Steering System Controls 1";
CM_ BO_ 2565947134 "ISO 11783: Secondary or Front Hitch Yaw Command";
CM_ BO_ 2565947390 "ISO 11783: Primary or Rear Hitch Yaw Command";
CM_ BO_ 2364621054 "Stationary Inverter Average Basic AC Quantities";
CM_ BO_ 2364621310 "Stationary Inverter Total AC Reactive Power";
CM_ BO_ 2364621566 "Stationary Inverter Total AC Power";
CM_ BO_ 2364621822 "Stationary Inverter Control";
CM_ BO_ 2364622078 "Stationary Inverter to Bus Sync Check Status";
CM_ BO_ 2364622334 "Engine Cylinder 1 Combustion Pressures";
CM_ BO_ 2364622590 "Engine Cylinder 2 Combustion Pressures";
CM_ BO_ 2364622846 "Engine Cylinder 3 Combustion Pressures";
CM_ BO_ 2364623102 "Engine Cylinder 4 Combustion Pressures";
CM_ BO_ 2364623358 "Engine Cylinder 5 Combustion Pressures";
CM_ BO_ 2364623614 "Engine Cylinder 6 Combustion Pressures";
CM_ BO_ 2364623870 "Engine Cylinder 7 Combustion Pressures";
CM_ BO_ 2364624126 "Engine Cylinder 8 Combustion Pressures";
CM_ BO_ 2364624382 "Engine Cylinder 9 Combustion Pressures";
CM_ BO_ 2364624638 "Engine Cylinder 10 Combustion Pressures";
BA_DEF_ BO_  "GenMsgCycleTime" INT 0 65535;
BA_DEF_ SG_  "SigType" ENUM "Default","Range","RangeSigned","ASCII","Discrete","Control","ReferencePGN","DTC","StringDelimiter","StringLength","StringLengthControl","MessageCounter","MessageChecksum";
BA_DEF_DEF_  "GenMsgCycleTime" 0;
BA_DEF_DEF_  "SigType" "Default";
BA_ "GenMsgCycleTime" BO_ 2364542462 100;
BA_ "GenMsgCycleTime" BO_ 2565869310 50;
BA_ "GenMsgCycleTime" BO_ 2565869566 50;
BA_ "GenMsgCycleTime" BO_ 2565869822 50;
BA_ "GenMsgCycleTime" BO_ 2565870078 50;
BA_ "GenMsgCycleTime" BO_ 2565870334 50;
BA_ "GenMsgCycleTime" BO_ 2364543998 10;
BA_ "GenMsgCycleTime" BO_ 2364544254 50;
BA_ "GenMsgCycleTime" BO_ 2364544510 100;
BA_ "GenMsgCycleTime" BO_ 2364544766 5000;
BA_ "GenMsgCycleTime" BO_ 2364545022 5000;
BA_ "GenMsgCycleTime" BO_ 2364545278 5000;
BA_ "GenMsgCycleTime" BO_ 2364545534 5000;
BA_ "GenMsgCycleTime" BO_ 2431654654 50;
BA_ "GenMsgCycleTime" BO_ 2364546302 100;
BA_ "GenMsgCycleTime" BO_ 2565873150 10;
BA_ "GenMsgCycleTime" BO_ 2364546814 20;
BA_ "GenMsgCycleTime" BO_ 2364548094 50;
BA_ "GenMsgCycleTime" BO_ 2364548350 50;
BA_ "GenMsgCycleTime" BO_ 2364548606 50;
BA_ "GenMsgCycleTime" BO_ 2364548862 50;
BA_ "GenMsgCycleTime" BO_ 2364549118 50;
BA_ "GenMsgCycleTime" BO_ 2364549374 50;
BA_ "GenMsgCycleTime" BO_ 2364549630 10;
BA_ "GenMsgCycleTime" BO_ 2364549886 10;
BA_ "GenMsgCycleTime" BO_ 2163223550 20;
BA_ "GenMsgCycleTime" BO_ 2297441534 50;
BA_ "GenMsgCycleTime" BO_ 2297441790 10;
BA_ "GenMsgCycleTime" BO_ 2364551166 50;
BA_ "GenMsgCycleTime" BO_ 2364551422 50;
BA_ "GenMsgCycleTime" BO_ 2230333950 20;
BA_ "GenMsgCycleTime" BO_ 2230334206 20;
BA_ "GenMsgCycleTime" BO_ 2431661054 50;
BA_ "GenMsgCycleTime" BO_ 2431661310 50;
BA_ "GenMsgCycleTime" BO_ 2364552958 100;
BA_ "GenMsgCycleTime" BO_ 2364553214 100;
BA_ "GenMsgCycleTime" BO_ 2364553470 20;
BA_ "GenMsgCycleTime" BO_ 2364553726 20;
BA_ "GenMsgCycleTime" BO_ 2297455358 10;
BA_ "GenMsgCycleTime" BO_ 2364564478 100;
BA_ "GenMsgCycleTime" BO_ 2364564734 100;
BA_ "GenMsgCycleTime" BO_ 2364564990 100;
BA_ "GenMsgCycleTime" BO_ 2364565246 100;
BA_ "GenMsgCycleTime" BO_ 2364565502 100;
BA_ "GenMsgCycleTime" BO_ 2364565758 100;
BA_ "GenMsgCycleTime" BO_ 2364566014 100;
BA_ "GenMsgCycleTime" BO_ 2364566270 100;
BA_ "GenMsgCycleTime" BO_ 2364566526 100;
BA_ "GenMsgCycleTime" BO_ 2364566782 100;
BA_ "GenMsgCycleTime" BO_ 2364567038 100;
BA_ "GenMsgCycleTime" BO_ 2364567294 50;
BA_ "GenMsgCycleTime" BO_ 2364575998 20;
BA_ "GenMsgCycleTime" BO_ 2364576254 20;
BA_ "GenMsgCycleTime" BO_ 2364576510 20;
BA_ "GenMsgCycleTime" BO_ 2364576766 100;
BA_ "GenMsgCycleTime" BO_ 2364577022 20;
BA_ "GenMsgCycleTime" BO_ 2364577278 100;
BA_ "GenMsgCycleTime" BO_ 2364577534 100;
BA_ "GenMsgCycleTime" BO_ 2364580094 100;
BA_ "GenMsgCycleTime" BO_ 2364590334 100;
BA_ "GenMsgCycleTime" BO_ 2364590590 100;
BA_ "GenMsgCycleTime" BO_ 2565917438 100;
BA_ "GenMsgCycleTime" BO_ 2364591102 100;
BA_ "GenMsgCycleTime" BO_ 2364591358 100;
BA_ "GenMsgCycleTime" BO_ 2565918206 100;
BA_ "GenMsgCycleTime" BO_ 2364592638 100;
BA_ "GenMsgCycleTime" BO_ 2364592894 100;
BA_ "GenMsgCycleTime" BO_ 2364593150 100;
BA_ "GenMsgCycleTime" BO_ 2565920510 100;
BA_ "GenMsgCycleTime" BO_ 2565920766 100;
BA_ "GenMsgCycleTime" BO_ 2565921534 100;
BA_ "GenMsgCycleTime" BO_ 2565921790 100;
BA_ "GenMsgCycleTime" BO_ 2565922558 100;
BA_ "GenMsgCycleTime" BO_ 2565922814 100;
BA_ "GenMsgCycleTime" BO_ 2565923582 100;
BA_ "GenMsgCycleTime" BO_ 2565923838 100;
BA_ "GenMsgCycleTime" BO_ 2364597758 100;
BA_ "GenMsgCycleTime" BO_ 2364598014 100;
BA_ "GenMsgCycleTime" BO_ 2364598270 100;
BA_ "GenMsgCycleTime" BO_ 2364598526 50;
BA_ "GenMsgCycleTime" BO_ 2565925374 50;
BA_ "GenMsgCycleTime" BO_ 2565925630 50;
BA_ "GenMsgCycleTime" BO_ 2565925886 50;
BA_ "GenMsgCycleTime" BO_ 2565926142 50;
BA_ "GenMsgCycleTime" BO_ 2431708670 20;
BA_ "GenMsgCycleTime" BO_ 2431710718 20;
BA_ "GenMsgCycleTime" BO_ 2364602878 100;
BA_ "GenMsgCycleTime" BO_ 2364603134 100;
BA_ "GenMsgCycleTime" BO_ 2364603390 50;
BA_ "GenMsgCycleTime" BO_ 2364603646 50;
BA_ "GenMsgCycleTime" BO_ 2364603902 50;
BA_ "GenMsgCycleTime" BO_ 2364604158 50;
BA_ "GenMsgCycleTime" BO_ 2364604414 100;
BA_ "GenMsgCycleTime" BO_ 2364604670 100;
BA_ "GenMsgCycleTime" BO_ 2364604926 100;
BA_ "GenMsgCycleTime" BO_ 2364605182 100;
BA_ "GenMsgCycleTime" BO_ 2364605438 100;
BA_ "GenMsgCycleTime" BO_ 2364605950 20;
BA_ "GenMsgCycleTime" BO_ 2565932798 50;
BA_ "GenMsgCycleTime" BO_ 2565933054 50;
BA_ "GenMsgCycleTime" BO_ 2364606718 100;
BA_ "GenMsgCycleTime" BO_ 2364606974 100;
BA_ "GenMsgCycleTime" BO_ 2364607230 100;
BA_ "GenMsgCycleTime" BO_ 2364607486 100;
BA_ "GenMsgCycleTime" BO_ 2364607742 100;
BA_ "GenMsgCycleTime" BO_ 2565934590 100;
BA_ "GenMsgCycleTime" BO_ 2498825982 50;
BA_ "GenMsgCycleTime" BO_ 2364608510 100;
BA_ "GenMsgCycleTime" BO_ 2297499902 1000;
BA_ "GenMsgCycleTime" BO_ 2431717886 100;
BA_ "GenMsgCycleTime" BO_ 2364609278 100;
BA_ "GenMsgCycleTime" BO_ 2364609534 100;
BA_ "GenMsgCycleTime" BO_ 2364609790 100;
BA_ "GenMsgCycleTime" BO_ 2364610046 100;
BA_ "GenMsgCycleTime" BO_ 2431719166 50;
BA_ "GenMsgCycleTime" BO_ 2364610558 100;
BA_ "GenMsgCycleTime" BO_ 2364610814 100;
BA_ "GenMsgCycleTime" BO_ 2364611070 100;
BA_ "GenMsgCycleTime" BO_ 2364611326 100;
BA_ "GenMsgCycleTime" BO_ 2364611582 100;
BA_ "GenMsgCycleTime" BO_ 2364611838 100;
BA_ "GenMsgCycleTime" BO_ 2364612094 100;
BA_ "GenMsgCycleTime" BO_ 2364612350 100;
BA_ "GenMsgCycleTime" BO_ 2364612606 100;
BA_ "GenMsgCycleTime" BO_ 2364612862 100;
BA_ "GenMsgCycleTime" BO_ 2364613118 100;
BA_ "GenMsgCycleTime" BO_ 2364613374 100;
BA_ "GenMsgCycleTime" BO_ 2364613630 100;
BA_ "GenMsgCycleTime" BO_ 2364613886 100;
BA_ "GenMsgCycleTime" BO_ 2364614142 100;
BA_ "GenMsgCycleTime" BO_ 2364614398 100;
BA_ "GenMsgCycleTime" BO_ 2364614654 1000;
BA_ "GenMsgCycleTime" BO_ 2364614910 100;
BA_ "GenMsgCycleTime" BO_ 2364615166 100;
BA_ "GenMsgCycleTime" BO_ 2565942014 100;
BA_ "GenMsgCycleTime" BO_ 2364615678 100;
BA_ "GenMsgCycleTime" BO_ 2364615934 100;
BA_ "GenMsgCycleTime" BO_ 2565942782 100;
BA_ "GenMsgCycleTime" BO_ 2565943038 100;
BA_ "GenMsgCycleTime" BO_ 2565943294 100;
BA_ "GenMsgCycleTime" BO_ 2364616958 100;
BA_ "GenMsgCycleTime" BO_ 2364617214 100;
BA_ "GenMsgCycleTime" BO_ 2565944062 100;
BA_ "GenMsgCycleTime" BO_ 2364617726 100;
BA_ "GenMsgCycleTime" BO_ 2364617982 100;
BA_ "GenMsgCycleTime" BO_ 2364618238 100;
BA_ "GenMsgCycleTime" BO_ 2364618494 100;
BA_ "GenMsgCycleTime" BO_ 2364618750 100;
BA_ "GenMsgCycleTime" BO_ 2364619006 100;
BA_ "GenMsgCycleTime" BO_ 2364619262 100;
BA_ "GenMsgCycleTime" BO_ 2364619518 100;
BA_ "GenMsgCycleTime" BO_ 2364619774 100;
BA_ "GenMsgCycleTime" BO_ 2364620030 100;
BA_ "GenMsgCycleTime" BO_ 2364620286 50;
BA_ "GenMsgCycleTime" BO_ 2364621054 100;
BA_ "GenMsgCycleTime" BO_ 2364621310 100;
BA_ "GenMsgCycleTime" BO_ 2364621566 100;
BA_ "GenMsgCycleTime" BO_ 2364621822 100;
BA_ "GenMsgCycleTime" BO_ 2364622078 100;
BA_ "GenMsgCycleTime" BO_ 2364622334 1000;
BA_ "GenMsgCycleTime" BO_ 2364622590 1000;
BA_ "GenMsgCycleTime" BO_ 2364622846 1000;
BA_ "GenMsgCycleTime" BO_ 2364623102 1000;
BA_ "GenMsgCycleTime" BO_ 2364623358 1000;
BA_ "GenMsgCycleTime" BO_ 2364623614 1000;
BA_ "GenMsgCycleTime" BO_ 2364623870 1000;
BA_ "GenMsgCycleTime" BO_ 2364624126 1000;
BA_ "GenMsgCycleTime" BO_ 2364624382 1000;
BA_ "GenMsgCycleTime" BO_ 2364624638 1000;
VAL_ 2364542462 BladeControlModeSwitch 0 "No button pressed" 1 "Mode button pressed" 2 "Manual button pressed" 3 "Automatic button pressed" 14 "Error Indicator" 15 "Not Installed" ;
VAL_ 2364542462 DesiredGradeOffsetSwitch 0 "No button pressed" 1 "Increment button pressed" 2 "Decrement button pressed" 14 "Error Indicator" 15 "Not installed" ;
VAL_ 2364542462 BladeAutoModeCommand 0 "Auto Allowed" 1 "Activity Allows Auto" 2 "Suspend Auto" 3 "Service Mode" 4 "Auto Not Allowed" 14 "Error Indicator" 15 "Not Supported" ;
VAL_ 2364542462 LeftBldCtrlModeOperatorControl 0 "No Change" 1 "Momentary Operator Control Request" 2 "Manual Operator Control Request" 3 "Automatic Operator Control Request" 12 "Reserved" 14 "Error Indicator" 15 "Not Installed" ;
VAL_ 2364542462 RightBldCtrlModeOperatorControl 0 "No Change" 1 "Momentary Operator Control Request" 2 "Manual Operator Control Request" 3 "Automatic Operator Control Request" 14 "Error Indicator" 15 "Not Installed" ;
VAL_ 2364542462 LeftDesiredBldOffsetOperatorCtrl 0 "No Operator Control Request" 1 "Increment Operator Control Request" 2 "Decrement Operator Control Request" 3 "Reserved" 14 "Error Indicator" 15 "Not installed" ;
VAL_ 2364542462 RightDsrdBldOffsetOperatorCtrl 0 "No Operator Control Request" 1 "Increment Operator Control Request" 2 "Decrement Operator Control Request" 3 "Reserved" 14 "Error Indicator" 15 "Not installed" ;
VAL_ 2364542462 SideShiftBldCtrlModeOperatorCtrl 0 "No Operator Control Request" 1 "Increment Operator Control Request" 2 "Decrement Operator Control Request" 3 "Reserved" 14 "Error Indicator" 15 "Not installed" ;
VAL_ 2364542462 SideShiftDsrdBldOffstOprtrCtrl 0 "No Operator Control Request" 1 "Momentary Operator Control Request" 2 "Manual Operator Control Request" 3 "Automatic Operator Control Request" 4 "Reserved" 14 "Error Indicator" 15 "Not Installed" ;
VAL_ 2364542462 SetElevationSensor1RefElevation 0 "Do not Set Reference Elevation" 1 "Set Reference Elevation" 2 "Reserved" 3 "Don't Care / Take No Action" ;
VAL_ 2364542462 SetElevationSensor2RefElevation 0 "Do not Set Reference Elevation" 1 "Set Reference Elevation" 2 "Reserved" 3 "Don't Care / Take No Action" ;
VAL_ 2565869310 EngExhaust1GasSensor1PowerRange 0 "Not in range" 1 "In range" 2 "Error" 3 "Not available" ;
VAL_ 2565869310 Aftrtrtmnt1IntkGasSnsrAtTemp 0 "Not in range" 1 "In range" 2 "Error" 3 "Not available" ;
VAL_ 2565869310 EngineExhaust1NOx1ReadingStable 0 "Not stable" 1 "Stable" 2 "Error" 3 "Not available" ;
VAL_ 2565869310 Aft1IntkWdRngPrcntO2RdngStable 0 "Not stable" 1 "Stable" 2 "Error" 3 "Not available" ;
VAL_ 2565869310 Aftrtrtmnt1IntkGasSensorHtrCtrl 0 "Automatic" 1 "Preheat 2" 2 "Preheat 1" 3 "Heater off" ;
VAL_ 2565869310 EngExhst1NOxSnsr1SelfDiagnssStat 0 "Diagnosis not active" 1 "NOx Sensor EEB1 Self-diagnosis active flag" 2 "NOx Sensor EEB1 Self-diagnosis Result Complete" 3 "NOx Sensor EEB1 Self-diagnosis aborted" 4 "NOx Sensor EEB1 Self-diagnosis not possible" 5 "Reserved" 7 "Not Supported" ;
VAL_ 2565869566 Aftrtrtmnt1OtltGasSensorPwrInRng 0 "Not in range" 1 "In range" 2 "Error" 3 "Not available" ;
VAL_ 2565869566 Aftrtrtmnt1OtltGasSnsrAtTemp 0 "Not in range" 1 "In range" 2 "Error" 3 "Not available" ;
VAL_ 2565869566 Aftrtrtmnt1OtltNOxReadingStable 0 "Not stable" 1 "Stable" 2 "Error" 3 "Not available" ;
VAL_ 2565869566 Aftrtrtmnt1OtltWdRngO2RdngStable 0 "Not stable" 1 "Stable" 2 "Error" 3 "Not available" ;
VAL_ 2565869566 Aftrtrtmnt1OtltGasSensorHtrCtrl 0 "Automatic" 1 "Preheat 2" 2 "Preheat 1" 3 "Heater off" ;
VAL_ 2565869566 Aft1OtltNOxSnsrSelfDiagnssStat 0 "Diagnosis not active" 1 "NOx Sensor ATO1 Self-diagnosis active flag" 2 "NOx Sensor ATO1 Self-diagnosis Result Complete" 3 "NOx Sensor ATO1 Self-diagnosis aborted" 4 "NOx Sensor ATO1 Self-diagnosis not possible" 5 "Reserved" 7 "Not Supported" ;
VAL_ 2565869822 Aftrtrtmnt2IntkGasSnsrAtTemp 0 "Not in range" 1 "In range" 2 "Error" 3 "Not available" ;
VAL_ 2565869822 EngineExhaust2NOx1ReadingStable 0 "Not stable" 1 "Stable" 2 "Error" 3 "Not available" ;
VAL_ 2565869822 Aft2IntkWdRngPrcntO2RdngStable 0 "Not stable" 1 "Stable" 2 "Error" 3 "Not available" ;
VAL_ 2565869822 Aftrtrtmnt2IntkGasSensorHtrCtrl 0 "Automatic" 1 "Preheat 2" 2 "Preheat 1" 3 "Heater off" ;
VAL_ 2565869822 EngExhst2NOxSnsr1SelfDiagnssStat 0 "Diagnosis not active" 1 "NOx Sensor EEB2 Self-diagnosis active flag" 2 "NOx Sensor EEB2 Self-diagnosis Result Complete" 3 "NOx Sensor EEB2 Self-diagnosis aborted" 4 "NOx Sensor EEB2 Self-diagnosis not possible" 5 "Reserved" 7 "Not Supported" ;
VAL_ 2565869822 EngExhst2Intk2GsSensorPwrSupply 0 "Off" 1 "On" 2 "Error" 3 "Unavailable" ;
VAL_ 2565870078 Aftrtrtmnt2OtltGasSensorPwrInRng 0 "Not in range" 1 "In range" 2 "Error" 3 "Not available" ;
VAL_ 2565870078 Aftrtrtmnt2OtltGasSnsrAtTemp 0 "Not in range" 1 "In range" 2 "Error" 3 "Not available" ;
VAL_ 2565870078 Aftrtrtmnt2OtltNOxReadingStable 0 "Not stable" 1 "Stable" 2 "Error" 3 "Not available" ;
VAL_ 2565870078 Aftrtrtmnt2OtltWdRngO2RdngStable 0 "Not stable" 1 "Stable" 2 "Error" 3 "Not available" ;
VAL_ 2565870078 Aftrtrtmnt2OtltGasSensorHtrCtrl 0 "Automatic" 1 "Preheat 2" 2 "Preheat 1" 3 "Heater off" ;
VAL_ 2565870078 Aft2OtltNOxSnsrSelfDiagnssStat 0 "Diagnosis not active" 1 "NOx Sensor ATO2 Self-diagnosis active flag" 2 "NOx Sensor ATO2 Self-diagnosis Result Complete" 3 "NOx Sensor ATO2 Self-diagnosis aborted" 4 "NOx Sensor ATO2 Self-diagnosis not possible" 5 "Reserved" 7 "Not Supported" ;
VAL_ 2565870078 Aftrtrtmnt2Otlt2GsSnsrPwrSupply 0 "Off" 1 "On" 2 "Error" 3 "Unavailable" ;
VAL_ 2565870334 FifthWheelRollWarningIndicator 0 "Limit not exceeded" 1 "Limit exceeded" 2 "Error" 3 "Not Available" ;
VAL_ 2364543998 PitchAngleFigureOfMerit 0 "Pitch angle fully functional" 1 "Pitch angle degraded" 2 "Error" 3 "Not available" ;
VAL_ 2364543998 RollAngleFigureOfMerit 0 "Roll angle fully functional" 1 "Roll angle degraded" 2 "Error" 3 "Not available" ;
VAL_ 2364543998 PitchRateFigureOfMerit 0 "Pitch rate fully functional" 1 "Pitch rate degraded" 2 "Error" 3 "Not available" ;
VAL_ 2364543998 PitchAndRollCompensated 0 "Compensation Off" 1 "Compensation On" 2 "Error" 3 "Not Available" ;
VAL_ 2364544254 RelativeBladeHeightFigureOfMerit 0 "Relative Blade Height fully functional" 1 "Relative Blade Height degraded" 2 "Relative Blade Height failed" 3 "Relative Blade Height not available" ;
VAL_ 2364544254 BladeRotationAngleFigureOfMerit 0 "Blade Rotation Angle fully functional" 1 "Blade Rotation Angle degraded" 2 "Blade Rotation Angle failed" 3 "Blade Rotation Angle not available" ;
VAL_ 2364544510 RqedGenOverallPwrFactorLagging 0 "Leading" 1 "Lagging" 2 "Reserved" 3 "Not available or Not installed" ;
VAL_ 2364544766 EngineCylinder1CombustionStatus 0 "No combustion" 1 "Combustion exists" 2 "Error" 3 "Not available" ;
VAL_ 2364544766 EngineCylinder2CombustionStatus 0 "No combustion" 1 "Combustion exists" 2 "Error" 3 "Not available" ;
VAL_ 2364544766 EngineCylinder3CombustionStatus 0 "No combustion" 1 "Combustion exists" 2 "Error" 3 "Not available" ;
VAL_ 2364544766 EngineCylinder4CombustionStatus 0 "No combustion" 1 "Combustion exists" 2 "Error" 3 "Not available" ;
VAL_ 2364544766 EngineCylinder5CombustionStatus 0 "No combustion" 1 "Combustion exists" 2 "Error" 3 "Not available" ;
VAL_ 2364544766 EngineCylinder6CombustionStatus 0 "No combustion" 1 "Combustion exists" 2 "Error" 3 "Not available" ;
VAL_ 2364544766 EngineCylinder7CombustionStatus 0 "No combustion" 1 "Combustion exists" 2 "Error" 3 "Not available" ;
VAL_ 2364544766 EngineCylinder8CombustionStatus 0 "No combustion" 1 "Combustion exists" 2 "Error" 3 "Not available" ;
VAL_ 2364544766 EngineCylinder9CombustionStatus 0 "No combustion" 1 "Combustion exists" 2 "Error" 3 "Not available" ;
VAL_ 2364544766 EngineCylinder10CombustionStatus 0 "No combustion" 1 "Combustion exists" 2 "Error" 3 "Not available" ;
VAL_ 2364544766 EngineCylinder11CombustionStatus 0 "No combustion" 1 "Combustion exists" 2 "Error" 3 "Not available" ;
VAL_ 2364544766 EngineCylinder12CombustionStatus 0 "No combustion" 1 "Combustion exists" 2 "Error" 3 "Not available" ;
VAL_ 2364544766 EngineCylinder13CombustionStatus 0 "No combustion" 1 "Combustion exists" 2 "Error" 3 "Not available" ;
VAL_ 2364544766 EngineCylinder14CombustionStatus 0 "No combustion" 1 "Combustion exists" 2 "Error" 3 "Not available" ;
VAL_ 2364544766 EngineCylinder15CombustionStatus 0 "No combustion" 1 "Combustion exists" 2 "Error" 3 "Not available" ;
VAL_ 2364544766 EngineCylinder16CombustionStatus 0 "No combustion" 1 "Combustion exists" 2 "Error" 3 "Not available" ;
VAL_ 2364544766 EngineCylinder17CombustionStatus 0 "No combustion" 1 "Combustion exists" 2 "Error" 3 "Not available" ;
VAL_ 2364544766 EngineCylinder18CombustionStatus 0 "No combustion" 1 "Combustion exists" 2 "Error" 3 "Not available" ;
VAL_ 2364544766 EngineCylinder19CombustionStatus 0 "No combustion" 1 "Combustion exists" 2 "Error" 3 "Not available" ;
VAL_ 2364544766 EngineCylinder20CombustionStatus 0 "No combustion" 1 "Combustion exists" 2 "Error" 3 "Not available" ;
VAL_ 2364544766 EngineCylinder21CombustionStatus 0 "No combustion" 1 "Combustion exists" 2 "Error" 3 "Not available" ;
VAL_ 2364544766 EngineCylinder22CombustionStatus 0 "No combustion" 1 "Combustion exists" 2 "Error" 3 "Not available" ;
VAL_ 2364544766 EngineCylinder23CombustionStatus 0 "No combustion" 1 "Combustion exists" 2 "Error" 3 "Not available" ;
VAL_ 2364544766 EngineCylinder24CombustionStatus 0 "No combustion" 1 "Combustion exists" 2 "Error" 3 "Not available" ;
VAL_ 2565873150 SteeringWheelAglRangeCounterType 0 "relative number of counts" 1 "absolute number of counts" 2 "not defined" 3 "signal not available" ;
VAL_ 2565873150 SteeringAngleSensorActiveMode 0 "Programming mode active" 1 "Normal mode active" 2 "Reserved" 3 "Not available" ;
VAL_ 2565873150 SteeringAngleSensorCalibrated 0 "SAS not calibrated" 1 "SAS calibrated" 2 "Reserved" 3 "Not available" ;
VAL_ 2364546814 EngineSelfInducedDerateInhibit 0 "Engine is allowed to impose a self-induced derate" 1 "Engine is inhibited from imposing a self-induced derate" 2 "SAE Reserved" 3 "Don't care / take no action" ;
VAL_ 2565874174 EngSpeedSnsr3TimingPatternStatus 0 "Not OK" 1 "OK" 2 "Error" 3 "Not available" ;
VAL_ 2565874174 EngSpeedSnsr2TimingPatternStatus 0 "Not OK" 1 "OK" 2 "Error" 3 "Not available" ;
VAL_ 2565874174 EngSpeedSnsr1TimingPatternStatus 0 "Not OK" 1 "OK" 2 "Error" 3 "Not available" ;
VAL_ 2565874430 MachineSelectedDirection 0 "Reverse" 1 "Forward" 2 "Error indication" 3 "Not available" ;
VAL_ 2565874430 MachineSelectedSpeedSource 0 "Wheel-based speed" 1 "Ground-based speed" 2 "Navigation-based speed" 3 "Blended speed" 4 "Simulated speed" 5 "Reserved" 7 "Not available" ;
VAL_ 2565874430 PersistentLimitStatus 0 "Not limited" 1 "Operator limited/controlled" 2 "Limited high" 3 "Limited low" 4 "Reserved" 6 "Non-recoverable fault" 7 "Not available" ;
VAL_ 2364548094 Aftertreatment1SCRSystemState 0 "Dormant" 1 "Preparing dosing readiness" 2 "Normal dosing operation" 3 "System error pending" 4 "Purging" 5 "Protect mode against heat" 6 "Protect mode against cold" 7 "Shutoff" 8 "Diagnosis" 9 "Service test mode, dosing allowed" 10 "Service test mode, dosing not allowed" 11 "Ok to Power Down" 12 "Priming" 13 "Reserved for future assignment by SAE" 14 "Error" 15 "Not available" ;
VAL_ 2364548094 Aftertreatment1SCRSystem2State 0 "Dormant" 1 "Preparing dosing readiness" 2 "Normal dosing operation" 3 "System error pending" 4 "Purging" 5 "Protect mode against heat" 6 "Protect mode against cold" 7 "Shutoff" 8 "Diagnosis" 9 "Service test mode, dosing allowed" 10 "Service test mode, dosing not allowed" 11 "Ok to Power Down" 12 "Priming" 13 "Reserved for future assignment by SAE" 14 "Error" 15 "Not available" ;
VAL_ 2364548350 Aftrtrtmnt1SCRSystemRqedState 0 "Dormant" 1 "Preparing dosing readiness" 2 "Normal dosing operation" 3 "System error pending" 4 "Reserved for future assignment by SAE" 5 "Protect mode against heat" 6 "Protect mode against cold" 7 "Shutoff" 8 "Diagnosis" 9 "Service test mode, dosing allowed" 10 "Service test mode, dosing not allowed" 11 "Reserved for future assignment by SAE" 14 "Error" 15 "Not available" ;
VAL_ 2364548350 Aft1DslExhstFldHydrStffnssCkPmSt 0 "not allowed" 1 "DEF hydraulic stiffness check allowed" 2 "error" 3 "not available" ;
VAL_ 2364548350 Aft1DslExhstFldDsngTtInjectPmSt 0 "not allowed" 1 "DEF dosing test injection allowed" 2 "error" 3 "not available" ;
VAL_ 2364548606 Aftrtrtmnt1OtltNH3ReadingStable 0 "Reading is not stable" 1 "Reading is stable" 2 "Error" 3 "Not available" ;
VAL_ 2364548606 Aft1OtltNH3GasSnsrPwrInRng 0 "Power is not in range" 1 "Power is in range" 2 "Error" 3 "Not available" ;
VAL_ 2364548606 Aftrtrtmnt1OtltNH3GasSnsrAtTemp 0 "Heater element is not in range" 1 "Heater element is in range" 2 "Error" 3 "Not available" ;
VAL_ 2364548606 Aftrtrtmnt1OtltNH3GasSnsrHtrCtrl 0 "Automatic" 1 "Preheat 2" 2 "Preheat 1" 3 "Heater off or not available" ;
VAL_ 2364548862 Aftertreatment2SCRSystemState 0 "Dormant" 1 "Preparing dosing readiness" 2 "Normal dosing operation" 3 "System error pending" 4 "Purging" 5 "Protect mode against heat" 6 "Protect mode against cold" 7 "Shutoff" 8 "Diagnosis" 9 "Service test mode, dosing allowed" 10 "Service test mode, dosing not allowed" 11 "Ok to Power Down" 12 "Priming" 13 "Reserved for future assignment by SAE" 14 "Error" 15 "Not available" ;
VAL_ 2364548862 Aftertreatment2SCRSystem2State 0 "Dormant" 1 "Preparing dosing readiness" 2 "Normal dosing operation" 3 "System error pending" 4 "Purging" 5 "Protect mode against heat" 6 "Protect mode against cold" 7 "Shutoff" 8 "Diagnosis" 9 "Service test mode, dosing allowed" 10 "Service test mode, dosing not allowed" 11 "Ok to Power Down" 12 "Priming" 13 "Reserved for future assignment by SAE" 14 "Error" 15 "Not available" ;
VAL_ 2364549118 Aftrtrtmnt2SCRSystemRqedState 0 "Dormant" 1 "Preparing dosing readiness" 2 "Normal dosing operation" 3 "System error pending" 4 "Reserved for future assignment by SAE" 5 "Protect mode against heat" 6 "Protect mode against cold" 7 "Shutoff" 8 "Diagnosis" 9 "Service test mode, dosing allowed" 10 "Service test mode, dosing not allowed" 11 "Reserved for future assignment by SAE" 14 "Error" 15 "Not available" ;
VAL_ 2364549118 Aft2DslExhstFldHydrStffnssCkPmSt 0 "not allowed" 1 "DEF hydraulic stiffness check allowed" 2 "error" 3 "not available" ;
VAL_ 2364549118 Aft2DslExhstFldDsngTtInjectPmSt 0 "not allowed" 1 "DEF dosing test injection allowed" 2 "error" 3 "not available" ;
VAL_ 2364549374 Aftrtrtmnt2OtltNH3ReadingStable 0 "Reading is not stable" 1 "Reading is stable" 2 "Error" 3 "Not available" ;
VAL_ 2364549374 Aft2OtltNH3GasSnsrPwrInRng 0 "Heater element is not in range" 1 "Heater element is in range" 2 "Error" 3 "Not available" ;
VAL_ 2364549374 Aftrtrtmnt2OtltNH3GasSnsrAtTemp 0 "Heater element is not in range" 1 "Heater element is in range" 2 "Error" 3 "Not available" ;
VAL_ 2364549374 Aftrtrtmnt2OtltNH3GasSnsrHtrCtrl 0 "Automatic" 1 "Preheat 2" 2 "Preheat 1" 3 "Heater off or not available" ;
VAL_ 2364549630 PitchAngleCompensation 0 "On" 1 "Off" 2 "Error" 3 "Not Available" ;
VAL_ 2364549630 PitchAngleFigureOfMerit 0 "Pitch angle fully functional" 1 "Pitch angle degraded" 2 "Error" 3 "Not available" ;
VAL_ 2364549630 RollAngleCompensation 0 "On" 1 "Off" 2 "Error" 3 "Not Available" ;
VAL_ 2364549630 RollAngleFigureOfMerit 0 "Roll angle fully functional" 1 "Roll angle degraded" 2 "Error" 3 "Not available" ;
VAL_ 2364549886 PitchRateFigureOfMerit 0 "Pitch rate fully functional" 1 "Pitch rate degraded" 2 "Error" 3 "Not available" ;
VAL_ 2364549886 RollRateFigureOfMerit 0 "Roll rate fully functional" 1 "Roll rate degraded" 2 "Error" 3 "Not available" ;
VAL_ 2364549886 YawRateFigureOfMerit 0 "Yaw rate fully functional" 1 "Yaw rate degraded" 2 "Error" 3 "Not available" ;
VAL_ 2163223550 CrashType 1 "frontal crash" 2 "rear crash" 4 "side crash (left)" 8 "side crash (right)" 16 "rollover" ;
VAL_ 2297441534 MaterialLiftSwitch 0 "Don't Lift" 1 "Lift" 2 "Error" 3 "Not Available" ;
VAL_ 2297441534 MaterialDropSwitch 0 "Don't Drop" 1 "Drop" 2 "Error" 3 "Not Available" ;
VAL_ 2297441534 GeneratorCurrentBoostActvStatus 0 "Off" 1 "On" 2 "Error" 3 "Not available" ;
VAL_ 2297441534 MaterialLiftActiveStatus 0 "Off" 1 "On" 2 "Error" 3 "Not available" ;
VAL_ 2297441534 MaterialDropActiveStatus 0 "Off" 1 "On" 2 "Error" 3 "Not available" ;
VAL_ 2297441534 LiftRelayControl 0 "Off, Disable Lift Relay Request" 1 "On, Enable Lift Relay Request" 2 "Reserved" 3 "Take No Action" ;
VAL_ 2297441534 DropRelayControl 0 "Off, Disable Drop Relay Request" 1 "On, Enable Drop Relay Request" 2 "Reserved" 3 "Take No Action" ;
VAL_ 2297441534 MagnetGeneratorControl 0 "Off, Disable Generator" 1 "On, Enable Generator" 2 "Reserved" 3 "Take No Action" ;
VAL_ 2297441790 LateralAccelerationFigureOfMerit 0 "lateral acceleration is fully functional" 1 "lateral acceleration is degraded" 2 "error" 3 "not available" ;
VAL_ 2297441790 LongitudinalAccltnFigureOfMerit 0 "longitudinal acceleration is fully functional" 1 "longitudinal acceleration is degraded" 2 "error" 3 "not available" ;
VAL_ 2297441790 VerticalAccltnFigureOfMerit 0 "vertical acceleration is fully functional" 1 "verticalacceleration is degraded" 2 "error" 3 "not available" ;
VAL_ 2297441790 SuppVarTrnsmRepttnRateAccltnSnsr 0 "Reserve for SAE assignment" 1 "Reserved for SAE assignment" 2 "20 ms rate supported" 3 "10 ms rate supported" ;
VAL_ 2364551166 AdvEmergencyBrakingSystemState 0 "system is not ready" 1 "system is temporarily not available" 2 "system is deactivated by driver" 3 "system is ready and activated" 4 "driver overrides system" 5 "forward collision warning active" 6 "forward collision warning with braking" 7 "forward collision emergency braking active" 8 "system performance and/or sensitivity limited" 9 "reserved for future use" 14 "error indication" 15 "not available / not installed" ;
VAL_ 2364551166 CollisionWarningLevel 0 "no warning" 1 "warning level 1" 2 "warning level 2" 3 "warning level 3" 4 "warning level 4" 5 "warning level 5" 6 "warning level 6" 7 "warning level 7" 8 "reserved" 15 "don't care / take no action" ;
VAL_ 2364551166 RelvntObjDetctAdvEmrgncyBrkngSys 0 "no relevant object monitored" 1 "relevant object monitored" 2 "relevant object detected" 3 "reserved" 6 "error indication" 7 "signal not available / not installed" ;
VAL_ 2364551166 BendOffProbabilityOfRelevantObj 0 "no indication" 1 "low probability" 2 "medium probability" 3 "high probability" 4 "highest probability" 5 "object already turning" 6 "error indication" 7 "signal not available / not installed" ;
VAL_ 2364551166 RoadDepartrAdvEmrgBrkngSysStat 0 "system is not ready" 1 "system is temporarily not available" 2 "system is deactivated by driver" 3 "system is ready and activated" 4 "driver overrides system" 5 "road departure warning active" 6 "road departure warning with braking" 7 "road departure emergency braking active" 8 "system performance and/or sensitivity limited" 9 "reserved for future use" 14 "error indication" 15 "not available / not installed" ;
VAL_ 2364551422 TransmitterCommandState 0 "Stop" 1 "Clear" 2 "Field Test" 3 "Transmitter Test" 4 "Standby" 5 "Reserved" 14 "Error" 15 "Don't Care" ;
VAL_ 2230333950 WandSensorFigureOfMerit 0 "Sensor fully functional" 1 "Sensor degraded" 2 "Sensor failed" 3 "Sensor not available" ;
VAL_ 2230334206 LnrDisplacmntSnsrSnsrFigOfMerit 0 "Sensor fully functional" 1 "Sensor degraded" 2 "Sensor failed" 3 "Sensor not available" ;
VAL_ 2431661054 Aft1SCRIntrmedNH3RdngStable 0 "Reading is not stable" 1 "Reading is stable" 2 "Error" 3 "Not available" ;
VAL_ 2431661054 Aft1SCRIntrmedNH3SnsrPwrInRng 0 "Power is not in range" 1 "Power is in range" 2 "Error" 3 "Not available" ;
VAL_ 2431661054 Aft1SCRIntrmedNH3SnsrAtTemp 0 "Heater element is not in range" 1 "Heater element is in range" 2 "Error" 3 "Not available" ;
VAL_ 2431661054 Aft1SCRIntrmedNH3SnsrHtrCtrl 0 "Automatic" 1 "Preheat 2" 2 "Preheat 1" 3 "Heater off or not available" ;
VAL_ 2431661310 Aft2SCRIntrmedNH3RdngStable 0 "Reading is not stable" 1 "Reading is stable" 2 "Error" 3 "Not available" ;
VAL_ 2431661310 Aft2SCRIntrmedNH3SnsrPwrInRng 0 "Heater element is not in range" 1 "Heater element is in range" 2 "Error" 3 "Not available" ;
VAL_ 2431661310 Aft2SCRIntrmedNH3SnsrAtTemp 0 "Heater element is not in range" 1 "Heater element is in range" 2 "Error" 3 "Not available" ;
VAL_ 2431661310 Aft2SCRIntrmedNH3SnsrHtrCtrl 0 "Automatic" 1 "Preheat 2" 2 "Preheat 1" 3 "Heater off or not available" ;
VAL_ 2364552958 HVES1DisChrgPowerLmtDTStateChrg 0 "No power limit for this reason" 1 "Power limited for this reason" 2 "Error" 3 "Not Available" ;
VAL_ 2364552958 HVES1DisChrgPwrLmtDTBattryTemp 0 "No power limit for this reason" 1 "Power limited for this reason" 2 "Error" 3 "Not Available" ;
VAL_ 2364552958 HVES1DisChrgPwrLmtDTBattDiagCond 0 "No power limit for this reason" 1 "Power limited for this reason" 2 "Error" 3 "Not Available" ;
VAL_ 2364552958 HVES1DisChrgPwrLmtDTBattCellVltg 0 "No power limit for this reason" 1 "Power limited for this reason" 2 "Error" 3 "Not Available" ;
VAL_ 2364552958 HVES1DisChrgPowerLmtDTBattryCurr 0 "No power limit for this reason" 1 "Power limited for this reason" 2 "Error" 3 "Not Available" ;
VAL_ 2364552958 HVES1DisChrgPwrLmtDTUndefndCause 0 "No power limit for this reason" 1 "Power limited for this reason" 2 "Error" 3 "Not Available" ;
VAL_ 2364552958 HVES1ChrgPowerLimitDTStateChrg 0 "No power limit for this reason" 1 "Power limited for this reason" 2 "Error" 3 "Not Available" ;
VAL_ 2364552958 HVES1ChrgPwrLmtDTBattryTemp 0 "No power limit for this reason" 1 "Power limited for this reason" 2 "Error" 3 "Not Available" ;
VAL_ 2364552958 HVES1ChrgPwrLmtDTBattDiagCondtn 0 "No power limit for this reason" 1 "Power limited for this reason" 2 "Error" 3 "Not Available" ;
VAL_ 2364552958 HVES1ChrgPwrLmtDTBattryCellVltg 0 "No power limit for this reason" 1 "Power limited for this reason" 2 "Error" 3 "Not Available" ;
VAL_ 2364552958 HVES1ChrgPowerLimitDTBattryCurr 0 "No power limit for this reason" 1 "Power limited for this reason" 2 "Error" 3 "Not Available" ;
VAL_ 2364552958 HVES1ChrgPwrLmtDTUndefinedCause 0 "No power limit for this reason" 1 "Power limited for this reason" 2 "Error" 3 "Not Available" ;
VAL_ 2364553214 EngTurboCmprBlowoffActr1TempStat 0 "High Most severe" 1 "High Least severe" 2 "In Range" 3 "Low Least severe" 4 "Low Most severe" 5 "Not Defined" 6 "Error" 7 "Not available" ;
VAL_ 2364553214 EngTurboCmprBlowoffActr1OpStat 0 "Normal" 1 "Alarm" 2 "Alarm High Severity" 3 "Derate Active" 4 "Controlled Shutdown Active" 5 "Uncontrolled Shutdown Active" 6 "Calibration in Progress" 7 "Reserved for future assignment" 14 "Error" 15 "Not available" ;
VAL_ 2364553470 EngineDualFuelModeCommand 0 "De-activate dual fuel mode" 1 "Activate dual fuel mode" 2 "Reserved" 3 "Not available" ;
VAL_ 2364576254 HVES1CellVoltageDiffStatus 0 "Cell-to-cell voltage differential is within acceptable limits" 1 "Cell-to-cell voltage differential exceeds acceptable limits but can be corrected via auto-balancing" 2 "Cell-to-cell voltage differential exceeds acceptable limits to a point where external maintenance balancing is required to restore battery performance" 3 "Cell-to-cell voltage differential exceeds acceptable limits to a point where external maintenance balancing cannot restore battery performance" 4 "Cell-to-cell voltage differential exceeds acceptable limits" 5 "Reserved" 14 "Error" 15 "Not Available" ;
VAL_ 2364576510 HVES1CellTemperatureDiffStatus 0 "Cell-to-cell temperature differential is within acceptable limits" 1 "Cell-to-cell temperature differential exceeds acceptable limits" 2 "Error" 3 "Not Available" ;
VAL_ 2364577534 HVES1HghVoltageBusPosContactStat 0 "Contactor Open" 1 "Contactor Closed" 2 "Error" 3 "Not Available" ;
VAL_ 2364577534 HVES1HghVoltageBusNegContactStat 0 "Contactor Open" 1 "Contactor Closed" 2 "Error" 3 "Not Available" ;
VAL_ 2364577534 HVES1HghVoltageBusDiscnnctFrwrng 0 "Disconnect not pending" 1 "Disconnect imminent due to battery pack voltage approaching minimum acceptable level" 2 "Disconnect imminent due to battery pack voltage approaching maximum acceptable level" 3 "Disconnect imminent due to module voltage approaching minimum acceptable level" 4 "Disconnect imminent due to module voltage approaching maximum acceptable level" 5 "Disconnect imminent due to cell voltage approaching minimum acceptable level" 6 "Disconnect imminent due to cell voltage approaching maximum acceptable level" 7 "Disconnect imminent due to battery pack current approaching maximum acceptable level" 8 "Reserved" 13 "Disconnect imminent" 14 "Error" 15 "Not Available" ;
VAL_ 2364577534 HVES1HghVltgBusPreChrgRelyStat 0 "Relay Open" 1 "Relay Closed" 2 "Error" 3 "Not Available" ;
VAL_ 2364577534 HVES1CenterOfPackContactorState 0 "Contactor Open" 1 "Contactor Closed" 2 "Error" 3 "Not Available" ;
VAL_ 2364577534 HVES1HiVltgBusActIsolatnTestStat 0 "No test requested / No test in process" 1 "Test requested but not yet in process" 2 "Test in process" 3 "Test complete - isolation acceptable" 4 "Test complete - isolation marginal" 5 "Test complete - isolation fault" 6 "Test is inhibited" 7 "Reserved" 14 "Error" 15 "Not available" ;
VAL_ 2364577534 HVES1HiVltgBusPassIsolatnTestSt 0 "No test requested / No test in process" 1 "Test requested but not yet in process" 2 "Test in process" 3 "Test complete - isolation acceptable" 4 "Test complete - isolation marginal" 5 "Test complete - isolation fault" 6 "Test is inhibited" 7 "Reserved" 14 "Error" 15 "Not available" ;
VAL_ 2364577534 HVES1HVILStatus 0 "HVIL Closed" 1 "HVIL Open" 2 "Error" 3 "Not Available" ;
VAL_ 2364577534 HVES1InertiaSwitchStatus 0 "No impact sensed" 1 "Impact sensed" 2 "Error" 3 "Not Available" ;
VAL_ 2364577534 HVES1StateOfChargeStatus 0 "SOC level is acceptable." 1 "SOC is approaching its recommended lower limit" 2 "SOC is at its recommended lower limit" 3 "SOC is below its recommended lower limit" 4 "SOC is approaching its recommended upper limit" 5 "SOC is at its recommended upper limit" 6 "SOC is above its recommended upper limit" 7 "Reserved" 14 "Error" 15 "Not  Available" ;
VAL_ 2364577534 HVES1CellBalanceStatus 0 "Cells are balanced" 1 "Cells are unbalanced" 2 "Error" 3 "Not Available" ;
VAL_ 2364577534 HVES1CellBalancingActive 0 "Cell balancing is not active" 1 "Cell balancing is active" 2 "Error" 3 "Not Available" ;
VAL_ 2364577534 HVES1InternalChargerStatus 0 "Charging off" 1 "Charging on" 2 "Error" 3 "Not Available" ;
VAL_ 2364577534 HVES1HghVoltageBusConnectnStatus 0 "Disconnected" 1 "Connected" 2 "Connection in Process" 3 "Disconnection in Process" 4 "Disconnected: Precharge Failed" 5 "Reserved" 14 "Error" 15 "Not Available" ;
VAL_ 2364577534 HVES1OperationalStatus 0 "Initialization in Process" 1 "Initialization Complete, awaiting Operation Consent" 2 "Operational" 3 "Normal Power-Down in Process" 4 "Emergency Power-Down In Process" 5 "Disabled by external command" 6 "Disabled by internal decision of HVES controller" 7 "Reserved" 14 "Error" 15 "Not Available" ;
VAL_ 2565917438 DCACAccssryInv1PwrLmtDTDCSdeCur 0 "No power limit for this reason" 1 "Power limited for this reason" 2 "Error" 3 "Not Available" ;
VAL_ 2565917438 DCACAccryInv1PwrLmtDTACSdeRMSCur 0 "No power limit for this reason" 1 "Power limited for this reason" 2 "Error" 3 "Not Available" ;
VAL_ 2565917438 DCACAccryInv1PwrLmtDTDCSdeVltgMn 0 "No power limit for this reason" 1 "Power limited for this reason" 2 "Error" 3 "Not Available" ;
VAL_ 2565917438 DCACAccssryInvert1FreqCmdBlwMin 0 "No frequency limit for this reason" 1 "Frequency limited for this reason" 2 "Error" 3 "Not Available" ;
VAL_ 2565917438 DCACAccryInv1FreqCmdExceedsMax 0 "No frequency limit for this reason" 1 "Frequency limited for this reason" 2 "Error" 3 "Not Available" ;
VAL_ 2565917438 DCACAccryInv1PwrLmtDTCtrllerTemp 0 "No power limit for this reason" 1 "Power limited for this reason" 2 "Error" 3 "Not Available" ;
VAL_ 2565917438 DCACAccInv1PwrLmtDTElctrncFlTmp 0 "No power limit for this reason" 1 "Power limited for this reason" 2 "Error" 3 "Not Available" ;
VAL_ 2565917438 DCACAccInv1PwrLmtDTPwrElctrsTmp 0 "No power limit for this reason" 1 "Power limited for this reason" 2 "Error" 3 "Not Available" ;
VAL_ 2565917438 DCACAccryInv1PwrLmtDTRateChgLmt 0 "No power limit for this reason" 1 "Power limited for this reason" 2 "Error" 3 "Not Available" ;
VAL_ 2565917438 DCACAccryInv1PwrLmtDTUndefndRsn 0 "No power limit for this reason" 1 "Power limited for this reason" 2 "Error" 3 "Not Available" ;
VAL_ 2565918206 DCACAccryInv2PwrLmtedDTDCSdeCur 0 "No power limit for this reason" 1 "Power limited for this reason" 2 "Error" 3 "Not Available" ;
VAL_ 2565918206 DCACAccryInv2PwrLmtDTACSdeRMSCur 0 "No power limit for this reason" 1 "Power limited for this reason" 2 "Error" 3 "Not Available" ;
VAL_ 2565918206 DCACAccryInv2PwrLmtDTDCSdeVltgMn 0 "No power limit for this reason" 1 "Power limited for this reason" 2 "Error" 3 "Not Available" ;
VAL_ 2565918206 DCACAccssryInvert2FreqCmdBlwMin 0 "No frequency limit for this reason" 1 "Frequency limited for this reason" 2 "Error" 3 "Not Available" ;
VAL_ 2565918206 DCACAccryInv2FreqCmdExceedsMax 0 "No frequency limit for this reason" 1 "Frequency limited for this reason" 2 "Error" 3 "Not Available" ;
VAL_ 2565918206 DCACAccryInv2PwrLmtDTCtrllerTemp 0 "No power limit for this reason" 1 "Power limited for this reason" 2 "Error" 3 "Not Available" ;
VAL_ 2565918206 DCACAccryInv2PwrLmtDTElctrFlTemp 0 "No power limit for this reason" 1 "Power limited for this reason" 2 "Error" 3 "Not Available" ;
VAL_ 2565918206 DCACAccInv2PwrLmtDTPwrElctrsTmp 0 "No power limit for this reason" 1 "Power limited for this reason" 2 "Error" 3 "Not Available" ;
VAL_ 2565918206 DCACAccryInv2PwrLmtDTRateChgLmt 0 "No power limit for this reason" 1 "Power limited for this reason" 2 "Error" 3 "Not Available" ;
VAL_ 2565918206 DCACAccryInv2PwrLmtDTUndefndRsn 0 "No power limit for this reason" 1 "Power limited for this reason" 2 "Error" 3 "Not Available" ;
VAL_ 2364592382 EngCyl1ExcludeFrmCombustionRq 0 "Exclude from Combustion" 1 "Include for Combustion" 2 "Reserved" 3 "Not available/Do not care" ;
VAL_ 2364592382 EngCyl2ExcludeFrmCombustionRq 0 "Exclude from Combustion" 1 "Include for Combustion" 2 "Reserved" 3 "Not available/Do not care" ;
VAL_ 2364592382 EngCyl3ExcludeFrmCombustionRq 0 "Exclude from Combustion" 1 "Include for Combustion" 2 "Reserved" 3 "Not available/Do not care" ;
VAL_ 2364592382 EngCyl4ExcludeFrmCombustionRq 0 "Exclude from Combustion" 1 "Include for Combustion" 2 "Reserved" 3 "Not available/Do not care" ;
VAL_ 2364592382 EngCyl5ExcludeFrmCombustionRq 0 "Exclude from Combustion" 1 "Include for Combustion" 2 "Reserved" 3 "Not available/Do not care" ;
VAL_ 2364592382 EngCyl6ExcludeFrmCombustionRq 0 "Exclude from Combustion" 1 "Include for Combustion" 2 "Reserved" 3 "Not available/Do not care" ;
VAL_ 2364592382 EngCyl7ExcludeFrmCombustionRq 0 "Exclude from Combustion" 1 "Include for Combustion" 2 "Reserved" 3 "Not available/Do not care" ;
VAL_ 2364592382 EngCyl8ExcludeFrmCombustionRq 0 "Exclude from Combustion" 1 "Include for Combustion" 2 "Reserved" 3 "Not available/Do not care" ;
VAL_ 2364592382 EngCyl9ExcludeFrmCombustionRq 0 "Exclude from Combustion" 1 "Include for Combustion" 2 "Reserved" 3 "Not available/Do not care" ;
VAL_ 2364592382 EngCyl10ExcludeFrmCombustionRq 0 "Exclude from Combustion" 1 "Include for Combustion" 2 "Reserved" 3 "Not available/Do not care" ;
VAL_ 2364592382 EngCyl11ExcludeFrmCombustionRq 0 "Exclude from Combustion" 1 "Include for Combustion" 2 "Reserved" 3 "Not available/Do not care" ;
VAL_ 2364592382 EngCyl12ExcludeFrmCombustionRq 0 "Exclude from Combustion" 1 "Include for Combustion" 2 "Reserved" 3 "Not available/Do not care" ;
VAL_ 2364592382 EngCyl13ExcludeFrmCombustionRq 0 "Exclude from Combustion" 1 "Include for Combustion" 2 "Reserved" 3 "Not available/Do not care" ;
VAL_ 2364592382 EngCyl14ExcludeFrmCombustionRq 0 "Exclude from Combustion" 1 "Include for Combustion" 2 "Reserved" 3 "Not available/Do not care" ;
VAL_ 2364592382 EngCyl15ExcludeFrmCombustionRq 0 "Exclude from Combustion" 1 "Include for Combustion" 2 "Reserved" 3 "Not available/Do not care" ;
VAL_ 2364592382 EngCyl16ExcludeFrmCombustionRq 0 "Exclude from Combustion" 1 "Include for Combustion" 2 "Reserved" 3 "Not available/Do not care" ;
VAL_ 2364592382 EngCyl17ExcludeFrmCombustionRq 0 "Exclude from Combustion" 1 "Include for Combustion" 2 "Reserved" 3 "Not available/Do not care" ;
VAL_ 2364592382 EngCyl18ExcludeFrmCombustionRq 0 "Exclude from Combustion" 1 "Include for Combustion" 2 "Reserved" 3 "Not available/Do not care" ;
VAL_ 2364592382 EngCyl19ExcludeFrmCombustionRq 0 "Exclude from Combustion" 1 "Include for Combustion" 2 "Reserved" 3 "Not available/Do not care" ;
VAL_ 2364592382 EngCyl20ExcludeFrmCombustionRq 0 "Exclude from Combustion" 1 "Include for Combustion" 2 "Reserved" 3 "Not available/Do not care" ;
VAL_ 2364592382 EngCyl21ExcludeFrmCombustionRq 0 "Exclude from Combustion" 1 "Include for Combustion" 2 "Reserved" 3 "Not available/Do not care" ;
VAL_ 2364592382 EngCyl22ExcludeFrmCombustionRq 0 "Exclude from Combustion" 1 "Include for Combustion" 2 "Reserved" 3 "Not available/Do not care" ;
VAL_ 2364592382 EngCyl23ExcludeFrmCombustionRq 0 "Exclude from Combustion" 1 "Include for Combustion" 2 "Reserved" 3 "Not available/Do not care" ;
VAL_ 2364592382 EngCyl24ExcludeFrmCombustionRq 0 "Exclude from Combustion" 1 "Include for Combustion" 2 "Reserved" 3 "Not available/Do not care" ;
VAL_ 2364592638 EngCylHeadBypssActr1TempStat 0 "High Most severe" 1 "High Least severe" 2 "In Range" 3 "Low Least severe" 4 "Low Most severe" 5 "Not Defined" 6 "Error" 7 "Not available" ;
VAL_ 2364592638 EngCylHeadBypssActr1OpStatus 0 "Normal" 1 "Alarm" 2 "Alarm High Severity" 3 "Derate Active" 4 "Controlled Shutdown Active" 5 "Uncontrolled Shutdown Active" 6 "Calibration in Progress" 7 "Reserved for future assignment" 14 "Error" 15 "Not available" ;
VAL_ 2364592894 EngineIntakeAirSourceValve 0 "Off" 1 "On" 2 "Error" 3 "Not available" ;
VAL_ 2364593150 PredictiveCruiseControlState 0 "Disabled" 1 "Enabled" 2 "Enabled, but not functional due to vehicle position not available" 3 "Enabled, but not functional due to map position not available" 4 "Enabled, but not functional due to road grade info not available" 5 "Enabled, but not functional due to predicted path not available" 6 "Enabled, but not functional due to vehicle speed below speed threshold" 7 "Enabled, but not functional due to inhibited by driver" 8 "Enabled, but not functional due to self test" 9 "SAE Reserved" 14 "Error" 15 "Not Available" ;
VAL_ 2364593150 VehicleSpeedCtrlOverrideRequest 0 "No speed control override requested" 1 "Speed control override requested" 2 "Reserved" 3 "Don't care/take no action" ;
VAL_ 2364593150 PredictiveCruiseCtrlEventInRange 0 "No PCC event in range" 1 "PCC event in range" 2 "Error" 3 "Not available" ;
VAL_ 2364593150 PredictCrsCtrlSpeedEvntIndictr 0 "No speed event is active" 1 "Increased speed event is active" 2 "Decreased speed event is active" 3 "Not available" ;
VAL_ 2364593150 VehicleSpdCtrlOverrdEvntIndictr 0 "Speed Control event is not active" 1 "Speed Control event is active" 2 "Reserved" 3 "Not available" ;
VAL_ 2364593150 PredictCrsCtrlDrvlineDisengInhRq 0 "No Inhibit Request" 1 "Driveline Disengage Inhibit Request" 2 "Reserved" 3 "Don't care/take no action" ;
VAL_ 2565920510 DCACAccssryInverter1Dev1Status 0 "On" 1 "Off" 2 "Faulted On" 3 "Faulted Off" 4 "Reserved for SAE Assignment" 5 "Reserved for SAE Assignment" 6 "Error" 7 "Not Available" ;
VAL_ 2565920510 DCACAccssryInverter1Dev2Status 0 "On" 1 "Off" 2 "Faulted On" 3 "Faulted Off" 4 "Reserved for SAE Assignment" 5 "Reserved for SAE Assignment" 6 "Error" 7 "Not Available" ;
VAL_ 2565920510 DCACAccssryInvert1OperationalCmd 0 "Disable DC/AC Accessory Inverter Output" 1 "Enable DC/AC Accessory Inverter Output" 2 "Power down DC/AC Accessory Inverter Controller" 3 "Not Available" ;
VAL_ 2565920766 DCACAccssryInvert1OpalStatus 0 "Output Disabled" 1 "Output Enabled" 2 "Output Faulted On" 3 "Output Faulted Off" 4 "Normal Power Down in Process" 5 "Reserved" 6 "Error" 7 "Not Available" ;
VAL_ 2565920766 DCACAccssryInvert1LoadshedRq 0 "No Loadshed Requested" 1 "Loadshed Requested" 2 "Loadshed Requested, Shutdown Imminent" 3 "Don't Care/Take No Action" ;
VAL_ 2565920766 DCACAccessoryInverter1HVILStatus 0 "HVIL Closed" 1 "HVIL Open" 2 "Error" 3 "Not Available" ;
VAL_ 2565921534 DCACAccssryInverter2Dev1Status 0 "On" 1 "Off" 2 "Faulted On" 3 "Faulted Off" 4 "Reserved for SAE Assignment" 5 "Reserved for SAE Assignment" 6 "Error" 7 "Not Available" ;
VAL_ 2565921534 DCACAccssryInverter2Dev2Status 0 "On" 1 "Off" 2 "Faulted On" 3 "Faulted Off" 4 "Reserved for SAE Assignment" 5 "Reserved for SAE Assignment" 6 "Error" 7 "Not Available" ;
VAL_ 2565921534 DCACAccssryInvert2OperationalCmd 0 "Disable DC/AC Accessory Inverter Output" 1 "Enable DC/AC Accessory Inverter Output" 2 "Power down DC/AC Accessory Inverter Controller" 3 "Not Available" ;
VAL_ 2565921790 DCACAccssryInvert2OpalStatus 0 "Output Disabled" 1 "Output Enabled" 2 "Output Faulted On" 3 "Output Faulted Off" 4 "Normal Power Down in Process" 5 "Reserved" 6 "Error" 7 "Not Available" ;
VAL_ 2565921790 DCACAccssryInvert2LoadshedRq 0 "No Loadshed Requested" 1 "Loadshed Requested" 2 "Loadshed Requested, Shutdown Imminent" 3 "Don't Care/Take No Action" ;
VAL_ 2565921790 DCACAccessoryInverter2HVILStatus 0 "HVIL Closed" 1 "HVIL Open" 2 "Error" 3 "Not Available" ;
VAL_ 2565922558 DCACAccssryInverter3Dev1Status 0 "On" 1 "Off" 2 "Faulted On" 3 "Faulted Off" 4 "Reserved for SAE Assignment" 5 "Reserved for SAE Assignment" 6 "Error" 7 "Not Available" ;
VAL_ 2565922558 DCACAccssryInverter3Dev2Status 0 "On" 1 "Off" 2 "Faulted On" 3 "Faulted Off" 4 "Reserved for SAE Assignment" 5 "Reserved for SAE Assignment" 6 "Error" 7 "Not Available" ;
VAL_ 2565922558 DCACAccssryInvert3OperationalCmd 0 "Disable DC/AC Accessory Inverter Output" 1 "Enable DC/AC Accessory Inverter Output" 2 "Power down DC/AC Accessory Inverter Controller" 3 "Not Available" ;
VAL_ 2565922814 DCACAccssryInvert3OpalStatus 0 "Output Disabled" 1 "Output Enabled" 2 "Output Faulted On" 3 "Output Faulted Off" 4 "Normal Power Down in Process" 5 "Reserved" 6 "Error" 7 "Not Available" ;
VAL_ 2565922814 DCACAccssryInvert3LoadshedRq 0 "No Loadshed Requested" 1 "Loadshed Requested" 2 "Loadshed Requested, Shutdown Imminent" 3 "Don't Care/Take No Action" ;
VAL_ 2565922814 DCACAccessoryInverter3HVILStatus 0 "HVIL Closed" 1 "HVIL Open" 2 "Error" 3 "Not Available" ;
VAL_ 2565923582 DCACAccssryInverter4Dev1Status 0 "On" 1 "Off" 2 "Faulted On" 3 "Faulted Off" 4 "Reserved for SAE Assignment" 5 "Reserved for SAE Assignment" 6 "Error" 7 "Not Available" ;
VAL_ 2565923582 DCACAccssryInverter4Dev2Status 0 "On" 1 "Off" 2 "Faulted On" 3 "Faulted Off" 4 "Reserved for SAE Assignment" 5 "Reserved for SAE Assignment" 6 "Error" 7 "Not Available" ;
VAL_ 2565923582 DCACAccssryInvert4OperationalCmd 0 "Disable DC/AC Accessory Inverter Output" 1 "Enable DC/AC Accessory Inverter Output" 2 "Power down DC/AC Accessory Inverter Controller" 3 "Not Available" ;
VAL_ 2565923838 DCACAccssryInvert4OpalStatus 0 "Output Disabled" 1 "Output Enabled" 2 "Output Faulted On" 3 "Output Faulted Off" 4 "Normal Power Down in Process" 5 "Reserved" 6 "Error" 7 "Not Available" ;
VAL_ 2565923838 DCACAccssryInvert4LoadshedRq 0 "No Loadshed Requested" 1 "Loadshed Requested" 2 "Loadshed Requested, Shutdown Imminent" 3 "Don't Care/Take No Action" ;
VAL_ 2565923838 DCACAccessoryInverter4HVILStatus 0 "HVIL Closed" 1 "HVIL Open" 2 "Error" 3 "Not Available" ;
VAL_ 2565925374 Aftrtrtmnt1IntkGsSensor2PwrInRng 0 "Not in range" 1 "In range" 2 "Error" 3 "Not available" ;
VAL_ 2565925374 Aftrtrtmnt1IntkGsSnsr2AtTemp 0 "Not in range" 1 "In range" 2 "Error" 3 "Not available" ;
VAL_ 2565925374 EngineExhaust1NOx2ReadingStable 0 "Not stable" 1 "Stable" 2 "Error" 3 "Not available" ;
VAL_ 2565925374 Aft1IntkWdRngPrcntOxg2RdngStable 0 "Not stable" 1 "Stable" 2 "Error" 3 "Not available" ;
VAL_ 2565925374 Aftrtrtmnt1IntkGsSensor2HtrCtrl 0 "Automatic" 1 "Preheat 2" 2 "Preheat 1" 3 "Heater off" ;
VAL_ 2565925374 EngExhst1NOxSnsr2SelfDiagnssStat 0 "Diagnosis not active" 1 "NOx Sensor EEB1 Self-diagnosis active flag" 2 "NOx Sensor EEB1 Self-diagnosis Result Complete" 3 "NOx Sensor EEB1 Self-diagnosis aborted" 4 "NOx Sensor EEB1 Self-diagnosis not possible" 5 "Reserved" 7 "Not Supported" ;
VAL_ 2565925630 Aftrtrtmnt1OtltGsSensor2PwrInRng 0 "Not in range" 1 "In range" 2 "Error" 3 "Not available" ;
VAL_ 2565925630 Aftrtrtmnt1OtltGsSnsr2AtTemp 0 "Not in range" 1 "In range" 2 "Error" 3 "Not available" ;
VAL_ 2565925630 Aftrtrtmnt1OtltNOx2ReadingStable 0 "Not stable" 1 "Stable" 2 "Error" 3 "Not available" ;
VAL_ 2565925630 Aft1OtltWdRngPrcntOxg2RdngStable 0 "Not stable" 1 "Stable" 2 "Error" 3 "Not available" ;
VAL_ 2565925630 Aftrtrtmnt1OtltGsSensor2HtrCtrl 0 "Automatic" 1 "Preheat 2" 2 "Preheat 1" 3 "Heater off" ;
VAL_ 2565925630 Aft1OtltNOxSnsr2SelfDiagnssStat 0 "Diagnosis not active" 1 "NOx Sensor ATO1 Self-diagnosis active flag" 2 "NOx Sensor ATO1 Self-diagnosis Result Complete" 3 "NOx Sensor ATO1 Self-diagnosis aborted" 4 "NOx Sensor ATO1 Self-diagnosis not possible" 5 "Reserved" 7 "Not Supported" ;
VAL_ 2565925886 Aftrtrtmnt2IntkGsSensor2PwrInRng 0 "Not in range" 1 "In range" 2 "Error" 3 "Not available" ;
VAL_ 2565925886 Aftrtrtmnt2IntkGsSnsr2AtTemp 0 "Not in range" 1 "In range" 2 "Error" 3 "Not available" ;
VAL_ 2565925886 EngineExhaust2NOx2ReadingStable 0 "Not stable" 1 "Stable" 2 "Error" 3 "Not available" ;
VAL_ 2565925886 Aft2IntkWdRngPrcntOxg2RdngStable 0 "Not stable" 1 "Stable" 2 "Error" 3 "Not available" ;
VAL_ 2565925886 Aftrtrtmnt2IntkGsSensor2HtrCtrl 0 "Automatic" 1 "Preheat 2" 2 "Preheat 1" 3 "Heater off" ;
VAL_ 2565925886 EngExhst2IntkNOxSnsr2SelfDiagSt 0 "Diagnosis not active" 1 "NOx Sensor EEB2 Self-diagnosis active flag" 2 "NOx Sensor EEB2 Self-diagnosis Result Complete" 3 "NOx Sensor EEB2 Self-diagnosis aborted" 4 "NOx Sensor EEB2 Self-diagnosis not possible" 5 "Reserved" 7 "Not Supported" ;
VAL_ 2565926142 Aftrtrtmnt2OtltGsSensor2PwrInRng 0 "Not in range" 1 "In range" 2 "Error" 3 "Not available" ;
VAL_ 2565926142 Aftrtrtmnt2OtltGsSnsr2AtTemp 0 "Not in range" 1 "In range" 2 "Error" 3 "Not available" ;
VAL_ 2565926142 Aftrtrtmnt2OtltNOx2ReadingStable 0 "Not stable" 1 "Stable" 2 "Error" 3 "Not available" ;
VAL_ 2565926142 Aft2OtltWdRngPrcntOxg2RdngStable 0 "Not stable" 1 "Stable" 2 "Error" 3 "Not available" ;
VAL_ 2565926142 Aftrtrtmnt2OtltGsSensor2HtrCtrl 0 "Automatic" 1 "Preheat 2" 2 "Preheat 1" 3 "Heater off" ;
VAL_ 2565926142 Aft2OtltNOxSnsr2SelfDiagnssStat 0 "Diagnosis not active" 1 "NOx Sensor ATO2 Self-diagnosis active flag" 2 "NOx Sensor ATO2 Self-diagnosis Result Complete" 3 "NOx Sensor ATO2 Self-diagnosis aborted" 4 "NOx Sensor ATO2 Self-diagnosis not possible" 5 "Reserved" 7 "Not Supported" ;
VAL_ 2431708670 EngineStartRequest 0 "Start not requested" 1 "Start requested, operator type" 2 "Start requested, automatic type" 3 "Not available" ;
VAL_ 2431708670 EngineStartConsent 0 "No consent" 1 "Consent to operator-requested start only" 2 "Consent to automatic start only" 3 "Consent to both, operator-requested and automatic start" 4 "Reserved" 7 "Not available" ;
VAL_ 2431708670 TrnsmShftSlctorRqedVhclDirection 0 "No direction selected - Park" 1 "No direction selected - Neutral" 2 "Forward direction selected" 3 "Reverse direction selected" 4 "4 SAE Reserved" 6 "Error" 7 "Not supported" ;
VAL_ 2431708670 EngineStartAbortRequest 0 "Abort not requested" 1 "Abort requested" 2 "Reserved" 3 "Don't care / Take no action" ;
VAL_ 2431708670 EngineStarter1Feedback 0 "Starter not commanded" 1 "Starter command latched, starter active" 2 "Starter command unlatched, start completed" 3 "Starter command unlatched, start abort command received from arbitrator" 4 "Starter command unlatched, start aborted by starter controller" 5 "Reserved" 7 "Not available" ;
VAL_ 2431708670 EngineStarter2Feedback 0 "Starter not commanded" 1 "Starter command latched, starter active" 2 "Starter command unlatched, start completed" 3 "Starter command unlatched, start abort command received from arbitrator" 4 "Starter command unlatched, start aborted by starter controller" 5 "Reserved" 7 "Not available" ;
VAL_ 2431710718 EngineStartControlMessageRate 0 "Once every 20 ms" 1 "Once every 250 ms or on change but no faster than 20 ms" 2 "Reserved" 3 "Not available" ;
VAL_ 2431710718 EngineStarterCommand 0 "Command not active" 1 "Command active for starter 1" 2 "Command active for starter 2" 3 "Command withdrawn - abort engine start" 4 "Reserved" 7 "Don't care / Take no action" ;
VAL_ 2431710718 EngineStartRequestLatchStatus 0 "Start request not received" 1 "Start request latched - waiting for consent" 2 "Start request latched - consent confirmed, starter commanded" 3 "Start request unlatched - start completed" 4 "Start request unlatched - consent not established within allowed time" 5 "Start request unlatched - start aborted due to abort request" 6 "Start request unlatched - start could not be completed because the starter command was not successful" 7 "Reserved" 15 "Not available" ;
VAL_ 2431710718 OperatorEngineStartConsntSummary 0 "No consent" 1 "Consent" 2 "Error" 3 "Not available" ;
VAL_ 2431710718 AutoEngineStartConsentSummary 0 "No consent" 1 "Consent" 2 "Error" 3 "Not available" ;
VAL_ 2364604414 FrontHitchRollLimitState 0 "Not limited" 1 "Operator limited/controlled" 2 "Limited High" 3 "Limited Low" 4 "Reserved" 5 "Reserved" 6 "Non recoverable fault" 7 "Not available" ;
VAL_ 2364604414 FrontHitchRollExitReasonCode 0 "No reason/all clear" 1 "Required level of operator presence/awareness not detected" 2 "Implement released control of function" 3 "Operator override of function" 4 "Operator control not in valid position" 5 "Remote command timeout" 6 "Remote command out of range/invalid" 7 "Function not calibrated" 8 "Operator control fault" 9 "Function fault" 10 "Reserved" 20 "Hydraulic oil level too low" 21 "Hitch locked out" 22 "Reserved" 49 "Manufacturer specific" 62 "Error" 63 "Not available" ;
VAL_ 2364604414 FrontHitchPitchLimitState 0 "Not limited" 1 "Operator limited/controlled" 2 "Limited High" 3 "Limited Low" 4 "Reserved" 5 "Reserved" 6 "Non recoverable fault" 7 "Not available" ;
VAL_ 2364604414 FrontHitchPitchExitReasonCode 0 "No reason/all clear" 1 "Required level of operator presence/awareness not detected" 2 "Implement released control of function" 3 "Operator override of function" 4 "Operator control not in valid position" 5 "Remote command timeout" 6 "Remote command out of range/invalid" 7 "Function not calibrated" 8 "Operator control fault" 9 "Function fault" 10 "Reserved" 20 "Hydraulic oil level too low" 21 "Hitch locked out" 22 "Reserved" 49 "Manufacturer specific" 62 "Error" 63 "Not available" ;
VAL_ 2364604926 RearHitchRollLimitState 0 "Not limited" 1 "Operator limited/controlled" 2 "Limited High" 3 "Limited Low" 4 "Reserved" 5 "Reserved" 6 "Non recoverable fault" 7 "Not available" ;
VAL_ 2364604926 RearHitchRollExitReasonCode 0 "No reason/all clear" 1 "Required level of operator presence/awareness not detected" 2 "Implement released control of function" 3 "Operator override of function" 4 "Operator control not in valid position" 5 "Remote command timeout" 6 "Remote command out of range/invalid" 7 "Function not calibrated" 8 "Operator control fault" 9 "Function fault" 10 "Reserved" 20 "Hydraulic oil level too low" 21 "Hitch locked out" 22 "Reserved" 49 "Manufacturer specific" 62 "Error" 63 "Not available" ;
VAL_ 2364604926 RearHitchPitchLimitState 0 "Not limited" 1 "Operator limited/controlled" 2 "Limited High" 3 "Limited Low" 4 "Reserved" 5 "Reserved" 6 "Non recoverable fault" 7 "Not available" ;
VAL_ 2364604926 RearHitchPitchExitReasonCode 0 "No reason/all clear" 1 "Required level of operator presence/awareness not detected" 2 "Implement released control of function" 3 "Operator override of function" 4 "Operator control not in valid position" 5 "Remote command timeout" 6 "Remote command out of range/invalid" 7 "Function not calibrated" 8 "Operator control fault" 9 "Function fault" 10 "Reserved" 20 "Hydraulic oil level too low" 21 "Hitch locked out" 22 "Reserved" 49 "Manufacturer specific" 62 "Error" 63 "Not available" ;
VAL_ 2364606718 HVES1Module1OperationalStatus 0 "Not Operational" 1 "Operational" 2 "Error" 3 "Not Available" ;
VAL_ 2364606718 HVES1Module2OperationalStatus 0 "Not Operational" 1 "Operational" 2 "Error" 3 "Not Available" ;
VAL_ 2364606718 HVES1Module3OperationalStatus 0 "Not Operational" 1 "Operational" 2 "Error" 3 "Not Available" ;
VAL_ 2364606718 HVES1Module4OperationalStatus 0 "Not Operational" 1 "Operational" 2 "Error" 3 "Not Available" ;
VAL_ 2364606718 HVES1Module5OperationalStatus 0 "Not Operational" 1 "Operational" 2 "Error" 3 "Not Available" ;
VAL_ 2364606718 HVES1Module6OperationalStatus 0 "Not Operational" 1 "Operational" 2 "Error" 3 "Not Available" ;
VAL_ 2364606718 HVES1Module7OperationalStatus 0 "Not Operational" 1 "Operational" 2 "Error" 3 "Not Available" ;
VAL_ 2364606718 HVES1Module8OperationalStatus 0 "Not Operational" 1 "Operational" 2 "Error" 3 "Not Available" ;
VAL_ 2364606718 HVES1Module9OperationalStatus 0 "Not Operational" 1 "Operational" 2 "Error" 3 "Not Available" ;
VAL_ 2364606718 HVES1Module10OperationalStatus 0 "Not Operational" 1 "Operational" 2 "Error" 3 "Not Available" ;
VAL_ 2364606718 HVES1Module11OperationalStatus 0 "Not Operational" 1 "Operational" 2 "Error" 3 "Not Available" ;
VAL_ 2364606718 HVES1Module12OperationalStatus 0 "Not Operational" 1 "Operational" 2 "Error" 3 "Not Available" ;
VAL_ 2364606718 HVES1Module13OperationalStatus 0 "Not Operational" 1 "Operational" 2 "Error" 3 "Not Available" ;
VAL_ 2364606718 HVES1Module14OperationalStatus 0 "Not Operational" 1 "Operational" 2 "Error" 3 "Not Available" ;
VAL_ 2364606718 HVES1Module15OperationalStatus 0 "Not Operational" 1 "Operational" 2 "Error" 3 "Not Available" ;
VAL_ 2364606718 HVES1Module16OperationalStatus 0 "Not Operational" 1 "Operational" 2 "Error" 3 "Not Available" ;
VAL_ 2364606974 HVES1ThermalMangmntSystemHtrStat 0 "Heater Off" 1 "Heater On" 2 "Error" 3 "Not Available" ;
VAL_ 2364606974 HVESSThermalMangmntSysHVILStat 0 "HVIL Closed" 1 "HVIL Open" 2 "Error" 3 "Not Available" ;
VAL_ 2364606974 HVES1ThermalManagementSystemMode 0 "Off" 1 "Circulating" 2 "Cooling" 3 "Heating" 4 "Drying" 5 "Reserved" 14 "Faulted" 15 "Not Available" ;
VAL_ 2297499902 BrakePedalSwitch2 0 "Brake pedal released" 1 "Brake pedal depressed" 2 "Error" 3 "Not Available" ;
VAL_ 2364609278 DCDC1OperationalCommand 0 "Disable" 1 "Operate in standby mode" 2 "Operate in buck mode" 3 "Operate in boost mode" 4 "Reserved" 15 "Don't care/ Take No Action" ;
VAL_ 2364609534 DCDC1OperationalStatus 0 "Disabled" 1 "Initialization in process" 2 "Operational - Standby" 3 "Operational - Buck mode" 4 "Operational - Boost mode" 5 "Normal power down in process" 6 "Disabled due to malfunction or protection" 7 "Reserved" 13 "Manufacturer assignable state" 14 "Error" 15 "Not Available" ;
VAL_ 2364609534 DCDC1HVILStatus 0 "HVIL Closed" 1 "HVIL Open" 2 "Error" 3 "Not Available" ;
VAL_ 2364609534 DCDC1LoadshedRequest 0 "No Loadshed Requested" 1 "Loadshed Requested" 2 "Loadshed Requested, Shutdown Imminent" 3 "Don't Care/Take No Action" ;
VAL_ 2364609534 DCDC1PowerLimitDueToHighSideCurr 0 "No power limit for this reason" 1 "Power limited for this reason" 2 "Error" 3 "Not Available" ;
VAL_ 2364609534 DCDC1PowerLimitDueToLowSideCurr 0 "No power limit for this reason" 1 "Power limited for this reason" 2 "Error" 3 "Not Available" ;
VAL_ 2364609534 DCDC1PowerLmtDTHghSideVoltageMin 0 "No power limit for this reason" 1 "Power limited for this reason" 2 "Error" 3 "Not Available" ;
VAL_ 2364609534 DCDC1PowerLmtDTHghSideVoltageMax 0 "No power limit for this reason" 1 "Power limited for this reason" 2 "Error" 3 "Not Available" ;
VAL_ 2364609534 DCDC1PowerLmtDTLowSideVoltageMin 0 "No power limit for this reason" 1 "Power limited for this reason" 2 "Error" 3 "Not Available" ;
VAL_ 2364609534 DCDC1PowerLmtDTLowSideVoltageMax 0 "No power limit for this reason" 1 "Power limited for this reason" 2 "Error" 3 "Not Available" ;
VAL_ 2364609534 DCDC1PowerLimitDTCnvTemperature 0 "No power limit for this reason" 1 "Power limited for this reason" 2 "Error" 3 "Not Available" ;
VAL_ 2364609534 DCDC1PwrLmtDTElctrncFilterTemp 0 "No power limit for this reason" 1 "Power limited for this reason" 2 "Error" 3 "Not Available" ;
VAL_ 2364609534 DCDC1PwrLmtDTPwrElctrncsTemp 0 "No power limit for this reason" 1 "Power limited for this reason" 2 "Error" 3 "Not Available" ;
VAL_ 2364609534 DCDC1PwrLmtDTSLIBattTerminalVltg 0 "No power limit for this reason" 1 "Power limited for this reason" 2 "Error" 3 "Not Available" ;
VAL_ 2364609534 DCDC1PwrLmtDTSLIBattTerminalCurr 0 "No power limit for this reason" 1 "Power limited for this reason" 2 "Error" 3 "Not Available" ;
VAL_ 2364609534 DCDC1PwrLmtDTSLIBattTerminalTemp 0 "No power limit for this reason" 1 "Power limited for this reason" 2 "Error" 3 "Not Available" ;
VAL_ 2364609534 DCDC1PowerLimitDTUndefinedReason 0 "No power limit for this reason" 1 "Power limited for this reason" 2 "Error" 3 "Not Available" ;
VAL_ 2431719166 WellStimulationPmpCavitationStat 0 "No Cavitation" 1 "Low" 2 "Medium" 3 "High" 4 "Reserved" 5 "Reserved" 6 "Error" 7 "Not Available" ;
VAL_ 2431719166 WellStimultnPmpFldEndValveLeak 0 "No Leak Detected" 1 "Leak Detected" 2 "Error" 3 "Not Available" ;
VAL_ 2364610814 DCDC2OperationalCommand 0 "Disable" 1 "Operate in standby mode" 2 "Operate in buck mode" 3 "Operate in boost mode" 4 "Power down DC/DC Converter" 5 "Reserved" 6 "Reserved" 7 "Reserved" 8 "Reserved" 9 "Reserved" 10 "Reserved" 11 "Reserved" 12 "Reserved" 13 "Reserved" 15 "Don't care/ Take No Action" ;
VAL_ 2364611070 DCDC2OperationalStatus 0 "Disabled" 1 "Initialization in process" 2 "Operational - Standby" 3 "Operational - Buck mode" 4 "Operational - Boost mode" 5 "Normal power down in process" 6 "Disabled due to malfunction or protection" 7 "Reserved" 8 "Reserved" 9 "Reserved" 10 "Reserved" 11 "Reserved" 12 "Reserved" 13 "Manufacturer assignable state" 14 "Error" 15 "Not Available" ;
VAL_ 2364611070 DCDC2HVILStatus 0 "HVIL Closed" 1 "HVIL Open" 2 "Error" 3 "Not Available" ;
VAL_ 2364611070 DCDC2LoadshedRequest 0 "No Loadshed Requested" 1 "Loadshed Requested" 2 "Loadshed Requested, Shutdown Imminent" 3 "Don't Care/Take No Action" ;
VAL_ 2364611070 DCDC2PowerLimitDueToHighSideCurr 0 "No power limit for this reason" 1 "Power limited for this reason" 2 "Error" 3 "Not Available" ;
VAL_ 2364611070 DCDC2PowerLimitDueToLowSideCurr 0 "No power limit for this reason" 1 "Power limited for this reason" 2 "Error" 3 "Not Available" ;
VAL_ 2364611070 DCDC2PowerLmtDTHghSideVoltageMin 0 "No power limit for this reason" 1 "Power limited for this reason" 2 "Error" 3 "Not Available" ;
VAL_ 2364611070 DCDC2PowerLmtDTHghSideVoltageMax 0 "No power limit for this reason" 1 "Power limited for this reason" 2 "Error" 3 "Not Available" ;
VAL_ 2364611070 DCDC2PowerLmtDTLowSideVoltageMin 0 "No power limit for this reason" 1 "Power limited for this reason" 2 "Error" 3 "Not Available" ;
VAL_ 2364611070 DCDC2PowerLmtDTLowSideVoltageMax 0 "No power limit for this reason" 1 "Power limited for this reason" 2 "Error" 3 "Not Available" ;
VAL_ 2364611070 DCDC2PowerLimitDTCnvTemperature 0 "No power limit for this reason" 1 "Power limited for this reason" 2 "Error" 3 "Not Available" ;
VAL_ 2364611070 DCDC2PwrLmtDTElctrncFltrTemp 0 "No power limit for this reason" 1 "Power limited for this reason" 2 "Error" 3 "Not Available" ;
VAL_ 2364611070 DCDC2PwrLmtDTPwrElctrncsTemp 0 "No power limit for this reason" 1 "Power limited for this reason" 2 "Error" 3 "Not Available" ;
VAL_ 2364611070 DCDC2PwrLmtDTSLIBattryTermnlVltg 0 "No power limit for this reason" 1 "Power limited for this reason" 2 "Error" 3 "Not Available" ;
VAL_ 2364611070 DCDC2PwrLmtDTSLIBattryTermnlCurr 0 "No power limit for this reason" 1 "Power limited for this reason" 2 "Error" 3 "Not Available" ;
VAL_ 2364611070 DCDC2PwrLmtDTSLIBattryTermnlTemp 0 "No power limit for this reason" 1 "Power limited for this reason" 2 "Error" 3 "Not Available" ;
VAL_ 2364611070 DCDC2PowerLimitDTUndefinedReason 0 "No power limit for this reason" 1 "Power limited for this reason" 2 "Error" 3 "Not Available" ;
VAL_ 2364612094 DCDC3OperationalCommand 0 "Disable" 1 "Operate in standby mode" 2 "Operate in buck mode" 3 "Operate in boost mode" 4 "Power down DC/DC Converter" 5 "Reserved" 6 "Reserved" 7 "Reserved" 8 "Reserved" 9 "Reserved" 10 "Reserved" 11 "Reserved" 12 "Reserved" 13 "Reserved" 15 "Don't care/ Take No Action" ;
VAL_ 2364612350 DCDC3OperationalStatus 0 "Disabled" 1 "Initialization in process" 2 "Operational - Standby" 3 "Operational - Buck mode" 4 "Operational - Boost mode" 5 "Normal power down in process" 6 "Disabled due to malfunction or protection" 7 "Reserved" 8 "Reserved" 9 "Reserved" 10 "Reserved" 11 "Reserved" 12 "Reserved" 13 "Manufacturer assignable state" 14 "Error" 15 "Not Available" ;
VAL_ 2364612350 DCDC3HVILStatus 0 "HVIL Closed" 1 "HVIL Open" 2 "Error" 3 "Not Available" ;
VAL_ 2364612350 DCDC3LoadshedRequest 0 "No Loadshed Requested" 1 "Loadshed Requested" 2 "Loadshed Requested, Shutdown Imminent" 3 "Don't Care/Take No Action" ;
VAL_ 2364612350 DCDC3PowerLimitDueToHighSideCurr 0 "No power limit for this reason" 1 "Power limited for this reason" 2 "Error" 3 "Not Available" ;
VAL_ 2364612350 DCDC3PowerLimitDueToLowSideCurr 0 "No power limit for this reason" 1 "Power limited for this reason" 2 "Error" 3 "Not Available" ;
VAL_ 2364612350 DCDC3PowerLmtDTHghSideVoltageMin 0 "No power limit for this reason" 1 "Power limited for this reason" 2 "Error" 3 "Not Available" ;
VAL_ 2364612350 DCDC3PowerLmtDTHghSideVoltageMax 0 "No power limit for this reason" 1 "Power limited for this reason" 2 "Error" 3 "Not Available" ;
VAL_ 2364612350 DCDC3PowerLmtDTLowSideVoltageMin 0 "No power limit for this reason" 1 "Power limited for this reason" 2 "Error" 3 "Not Available" ;
VAL_ 2364612350 DCDC3PowerLmtDTLowSideVoltageMax 0 "No power limit for this reason" 1 "Power limited for this reason" 2 "Error" 3 "Not Available" ;
VAL_ 2364612350 DCDC3PowerLimitDTCnvTemperature 0 "No power limit for this reason" 1 "Power limited for this reason" 2 "Error" 3 "Not Available" ;
VAL_ 2364612350 DCDC3PwrLmtDTElctrncFltrTemp 0 "No power limit for this reason" 1 "Power limited for this reason" 2 "Error" 3 "Not Available" ;
VAL_ 2364612350 DCDC3PwrLmtDTPwrElctrncsTemp 0 "No power limit for this reason" 1 "Power limited for this reason" 2 "Error" 3 "Not Available" ;
VAL_ 2364612350 DCDC3PwrLmtDTSLIBattryTermnlVltg 0 "No power limit for this reason" 1 "Power limited for this reason" 2 "Error" 3 "Not Available" ;
VAL_ 2364612350 DCDC3PwrLmtDTSLIBattryTermnlCurr 0 "No power limit for this reason" 1 "Power limited for this reason" 2 "Error" 3 "Not Available" ;
VAL_ 2364612350 DCDC3PwrLmtDTSLIBattryTermnlTemp 0 "No power limit for this reason" 1 "Power limited for this reason" 2 "Error" 3 "Not Available" ;
VAL_ 2364612350 DCDC3PowerLimitDTUndefinedReason 0 "No power limit for this reason" 1 "Power limited for this reason" 2 "Error" 3 "Not Available" ;
VAL_ 2364613374 DCDC4OperationalCommand 0 "Disable" 1 "Operate in standby mode" 2 "Operate in buck mode" 3 "Operate in boost mode" 4 "Power down DC/DC Converter" 5 "Reserved" 6 "Reserved" 7 "Reserved" 8 "Reserved" 9 "Reserved" 10 "Reserved" 11 "Reserved" 12 "Reserved" 13 "Reserved" 15 "Don't care/ Take No Action" ;
VAL_ 2364613630 DCDC4OperationalStatus 0 "Disabled" 1 "Initialization in process" 2 "Operational - Standby" 3 "Operational - Buck mode" 4 "Operational - Boost mode" 5 "Normal power down in process" 6 "Disabled due to malfunction or protection" 7 "Reserved" 8 "Reserved" 9 "Reserved" 10 "Reserved" 11 "Reserved" 12 "Reserved" 13 "Manufacturer assignable state" 14 "Error" 15 "Not Available" ;
VAL_ 2364613630 DCDC4HVILStatus 0 "HVIL Closed" 1 "HVIL Open" 2 "Error" 3 "Not Available" ;
VAL_ 2364613630 DCDC4LoadshedRequest 0 "No Loadshed Requested" 1 "Loadshed Requested" 2 "Loadshed Requested, Shutdown Imminent" 3 "Don't Care/Take No Action" ;
VAL_ 2364613630 DCDC4PowerLimitDueToHighSideCurr 0 "No power limit for this reason" 1 "Power limited for this reason" 2 "Error" 3 "Not Available" ;
VAL_ 2364613630 DCDC4PowerLimitDueToLowSideCurr 0 "No power limit for this reason" 1 "Power limited for this reason" 2 "Error" 3 "Not Available" ;
VAL_ 2364613630 DCDC4PowerLmtDTHghSideVoltageMin 0 "No power limit for this reason" 1 "Power limited for this reason" 2 "Error" 3 "Not Available" ;
VAL_ 2364613630 DCDC4PowerLmtDTHghSideVoltageMax 0 "No power limit for this reason" 1 "Power limited for this reason" 2 "Error" 3 "Not Available" ;
VAL_ 2364613630 DCDC4PowerLmtDTLowSideVoltageMin 0 "No power limit for this reason" 1 "Power limited for this reason" 2 "Error" 3 "Not Available" ;
VAL_ 2364613630 DCDC4PowerLmtDTLowSideVoltageMax 0 "No power limit for this reason" 1 "Power limited for this reason" 2 "Error" 3 "Not Available" ;
VAL_ 2364613630 DCDC4PowerLimitDTCnvTemperature 0 "No power limit for this reason" 1 "Power limited for this reason" 2 "Error" 3 "Not Available" ;
VAL_ 2364613630 DCDC4PwrLmtDTElctrncFltrTemp 0 "No power limit for this reason" 1 "Power limited for this reason" 2 "Error" 3 "Not Available" ;
VAL_ 2364613630 DCDC4PwrLmtDTPwrElctrncsTemp 0 "No power limit for this reason" 1 "Power limited for this reason" 2 "Error" 3 "Not Available" ;
VAL_ 2364613630 DCDC4PwrLmtDTSLIBattryTermnlVltg 0 "No power limit for this reason" 1 "Power limited for this reason" 2 "Error" 3 "Not Available" ;
VAL_ 2364613630 DCDC4PwrLmtDTSLIBattryTermnlCurr 0 "No power limit for this reason" 1 "Power limited for this reason" 2 "Error" 3 "Not Available" ;
VAL_ 2364613630 DCDC4PwrLmtDTSLIBattryTermnlTemp 0 "No power limit for this reason" 1 "Power limited for this reason" 2 "Error" 3 "Not Available" ;
VAL_ 2364613630 DCDC4PowerLimitDTUndefinedReason 0 "No power limit for this reason" 1 "Power limited for this reason" 2 "Error" 3 "Not Available" ;
VAL_ 2364614654 GradeThresholdIndicator1 0 "Current grade does not exceed the threshold" 1 "Current grade is equal to or exceeds the threshold" 2 "Error" 3 "Not Available" ;
VAL_ 2364614654 GradeThresholdIndicator2 0 "Current grade does not exceed the threshold" 1 "Current grade is equal to or exceeds the threshold" 2 "Error" 3 "Not Available" ;
VAL_ 2364614654 GradeThresholdIndicator3 0 "Current grade does not exceed the threshold" 1 "Current grade is equal to or exceeds the threshold" 2 "Error" 3 "Not Available" ;
VAL_ 2364614654 GradeThresholdIndicator4 0 "Current grade does not exceed the threshold" 1 "Current grade is equal to or exceeds the threshold" 2 "Error" 3 "Not Available" ;
VAL_ 2364614654 GradeThresholdIndicator5 0 "Current grade does not exceed the threshold" 1 "Current grade is equal to or exceeds the threshold" 2 "Error" 3 "Not Available" ;
VAL_ 2364614654 GradeThresholdIndicator6 0 "Current grade does not exceed the threshold" 1 "Current grade is equal to or exceeds the threshold" 2 "Error" 3 "Not Available" ;
VAL_ 2565942014 DCACAccryInv3PwrLmtedDTDCSdeCur 0 "No power limit for this reason" 1 "Power limited for this reason" 2 "Error" 3 "Not Available" ;
VAL_ 2565942014 DCACAccryInv3PwrLmtDTACSdeRMSCur 0 "No power limit for this reason" 1 "Power limited for this reason" 2 "Error" 3 "Not Available" ;
VAL_ 2565942014 DCACAccryInv3PwrLmtDTDCSdeVltgMn 0 "No power limit for this reason" 1 "Power limited for this reason" 2 "Error" 3 "Not Available" ;
VAL_ 2565942014 DCACAccssryInvert3FreqCmdBlwMin 0 "No frequency limit for this reason" 1 "Frequency limited for this reason" 2 "Error" 3 "Not Available" ;
VAL_ 2565942014 DCACAccryInv3FreqCmdExceedsMax 0 "No frequency limit for this reason" 1 "Frequency limited for this reason" 2 "Error" 3 "Not Available" ;
VAL_ 2565942014 DCACAccryInv3PwrLmtDTCtrllerTemp 0 "No power limit for this reason" 1 "Power limited for this reason" 2 "Error" 3 "Not Available" ;
VAL_ 2565942014 DCACAccryInv3PwrLmtDTElctrFlTemp 0 "No power limit for this reason" 1 "Power limited for this reason" 2 "Error" 3 "Not Available" ;
VAL_ 2565942014 DCACAccInv3PwrLmtDTPwrElctrsTmp 0 "No power limit for this reason" 1 "Power limited for this reason" 2 "Error" 3 "Not Available" ;
VAL_ 2565942014 DCACAccryInv3PwrLmtDTRateChgLmt 0 "No power limit for this reason" 1 "Power limited for this reason" 2 "Error" 3 "Not Available" ;
VAL_ 2565942014 DCACAccryInv3PwrLmtDTUndefndRsn 0 "No power limit for this reason" 1 "Power limited for this reason" 2 "Error" 3 "Not Available" ;
VAL_ 2565942782 DCACAccryInv4PwrLmtedDTDCSdeCur 0 "No power limit for this reason" 1 "Power limited for this reason" 2 "Error" 3 "Not Available" ;
VAL_ 2565942782 DCACAccryInv4PwrLmtDTACSdeRMSCur 0 "No power limit for this reason" 1 "Power limited for this reason" 2 "Error" 3 "Not Available" ;
VAL_ 2565942782 DCACAccryInv4PwrLmtDTDCSdeVltgMn 0 "No power limit for this reason" 1 "Power limited for this reason" 2 "Error" 3 "Not Available" ;
VAL_ 2565942782 DCACAccssryInvert4FreqCmdBlwMin 0 "No frequency limit for this reason" 1 "Frequency limited for this reason" 2 "Error" 3 "Not Available" ;
VAL_ 2565942782 DCACAccryInv4FreqCmdExceedsMax 0 "No frequency limit for this reason" 1 "Frequency limited for this reason" 2 "Error" 3 "Not Available" ;
VAL_ 2565942782 DCACAccryInv4PwrLmtDTCtrllerTemp 0 "No power limit for this reason" 1 "Power limited for this reason" 2 "Error" 3 "Not Available" ;
VAL_ 2565942782 DCACAccryInv4PwrLmtDTElctrFlTemp 0 "No power limit for this reason" 1 "Power limited for this reason" 2 "Error" 3 "Not Available" ;
VAL_ 2565942782 DCACAccInv4PwrLmtDTPwrElctrsTmp 0 "No power limit for this reason" 1 "Power limited for this reason" 2 "Error" 3 "Not Available" ;
VAL_ 2565942782 DCACAccryInv4PwrLmtDTRateChgLmt 0 "No power limit for this reason" 1 "Power limited for this reason" 2 "Error" 3 "Not Available" ;
VAL_ 2565942782 DCACAccryInv4PwrLmtDTUndefndRsn 0 "No power limit for this reason" 1 "Power limited for this reason" 2 "Error" 3 "Not Available" ;
VAL_ 2565943038 DCACAccssryInverter5Dev1Status 0 "On" 1 "Off" 2 "Faulted On" 3 "Faulted Off" 4 "Reserved for SAE Assignment" 5 "Reserved for SAE Assignment" 6 "Error" 7 "Not Available" ;
VAL_ 2565943038 DCACAccssryInverter5Dev2Status 0 "On" 1 "Off" 2 "Faulted On" 3 "Faulted Off" 4 "Reserved for SAE Assignment" 5 "Reserved for SAE Assignment" 6 "Error" 7 "Not Available" ;
VAL_ 2565943038 DCACAccssryInvert5OperationalCmd 0 "Disable DC/AC Accessory Inverter Output" 1 "Enable DC/AC Accessory Inverter Output" 2 "Power down DC/AC Accessory Inverter Controller" 3 "Not Available" ;
VAL_ 2565943294 DCACAccssryInvert5OpalStatus 0 "Output Disabled" 1 "Output Enabled" 2 "Output Faulted On" 3 "Output Faulted Off" 4 "Normal Power Down in Process" 5 "Reserved" 6 "Error" 7 "Not Available" ;
VAL_ 2565943294 DCACAccssryInvert5LoadshedRq 0 "No Loadshed Requested" 1 "Loadshed Requested" 2 "Loadshed Requested, Shutdown Imminent" 3 "Don't Care/Take No Action" ;
VAL_ 2565943294 DCACAccessoryInverter5HVILStatus 0 "HVIL Closed" 1 "HVIL Open" 2 "Error" 3 "Not Available" ;
VAL_ 2565944062 DCACAccryInv5PwrLmtedDTDCSdeCur 0 "No power limit for this reason" 1 "Power limited for this reason" 2 "Error" 3 "Not Available" ;
VAL_ 2565944062 DCACAccryInv5PwrLmtDTACSdeRMSCur 0 "No power limit for this reason" 1 "Power limited for this reason" 2 "Error" 3 "Not Available" ;
VAL_ 2565944062 DCACAccryInv5PwrLmtDTDCSdeVltgMn 0 "No power limit for this reason" 1 "Power limited for this reason" 2 "Error" 3 "Not Available" ;
VAL_ 2565944062 DCACAccssryInvert5FreqCmdBlwMin 0 "No frequency limit for this reason" 1 "Frequency limited for this reason" 2 "Error" 3 "Not Available" ;
VAL_ 2565944062 DCACAccryInv5FreqCmdExceedsMax 0 "No frequency limit for this reason" 1 "Frequency limited for this reason" 2 "Error" 3 "Not Available" ;
VAL_ 2565944062 DCACAccryInv5PwrLmtDTCtrllerTemp 0 "No power limit for this reason" 1 "Power limited for this reason" 2 "Error" 3 "Not Available" ;
VAL_ 2565944062 DCACAccryInv5PwrLmtDTElctrFlTemp 0 "No power limit for this reason" 1 "Power limited for this reason" 2 "Error" 3 "Not Available" ;
VAL_ 2565944062 DCACAccInv5PwrLmtDTPwrElctrsTmp 0 "No power limit for this reason" 1 "Power limited for this reason" 2 "Error" 3 "Not Available" ;
VAL_ 2565944062 DCACAccryInv5PwrLmtDTRateChgLmt 0 "No power limit for this reason" 1 "Power limited for this reason" 2 "Error" 3 "Not Available" ;
VAL_ 2565944062 DCACAccryInv5PwrLmtDTUndefndRsn 0 "No power limit for this reason" 1 "Power limited for this reason" 2 "Error" 3 "Not Available" ;
VAL_ 2364620286 LaneKeepingAssistStatusRightSide 0 "Lane Keeping Assist Not Available for Right Side" 1 "Lane Keeping Assist Available for Right Side" 2 "Lane Keeping Assist Suppressed for Right Side" 3 "Lane Keeping Assist Active for Right Side" 4 "BlindSpot Assist Active for Right Side" 5 "Reserved" 6 "Error" 7 "Not available" ;
VAL_ 2364620286 LaneKeepingAssistStatusLeftSide 0 "Lane Keeping Assist Not Available for Left Side" 1 "Lane Keeping Assist Available for Left Side" 2 "Lane Keeping Assist Suppressed for Left Side" 3 "Lane Keeping Assist Active for Left Side" 4 "BlindSpot Assist Active for Left Side" 5 "Reserved" 6 "Error" 7 "Not available" ;
VAL_ 2364620286 LaneKeepingAssistIndiEnblStatus 0 "Lane Keeping Assist disabled" 1 "Lane Keeping Assist enabled" 2 "Error" 3 "Not available" ;
VAL_ 2364620286 LaneKeepingAssistSystemState 0 "System is not ready" 1 "System is temporarily not available" 2 "System is deactivated by driver" 3 "System is ready" 4 "Active lane keeping suppressed by operator behavior" 5 "System is actuating" 6 "Reserved" 7 "Reserved" 8 "Reserved" 9 "Reserved" 10 "Reserved" 11 "Reserved" 12 "Reserved" 13 "Reserved" 14 "Error" 15 "Not Available" ;
VAL_ 2364620286 ActiveSteeringDriverPreference 0 "Active Steering Mode #1" 1 "Active Steering Mode #2" 2 "Active Steering Mode #3" 3 "Active Steering Mode #4" 4 "Active Steering Mode #5" 5 "Active Steering Mode #6" 6 "Error" 7 "Not available/Not valid" ;
VAL_ 2364620286 HandsOffDetectionStatus 0 "Hands Off Not Detected" 1 "Hands Off Detected" 2 "Hands Off Detection Disabled" 3 "Reserved" 6 "Error" 7 "Not Available" ;
VAL_ 2364620286 HandsOffDetectionAvailability 0 "Hands Off Detection Not Ready" 1 "Hands Off Detection Temporarily Not Available" 2 "Hands Off Detection Available" 3 "Hands Off Detection Disabled" 4 "Reserved" 6 "Error" 7 "Not Available" ;
VAL_ 2364620286 LaneCntringIndicationEnableState 0 "Lane Centering Indication disabled" 1 "Lane Centering Indication enabled" 2 "Error" 3 "Not available" ;
VAL_ 2364620286 LaneCenteringSystemStatus 0 "System is not ready" 1 "System is temporarily not available" 2 "System is deactivated by driver" 3 "System is ready" 4 "Lane Centering suppressed by operator behavior" 5 "Lane Centering System is actuating" 6 "Reserved" 7 "Reserved" 8 "Reserved" 9 "Reserved" 10 "Reserved" 11 "Reserved" 12 "Reserved" 13 "Reserved" 14 "Error" 15 "Not Available" ;
VAL_ 2364621310 StationaryInvOverllPwrFctrLaggng 0 "Leading" 1 "Lagging" 2 "Error" 3 "Not Available or Not Installed" ;
VAL_ 2364621822 StionaryInvNotRdyToAutoParaStat 0 "Inactive" 1 "Active" 2 "Error" 3 "Not available" ;
VAL_ 2364621822 StationaryInvertAuxShtdwnSwitch 0 "Off" 1 "On" 2 "Error" 3 "Not available" ;
VAL_ 2364622078 StationaryInverterToBusDeadBus 0 "Bus is not dead" 1 "Bus is dead" 2 "Error" 3 "Not Available or Not Installed" ;
VAL_ 2364622078 StationaryInvertToBusPhaseMatch 0 "Phases do not match" 1 "Phases match" 2 "Error" 3 "Not Available or Not Installed" ;
VAL_ 2364622078 StationaryInverterToBusFreqMatch 0 "Frequencies do not match" 1 "Frequencies match" 2 "Error" 3 "Not Available or Not Installed" ;
VAL_ 2364622078 StationaryInvertToBusVltgMatch 0 "Voltages do not match" 1 "Voltages match" 2 "Error" 3 "Not Available or Not Installed" ;
VAL_ 2364622078 StationaryInverterToBusInSync 0 "Not synchronized" 1 "Synchronized" 2 "Error" 3 "Not Available or Not Installed" ;
